VERSION "dbc-export 1 2026.26.6.5"

NS_ :

BS_:

BU_: APP BMS CC CMP CMPD CP DAS DI DIF DIR EPBL EPBR EVSE FC GTW HCML HCMR HVP ICR PCS PCS2 PM PMF PMR PTC SCCM SDCR TAS UMC V2G VC VCBATT VCBATT1 VCBATT2 VCFRONT VCFRONT1 VCLEFT VCRIGHT VCSEC

BO_ 537 VCSEC_TPMSData: 7 VCSEC
 SG_ VCSEC_TPMSDataIndex M : 0|3@1+ (1,0) [0|7] "" Vector__XXX
 SG_ VCSEC_TPMSCapabilityPressureInAd m0 : 3|1@1+ (1,0) [0|1] "" Vector__XXX
 SG_ VCSEC_TPMSCapabilityConfigurable m0 : 4|1@1+ (1,0) [0|1] "" Vector__XXX
 SG_ VCSEC_TPMSPressureRateOfChange0 m0 : 5|10@1- (0.02,0) [-10.24|10.22] "kPa/S" Vector__XXX
 SG_ VCSEC_TPMSPressure0 m0 : 15|9@1+ (0.025,0) [0|12.75] "bar" Vector__XXX
 SG_ VCSEC_TPMSTemperature0 m0 : 24|8@1+ (1,-40) [-40|214] "degC" Vector__XXX
 SG_ VCSEC_TPMSBatVoltage0 m0 : 32|8@1+ (0.01,1.5) [1.5|4.04] "V" Vector__XXX
 SG_ VCSEC_TPMSLocation0 m0 : 40|3@1+ (1,0) [0|7] "" Vector__XXX
 SG_ VCSEC_TPMSTemperatureCompensated m0 : 43|9@1+ (0.025,0) [0|12.75] "bar" Vector__XXX
 SG_ VCSEC_TPMSCapabilityPressur_0001 m1 : 3|1@1+ (1,0) [0|1] "" Vector__XXX
 SG_ VCSEC_TPMSCapabilityConfigu_0001 m1 : 4|1@1+ (1,0) [0|1] "" Vector__XXX
 SG_ VCSEC_TPMSPressureRateOfChange1 m1 : 5|10@1- (0.02,0) [-10.24|10.22] "kPa/S" Vector__XXX
 SG_ VCSEC_TPMSPressure1 m1 : 15|9@1+ (0.025,0) [0|12.75] "bar" Vector__XXX
 SG_ VCSEC_TPMSTemperature1 m1 : 24|8@1+ (1,-40) [-40|214] "degC" Vector__XXX
 SG_ VCSEC_TPMSBatVoltage1 m1 : 32|8@1+ (0.01,1.5) [1.5|4.04] "V" Vector__XXX
 SG_ VCSEC_TPMSLocation1 m1 : 40|3@1+ (1,0) [0|7] "" Vector__XXX
 SG_ VCSEC_TPMSTemperatureCompen_0001 m1 : 43|9@1+ (0.025,0) [0|12.75] "bar" Vector__XXX
 SG_ VCSEC_TPMSCapabilityPressur_0002 m2 : 3|1@1+ (1,0) [0|1] "" Vector__XXX
 SG_ VCSEC_TPMSCapabilityConfigu_0002 m2 : 4|1@1+ (1,0) [0|1] "" Vector__XXX
 SG_ VCSEC_TPMSPressureRateOfChange2 m2 : 5|10@1- (0.02,0) [-10.24|10.22] "kPa/S" Vector__XXX
 SG_ VCSEC_TPMSPressure2 m2 : 15|9@1+ (0.025,0) [0|12.75] "bar" Vector__XXX
 SG_ VCSEC_TPMSTemperature2 m2 : 24|8@1+ (1,-40) [-40|214] "degC" Vector__XXX
 SG_ VCSEC_TPMSBatVoltage2 m2 : 32|8@1+ (0.01,1.5) [1.5|4.04] "V" Vector__XXX
 SG_ VCSEC_TPMSLocation2 m2 : 40|3@1+ (1,0) [0|7] "" Vector__XXX
 SG_ VCSEC_TPMSTemperatureCompen_0002 m2 : 43|9@1+ (0.025,0) [0|12.75] "bar" Vector__XXX
 SG_ VCSEC_TPMSCapabilityPressur_0003 m3 : 3|1@1+ (1,0) [0|1] "" Vector__XXX
 SG_ VCSEC_TPMSCapabilityConfigu_0003 m3 : 4|1@1+ (1,0) [0|1] "" Vector__XXX
 SG_ VCSEC_TPMSPressureRateOfChange3 m3 : 5|10@1- (0.02,0) [-10.24|10.22] "kPa/S" Vector__XXX
 SG_ VCSEC_TPMSPressure3 m3 : 15|9@1+ (0.025,0) [0|12.75] "bar" Vector__XXX
 SG_ VCSEC_TPMSTemperature3 m3 : 24|8@1+ (1,-40) [-40|214] "degC" Vector__XXX
 SG_ VCSEC_TPMSBatVoltage3 m3 : 32|8@1+ (0.01,1.5) [1.5|4.04] "V" Vector__XXX
 SG_ VCSEC_TPMSLocation3 m3 : 40|3@1+ (1,0) [0|7] "" Vector__XXX
 SG_ VCSEC_TPMSTemperatureCompen_0003 m3 : 43|9@1+ (0.025,0) [0|12.75] "bar" Vector__XXX
 SG_ VCSEC_TPMSRecommendedColdPressur m4 : 8|8@1+ (0.025,0) [0|6.35] "bar" Vector__XXX
 SG_ VCSEC_TPMSRecommendedColdPr_0001 m4 : 16|8@1+ (0.025,0) [0|6.35] "bar" Vector__XXX
 SG_ VCSEC_TPMSFeature0 m4 : 24|3@1+ (1,0) [0|7] "" Vector__XXX
 SG_ VCSEC_TPMSFeature1 m4 : 27|3@1+ (1,0) [0|7] "" Vector__XXX
 SG_ VCSEC_TPMSFeature0Count m4 : 32|4@1+ (1,0) [0|15] "" Vector__XXX
 SG_ VCSEC_TPMSFeature0TimeS m4 : 36|11@1+ (1,0) [0|2047] "" Vector__XXX
 SG_ VCSEC_TPMSAutonomyStatus m5 : 3|2@1+ (1,0) [0|3] "" Vector__XXX
 SG_ VCSEC_TPMSAutonomyStatusMIATimeS m5 : 5|9@1+ (1,0) [0|511] "" Vector__XXX
 SG_ VCSEC_TPMSLastKnownPressureFL m5 : 16|8@1+ (0.025,0) [0|6.35] "bar" Vector__XXX
 SG_ VCSEC_TPMSLastKnownPressureFR m5 : 24|8@1+ (0.025,0) [0|6.35] "bar" Vector__XXX
 SG_ VCSEC_TPMSLastKnownPressureRL m5 : 32|8@1+ (0.025,0) [0|6.35] "bar" Vector__XXX
 SG_ VCSEC_TPMSLastKnownPressureRR m5 : 40|8@1+ (0.025,0) [0|6.35] "bar" Vector__XXX

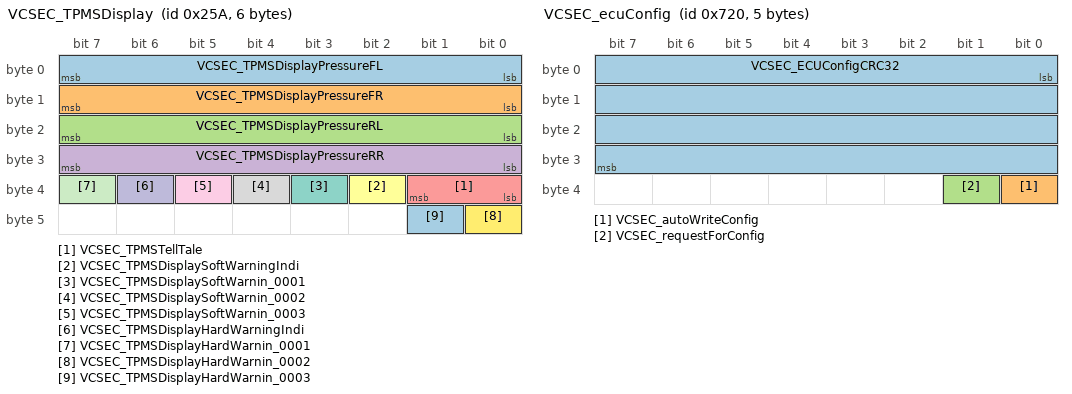
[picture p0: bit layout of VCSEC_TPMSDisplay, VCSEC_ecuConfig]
BO_ 602 VCSEC_TPMSDisplay: 6 VCSEC
 SG_ VCSEC_TPMSDisplayPressureFL : 0|8@1+ (0.025,0) [0|6.35] "bar" Vector__XXX
 SG_ VCSEC_TPMSDisplayPressureFR : 8|8@1+ (0.025,0) [0|6.35] "bar" Vector__XXX
 SG_ VCSEC_TPMSDisplayPressureRL : 16|8@1+ (0.025,0) [0|6.35] "bar" Vector__XXX
 SG_ VCSEC_TPMSDisplayPressureRR : 24|8@1+ (0.025,0) [0|6.35] "bar" Vector__XXX
 SG_ VCSEC_TPMSTellTale : 32|2@1+ (1,0) [0|3] "" Vector__XXX
 SG_ VCSEC_TPMSDisplaySoftWarningIndi : 34|1@1+ (1,0) [0|1] "" Vector__XXX
 SG_ VCSEC_TPMSDisplaySoftWarnin_0001 : 35|1@1+ (1,0) [0|1] "" Vector__XXX
 SG_ VCSEC_TPMSDisplaySoftWarnin_0002 : 36|1@1+ (1,0) [0|1] "" Vector__XXX
 SG_ VCSEC_TPMSDisplaySoftWarnin_0003 : 37|1@1+ (1,0) [0|1] "" Vector__XXX
 SG_ VCSEC_TPMSDisplayHardWarningIndi : 38|1@1+ (1,0) [0|1] "" Vector__XXX
 SG_ VCSEC_TPMSDisplayHardWarnin_0001 : 39|1@1+ (1,0) [0|1] "" Vector__XXX
 SG_ VCSEC_TPMSDisplayHardWarnin_0002 : 40|1@1+ (1,0) [0|1] "" Vector__XXX
 SG_ VCSEC_TPMSDisplayHardWarnin_0003 : 41|1@1+ (1,0) [0|1] "" Vector__XXX

BO_ 570 VCSEC_TPMSStatus: 8 VCSEC
 SG_ VCSEC_TPMSStatusIndex M : 0|6@1+ (1,0) [0|63] "" Vector__XXX
 SG_ VCSEC_TPMSSystemState : 6|1@1+ (1,0) [0|1] "" Vector__XXX
 SG_ VCSEC_TPMSSensorMACAddress0 m0 : 8|48@1+ (1,0) [0|281474976710655] "" Vector__XXX
 SG_ VCSEC_TPMSSensorMACAddress1 m1 : 8|48@1+ (1,0) [0|281474976710655] "" Vector__XXX
 SG_ VCSEC_TPMSSensorMACAddress2 m2 : 8|48@1+ (1,0) [0|281474976710655] "" Vector__XXX
 SG_ VCSEC_TPMSSensorMACAddress3 m3 : 8|48@1+ (1,0) [0|281474976710655] "" Vector__XXX
 SG_ VCSEC_BLEUnsuccessfulConnEventRa m5 : 8|10@1+ (0.08,0) [0|81.76] "%" Vector__XXX
 SG_ VCSEC_BLEUnsuccessfulConnEv_0001 m7 : 8|10@1+ (0.08,0) [0|81.76] "%" Vector__XXX
 SG_ VCSEC_BLEUnsuccessfulConnEv_0002 m9 : 8|10@1+ (0.08,0) [0|81.76] "%" Vector__XXX
 SG_ VCSEC_BLEUnsuccessfulConnEv_0003 m11 : 8|10@1+ (0.08,0) [0|81.76] "%" Vector__XXX
 SG_ VCSEC_TPMSSensorTIAppCRC0 m12 : 8|32@1+ (1,0) [1|4294967295] "" Vector__XXX
 SG_ VCSEC_TPMSSensorMLXAppCRC0 m12 : 40|24@1+ (1,0) [1|16777215] "" Vector__XXX
 SG_ VCSEC_TPMSSensorTIAppCRC1 m13 : 8|32@1+ (1,0) [1|4294967295] "" Vector__XXX
 SG_ VCSEC_TPMSSensorMLXAppCRC1 m13 : 40|24@1+ (1,0) [1|16777215] "" Vector__XXX
 SG_ VCSEC_TPMSSensorTIAppCRC2 m14 : 8|32@1+ (1,0) [1|4294967295] "" Vector__XXX
 SG_ VCSEC_TPMSSensorMLXAppCRC2 m14 : 40|24@1+ (1,0) [1|16777215] "" Vector__XXX
 SG_ VCSEC_TPMSSensorTIAppCRC3 m15 : 8|32@1+ (1,0) [1|4294967295] "" Vector__XXX
 SG_ VCSEC_TPMSSensorMLXAppCRC3 m15 : 40|24@1+ (1,0) [1|16777215] "" Vector__XXX
 SG_ VCSEC_TPMStotalAwakeTime0 m20 : 8|32@1+ (1,0) [0|4294967295] "" Vector__XXX
 SG_ VCSEC_TPMSTrimAdjusted0 m20 : 40|1@1+ (1,0) [0|1] "" Vector__XXX
 SG_ VCSEC_TPMSGenealogySensorState0 m20 : 41|3@1+ (1,0) [0|7] "" Vector__XXX
 SG_ VCSEC_TPMSSensorType0 m20 : 44|3@1+ (1,0) [0|7] "" Vector__XXX
 SG_ VCSEC_TPMStotalAwakeTime1 m21 : 8|32@1+ (1,0) [0|4294967295] "" Vector__XXX
 SG_ VCSEC_TPMSTrimAdjusted1 m21 : 40|1@1+ (1,0) [0|1] "" Vector__XXX
 SG_ VCSEC_TPMSGenealogySensorState1 m21 : 41|3@1+ (1,0) [0|7] "" Vector__XXX
 SG_ VCSEC_TPMSSensorType1 m21 : 44|3@1+ (1,0) [0|7] "" Vector__XXX
 SG_ VCSEC_TPMStotalAwakeTime2 m22 : 8|32@1+ (1,0) [0|4294967295] "" Vector__XXX
 SG_ VCSEC_TPMSTrimAdjusted2 m22 : 40|1@1+ (1,0) [0|1] "" Vector__XXX
 SG_ VCSEC_TPMSGenealogySensorState2 m22 : 41|3@1+ (1,0) [0|7] "" Vector__XXX
 SG_ VCSEC_TPMSSensorType2 m22 : 44|3@1+ (1,0) [0|7] "" Vector__XXX
 SG_ VCSEC_TPMStotalAwakeTime3 m23 : 8|32@1+ (1,0) [0|4294967295] "" Vector__XXX
 SG_ VCSEC_TPMSTrimAdjusted3 m23 : 40|1@1+ (1,0) [0|1] "" Vector__XXX
 SG_ VCSEC_TPMSGenealogySensorState3 m23 : 41|3@1+ (1,0) [0|7] "" Vector__XXX
 SG_ VCSEC_TPMSSensorType3 m23 : 44|3@1+ (1,0) [0|7] "" Vector__XXX
 SG_ VCSEC_TPMSSensor0Hash m33 : 8|28@1+ (1,0) [0|268435455] "" Vector__XXX
 SG_ VCSEC_TPMSSensor1Hash m33 : 36|28@1+ (1,0) [0|268435455] "" Vector__XXX
 SG_ VCSEC_TPMSSensor2Hash m34 : 8|28@1+ (1,0) [0|268435455] "" Vector__XXX
 SG_ VCSEC_TPMSSensor3Hash m34 : 36|28@1+ (1,0) [0|268435455] "" Vector__XXX
 SG_ VCSEC_TPMSLastLocationSensor0 m35 : 8|3@1+ (1,0) [0|7] "" Vector__XXX
 SG_ VCSEC_TPMSLastLocationSensor1 m35 : 11|3@1+ (1,0) [0|7] "" Vector__XXX
 SG_ VCSEC_TPMSLastLocationSensor2 m35 : 16|3@1+ (1,0) [0|7] "" Vector__XXX
 SG_ VCSEC_TPMSLastLocationSensor3 m35 : 19|3@1+ (1,0) [0|7] "" Vector__XXX
 SG_ VCSEC_TPMSTemperatureCompensated m36 : 8|8@1+ (0.01,1.5) [1.5|4.04] "V" Vector__XXX
 SG_ VCSEC_TPMSTemperatureCompen_0001 m36 : 16|8@1+ (0.01,1.5) [1.5|4.04] "V" Vector__XXX
 SG_ VCSEC_TPMSTemperatureCompen_0002 m36 : 24|8@1+ (0.01,1.5) [1.5|4.04] "V" Vector__XXX
 SG_ VCSEC_TPMSTemperatureCompen_0003 m36 : 32|8@1+ (0.01,1.5) [1.5|4.04] "V" Vector__XXX
 SG_ VCSEC_TPMSFilteredBatVoltage0 m37 : 8|8@1+ (0.01,1.5) [1.5|4.04] "V" Vector__XXX
 SG_ VCSEC_TPMSFilteredBatVoltage2 m37 : 16|8@1+ (0.01,1.5) [1.5|4.04] "V" Vector__XXX
 SG_ VCSEC_TPMSFilteredBatVoltage1 m37 : 24|8@1+ (0.01,1.5) [1.5|4.04] "V" Vector__XXX
 SG_ VCSEC_TPMSFilteredBatVoltage3 m37 : 32|8@1+ (0.01,1.5) [1.5|4.04] "V" Vector__XXX

BO_ 1067 VCSEC_UWBData: 8 VCSEC
 SG_ VCSEC_UWBEndpointIndex M : 0|3@1+ (1,0) [0|7] "" Vector__XXX
 SG_ VCSEC_UWBExpectedEndpointsActive m0 : 3|4@1+ (1,0) [0|15] "" Vector__XXX
 SG_ VCSEC_UWBExpectedEndpointsA_0001 m0 : 8|4@1+ (1,0) [0|15] "" Vector__XXX
 SG_ VCSEC_UWBExpectedEndpointsA_0002 m0 : 12|4@1+ (1,0) [0|15] "" Vector__XXX
 SG_ VCSEC_UWBExpectedEndpointsA_0003 m0 : 16|4@1+ (1,0) [0|15] "" Vector__XXX
 SG_ VCSEC_UWBRearRightDistance0 m0 : 20|12@1+ (1,0) [0|4094] "cm" Vector__XXX
 SG_ VCSEC_UWBRearRightDistance1 m0 : 32|12@1+ (1,0) [0|4094] "cm" Vector__XXX
 SG_ VCSEC_UWBRearRightDistance2 m0 : 44|12@1+ (1,0) [0|4094] "cm" Vector__XXX
 SG_ VCSEC_UWBLeftDistance3 m1 : 3|12@1+ (1,0) [0|4094] "cm" Vector__XXX
 SG_ VCSEC_UWBRightDistance3 m1 : 16|12@1+ (1,0) [0|4094] "cm" Vector__XXX
 SG_ VCSEC_UWBRearRightDistance3 m1 : 28|12@1+ (1,0) [0|4094] "cm" Vector__XXX
 SG_ VCSEC_UWBRearLeftDistance3 m1 : 40|12@1+ (1,0) [0|4094] "cm" Vector__XXX
 SG_ VCSEC_UWBCenterDistance3 m1 : 52|12@1+ (1,0) [0|4094] "cm" Vector__XXX
 SG_ VCSEC_UWBLeftDistance2 m2 : 3|12@1+ (1,0) [0|4094] "cm" Vector__XXX
 SG_ VCSEC_UWBRightDistance2 m2 : 16|12@1+ (1,0) [0|4094] "cm" Vector__XXX
 SG_ VCSEC_UWBRearDistance2 m2 : 28|12@1+ (1,0) [0|4094] "cm" Vector__XXX
 SG_ VCSEC_UWBRearLeftDistance2 m2 : 40|12@1+ (1,0) [0|4094] "cm" Vector__XXX
 SG_ VCSEC_UWBCenterDistance2 m2 : 52|12@1+ (1,0) [0|4094] "cm" Vector__XXX
 SG_ VCSEC_UWBLeftDistance1 m3 : 3|12@1+ (1,0) [0|4094] "cm" Vector__XXX
 SG_ VCSEC_UWBRightDistance1 m3 : 16|12@1+ (1,0) [0|4094] "cm" Vector__XXX
 SG_ VCSEC_UWBRearDistance1 m3 : 28|12@1+ (1,0) [0|4094] "cm" Vector__XXX
 SG_ VCSEC_UWBRearLeftDistance1 m3 : 40|12@1+ (1,0) [0|4094] "cm" Vector__XXX
 SG_ VCSEC_UWBCenterDistance1 m3 : 52|12@1+ (1,0) [0|4094] "cm" Vector__XXX
 SG_ VCSEC_UWBLeftDistance0 m4 : 3|12@1+ (1,0) [0|4094] "cm" Vector__XXX
 SG_ VCSEC_UWBRightDistance0 m4 : 16|12@1+ (1,0) [0|4094] "cm" Vector__XXX
 SG_ VCSEC_UWBRearDistance0 m4 : 28|12@1+ (1,0) [0|4094] "cm" Vector__XXX
 SG_ VCSEC_UWBRearLeftDistance0 m4 : 40|12@1+ (1,0) [0|4094] "cm" Vector__XXX
 SG_ VCSEC_UWBCenterDistance0 m4 : 52|12@1+ (1,0) [0|4094] "cm" Vector__XXX

BO_ 761 VCSEC_additionalAuthInfo: 8 VCSEC
 SG_ VCSEC_activeKeyDebug : 2|5@1+ (1,0) [0|31] "" Vector__XXX
 SG_ VCSEC_bleChannelDisconnected : 7|4@1+ (1,0) [0|15] "" Vector__XXX
 SG_ VCSEC_bleDisconnectionReason : 11|8@1+ (1,0) [0|255] "" Vector__XXX
 SG_ VCSEC_bleConnetionAttemptWLEntry : 19|5@1+ (1,0) [0|31] "" Vector__XXX
 SG_ VCSEC_AdditionalAuthInfoIndex M : 27|3@1+ (1,0) [0|7] "" Vector__XXX
 SG_ VCSEC_activeKeyReason m0 : 24|3@1+ (1,0) [0|7] "" Vector__XXX
 SG_ VCSEC_activeKeySHA1 m0 : 32|32@1+ (1,0) [0|4294967295] "" Vector__XXX
 SG_ VCSEC_algoUsedForSummonRange0 m1 : 0|1@1+ (1,0) [0|1] "" Vector__XXX
 SG_ VCSEC_keyWithinSummonRange0 m1 : 32|32@1+ (1,0) [0|4294967295] "" Vector__XXX
 SG_ VCSEC_algoUsedForSummonRange1 m2 : 0|1@1+ (1,0) [0|1] "" Vector__XXX
 SG_ VCSEC_keyWithinSummonRange1 m2 : 32|32@1+ (1,0) [0|4294967295] "" Vector__XXX
 SG_ VCSEC_algoUsedForSummonRange2 m3 : 0|1@1+ (1,0) [0|1] "" Vector__XXX
 SG_ VCSEC_keyWithinSummonRange2 m3 : 32|32@1+ (1,0) [0|4294967295] "" Vector__XXX
 SG_ VCSEC_BLEDeviceWithinSummonRange m4 : 32|32@1+ (1,0) [0|4294967295] "" Vector__XXX
 SG_ VCSEC_algoUWBInteriorPresence m5 : 0|1@1+ (1,0) [0|1] "" Vector__XXX
 SG_ VCSEC_frunkOpenSuggestionRespons m5 : 24|3@1+ (1,0) [0|7] "" Vector__XXX
 SG_ VCSEC_NFCAuthFromBPillarFormFact m5 : 32|3@1+ (1,0) [0|7] "" Vector__XXX
 SG_ VCSEC_NFCAuthFromCenterConsoleFo m5 : 35|3@1+ (1,0) [0|7] "" Vector__XXX
 SG_ VCSEC_trunkOpenSuggestionRespons m5 : 40|3@1+ (1,0) [0|7] "" Vector__XXX
 SG_ VCSEC_algoTrunkSuggestionRaw m5 : 43|1@1+ (1,0) [0|1] "" Vector__XXX
 SG_ VCSEC_algoTrunkSuggestionProc m5 : 44|1@1+ (1,0) [0|1] "" Vector__XXX
 SG_ VCSEC_algoTrunkSuggestionRearmAl m5 : 45|1@1+ (1,0) [0|1] "" Vector__XXX
 SG_ VCSEC_algoFrunkSuggestionRaw m5 : 46|1@1+ (1,0) [0|1] "" Vector__XXX
 SG_ VCSEC_algoFrunkSuggestionProc m5 : 47|1@1+ (1,0) [0|1] "" Vector__XXX
 SG_ VCSEC_algoFrunkSuggestionRearmAl m5 : 48|1@1+ (1,0) [0|1] "" Vector__XXX

BO_ 825 VCSEC_authentication: 8 VCSEC
 SG_ VCSEC_BLEConnectionCounter : 0|4@1+ (1,0) [0|15] "" Vector__XXX
 SG_ VCSEC_authRejectionReason : 4|3@1+ (1,0) [0|7] "" Vector__XXX
 SG_ VCSEC_IDRequested : 7|1@1+ (1,0) [0|1] "" Vector__XXX
 SG_ VCSEC_operationMode : 8|2@1+ (1,0) [0|3] "" Vector__XXX
 SG_ VCSEC_vehicleLockStatus : 12|4@1+ (1,0) [1|15] "" Vector__XXX
 SG_ VCSEC_authenticationStatus : 16|2@1+ (1,0) [0|3] "" Vector__XXX
 SG_ VCSEC_chargePortLockStatus : 18|1@1+ (1,0) [0|1] "" Vector__XXX
 SG_ VCSEC_leftFrontLockStatus : 19|1@1+ (1,0) [0|1] "" Vector__XXX
 SG_ VCSEC_leftRearLockStatus : 20|1@1+ (1,0) [0|1] "" Vector__XXX
 SG_ VCSEC_rightFrontLockStatus : 21|1@1+ (1,0) [0|1] "" Vector__XXX
 SG_ VCSEC_rightRearLockStatus : 22|1@1+ (1,0) [0|1] "" Vector__XXX
 SG_ VCSEC_trunkLockStatus : 23|1@1+ (1,0) [0|1] "" Vector__XXX
 SG_ VCSEC_lockRequestType : 24|5@1+ (1,0) [0|31] "" Vector__XXX
 SG_ VCSEC_summonRequest : 29|3@1+ (1,0) [0|7] "" Vector__XXX
 SG_ VCSEC_3rdPartyPLGRequest : 32|2@1+ (1,0) [0|2] "" Vector__XXX
 SG_ VCSEC_3rdPartyFrunkPLGRequest : 34|2@1+ (1,0) [0|2] "" Vector__XXX
 SG_ VCSEC_MCUCommandType : 36|3@1+ (1,0) [0|7] "" Vector__XXX
 SG_ VCSEC_frunkLockStatus : 39|1@1+ (1,0) [0|1] "" Vector__XXX
 SG_ VCSEC_usingModifiedMACAddress : 40|1@1+ (1,0) [0|1] "" Vector__XXX
 SG_ VCSEC_isKeyWithinSummonRange : 41|1@1+ (1,0) [0|1] "" Vector__XXX
 SG_ VCSEC_isBLEDeviceWithinSummonRan : 42|1@1+ (1,0) [0|1] "" Vector__XXX
 SG_ VCSEC_alarmStatus : 43|4@1+ (1,0) [0|14] "" Vector__XXX
 SG_ VCSEC_serviceDiagnosticRequest : 47|1@1+ (1,0) [0|1] "" Vector__XXX
 SG_ VCSEC_immobilizerState : 48|3@1+ (1,0) [0|7] "" Vector__XXX
 SG_ VCSEC_lockIndicationRequest : 51|3@1+ (1,0) [1|7] "" Vector__XXX
 SG_ VCSEC_simpleLockStatus : 54|2@1+ (1,0) [1|3] "" Vector__XXX
 SG_ VCSEC_keyChannelIndexed : 56|4@1+ (1,0) [0|14] "" Vector__XXX
 SG_ VCSEC_authRequested : 60|1@1+ (1,0) [0|1] "" Vector__XXX
 SG_ VCSEC_remoteStartActive : 61|2@1+ (1,0) [0|3] "" Vector__XXX
 SG_ VCSEC_keyPairDesired : 63|1@1+ (1,0) [0|1] "" Vector__XXX

BO_ 1817 VCSEC_debug100ms: 8 VCSEC
 SG_ VCSEC_debug100msIndex M : 0|5@1+ (1,0) [0|31] "" Vector__XXX
 SG_ VCSEC_walkAwayLockKeyState m0 : 5|2@1+ (1,0) [0|3] "" Vector__XXX
 SG_ VCSEC_thresholdOffsetVersion m0 : 8|3@1+ (1,0) [0|7] "" Vector__XXX
 SG_ VCSEC_walkAwayLockState m0 : 11|3@1+ (1,0) [0|7] "" Vector__XXX
 SG_ VCSEC_rssi0WLEntry m0 : 16|5@1+ (1,0) [0|31] "" Vector__XXX
 SG_ VCSEC_endpointLayout m0 : 21|2@1+ (1,0) [0|3] "" Vector__XXX
 SG_ VCSEC_rssi1WLEntry m0 : 24|5@1+ (1,0) [0|31] "" Vector__XXX
 SG_ VCSEC_rssi2WLEntry m0 : 32|5@1+ (1,0) [0|31] "" Vector__XXX
 SG_ VCSEC_walkUpUnlockState m0 : 37|3@1+ (1,0) [0|7] "" Vector__XXX
 SG_ VCSEC_algoHighThreshLeft m0 : 40|1@1+ (1,0) [0|1] "" Vector__XXX
 SG_ VCSEC_algoHighThreshRight m0 : 41|1@1+ (1,0) [0|1] "" Vector__XXX
 SG_ VCSEC_algoHighThreshCenter m0 : 42|1@1+ (1,0) [0|1] "" Vector__XXX
 SG_ VCSEC_pollingReason m0 : 43|4@1+ (1,0) [0|15] "" Vector__XXX
 SG_ VCSEC_numberOfPubKeysOnWhitelist m0 : 48|5@1+ (1,0) [0|31] "" Vector__XXX
 SG_ VCSEC_thermalDetectState m0 : 53|2@1+ (1,0) [0|3] "" Vector__XXX
 SG_ VCSEC_chargeHandleMitigationActi m0 : 55|1@1+ (1,0) [0|1] "" Vector__XXX
 SG_ VCSEC_smartTrunkMitigatedKeyCoun m5 : 8|5@1+ (1,0) [0|31] "" Vector__XXX
 SG_ VCSEC_UWB3WLEntry m5 : 21|5@1+ (1,0) [0|31] "" Vector__XXX
 SG_ VCSEC_device0Offset m5 : 26|6@1- (0.5,0) [-16|15.5] "dBm" Vector__XXX
 SG_ VCSEC_device1Offset m5 : 32|6@1- (0.5,0) [-16|15.5] "dBm" Vector__XXX
 SG_ VCSEC_device2Offset m5 : 40|6@1- (0.5,0) [-16|15.5] "dBm" Vector__XXX
 SG_ VCSEC_connection0BondingState m7 : 8|4@1+ (1,0) [0|15] "" Vector__XXX
 SG_ VCSEC_connection1BondingState m7 : 12|4@1+ (1,0) [0|15] "" Vector__XXX
 SG_ VCSEC_connection2BondingState m7 : 16|4@1+ (1,0) [0|15] "" Vector__XXX
 SG_ VCSEC_connection0UWBAvailability m7 : 24|5@1+ (1,0) [0|31] "" Vector__XXX
 SG_ VCSEC_connection1UWBAvailability m7 : 32|5@1+ (1,0) [0|31] "" Vector__XXX
 SG_ VCSEC_connection2UWBAvailability m7 : 40|5@1+ (1,0) [0|31] "" Vector__XXX
 SG_ VCSEC_NISessionStateCenter0 m8 : 8|5@1+ (1,0) [0|31] "" Vector__XXX
 SG_ VCSEC_NISessionStateLeft0 m8 : 16|5@1+ (1,0) [0|31] "" Vector__XXX
 SG_ VCSEC_NISessionStateRight0 m8 : 24|5@1+ (1,0) [0|31] "" Vector__XXX
 SG_ VCSEC_NISessionStateRearLeft0 m8 : 29|5@1+ (1,0) [0|31] "" Vector__XXX
 SG_ VCSEC_NISessionStateRearRight0 m8 : 34|5@1+ (1,0) [0|31] "" Vector__XXX
 SG_ VCSEC_NISessionStateRear0 m8 : 39|5@1+ (1,0) [0|31] "" Vector__XXX
 SG_ VCSEC_NISessionStateCenter1 m8 : 44|5@1+ (1,0) [0|31] "" Vector__XXX
 SG_ VCSEC_NISessionStateLeft1 m8 : 49|5@1+ (1,0) [0|31] "" Vector__XXX
 SG_ VCSEC_NISessionStateRight1 m8 : 54|5@1+ (1,0) [0|31] "" Vector__XXX
 SG_ VCSEC_NISessionStateRearLeft1 m8 : 59|5@1+ (1,0) [0|31] "" Vector__XXX
 SG_ VCSEC_NISessionStateRearRight1 m9 : 8|5@1+ (1,0) [0|31] "" Vector__XXX
 SG_ VCSEC_NISessionStateRear1 m9 : 16|5@1+ (1,0) [0|31] "" Vector__XXX
 SG_ VCSEC_NISessionStateCenter2 m9 : 24|5@1+ (1,0) [0|31] "" Vector__XXX
 SG_ VCSEC_NISessionStateLeft2 m9 : 32|5@1+ (1,0) [0|31] "" Vector__XXX
 SG_ VCSEC_NISessionStateRight2 m9 : 40|5@1+ (1,0) [0|31] "" Vector__XXX
 SG_ VCSEC_NISessionStateRearLeft2 m9 : 48|5@1+ (1,0) [0|31] "" Vector__XXX
 SG_ VCSEC_NISessionStateRearRight2 m9 : 53|5@1+ (1,0) [0|31] "" Vector__XXX
 SG_ VCSEC_NISessionStateRear2 m9 : 58|5@1+ (1,0) [0|31] "" Vector__XXX
 SG_ VCSEC_NISessionStateLeft3 m10 : 8|5@1+ (1,0) [0|31] "" Vector__XXX
 SG_ VCSEC_NISessionStateRight3 m10 : 16|5@1+ (1,0) [0|31] "" Vector__XXX
 SG_ VCSEC_NISessionStateRearRight3 m10 : 24|5@1+ (1,0) [0|31] "" Vector__XXX
 SG_ VCSEC_NISessionStateRearLeft3 m10 : 32|5@1+ (1,0) [0|31] "" Vector__XXX
 SG_ VCSEC_NISessionStateCenter3 m10 : 40|5@1+ (1,0) [0|31] "" Vector__XXX

BO_ 1824 VCSEC_ecuConfig: 5 VCSEC
 SG_ VCSEC_ECUConfigCRC32 : 0|32@1+ (1,0) [0|4294967295] "" Vector__XXX
 SG_ VCSEC_autoWriteConfig : 32|1@1+ (1,0) [0|1] "" Vector__XXX
 SG_ VCSEC_requestForConfig : 33|1@1+ (1,0) [0|1] "" Vector__XXX

BO_ 793 VCSEC_info: 8 VCSEC
 SG_ VCSEC_infoIndex M : 0|8@1+ (1,0) [0|255] "" Vector__XXX
 SG_ VCSEC_infoBuildType m10 : 8|3@1+ (1,0) [0|7] "" Vector__XXX
 SG_ VCSEC_infoBuildConfigId m10 : 16|16@1+ (1,0) [0|65535] "" Vector__XXX
 SG_ VCSEC_infoHardwareId m10 : 32|16@1+ (1,0) [0|65535] "" Vector__XXX
 SG_ VCSEC_infoComponentId m10 : 48|16@1+ (1,0) [0|65535] "" Vector__XXX
 SG_ VCSEC_infoPcbaId m11 : 8|8@1+ (1,0) [0|255] "" Vector__XXX
 SG_ VCSEC_infoAssemblyId m11 : 16|8@1+ (1,0) [0|254] "" Vector__XXX
 SG_ VCSEC_infoUsageId m11 : 32|16@1+ (1,0) [0|65535] "" Vector__XXX
 SG_ VCSEC_infoSubUsageId m11 : 48|16@1+ (1,0) [0|65535] "" Vector__XXX
 SG_ VCSEC_infoAppCrc m13 : 32|32@1+ (1,0) [0|4294967295] "" Vector__XXX
 SG_ VCSEC_infoSubcomponent1 m16 : 32|32@1+ (1,0) [0|4294967295] "" Vector__XXX
 SG_ VCSEC_infoAppGitHash m17 : 8|56@1+ (1,0) [0|7.20575940379e+16] "" Vector__XXX
 SG_ VCSEC_infoBootGitHash m18 : 8|56@1+ (1,0) [0|7.20575940379e+16] "" Vector__XXX
 SG_ VCSEC_infoPlatformType m19 : 8|8@1+ (1,0) [0|255] "" Vector__XXX
 SG_ VCSEC_infoBootUdsProtoVersion m20 : 8|16@1+ (1,0) [0|65535] "" Vector__XXX
 SG_ VCSEC_infoBootCrc m20 : 24|32@1+ (1,0) [0|4294967295] "" Vector__XXX
 SG_ VCSEC_infoSubcomponent2 m23 : 32|32@1+ (1,0) [0|4294967295] "" Vector__XXX
 SG_ VCSEC_infoSubcomponent3 m24 : 32|32@1+ (1,0) [0|4294967295] "" Vector__XXX
 SG_ VCSEC_infoSubcomponent4 m31 : 32|32@1+ (1,0) [0|4294967295] "" Vector__XXX

BO_ 505 VCSEC_requests: 8 VCSEC
 SG_ VCSEC_chargePortRequest : 0|2@1+ (1,0) [0|2] "" Vector__XXX
 SG_ VCSEC_presentHandles : 4|1@1+ (1,0) [0|1] "" Vector__XXX
 SG_ VCSEC_frontLeftClosureRequest : 5|3@1+ (1,0) [0|7] "" Vector__XXX
 SG_ VCSEC_frontRightClosureRequest : 8|3@1+ (1,0) [0|7] "" Vector__XXX
 SG_ VCSEC_rearLeftClosureRequest : 11|3@1+ (1,0) [0|7] "" Vector__XXX
 SG_ VCSEC_rearRightClosureRequest : 14|3@1+ (1,0) [0|7] "" Vector__XXX
 SG_ VCSEC_rearTrunkClosureRequest : 17|3@1+ (1,0) [0|7] "" Vector__XXX
 SG_ VCSEC_frontLeftRequestReason : 20|3@1+ (1,0) [0|7] "" Vector__XXX
 SG_ VCSEC_frontRightRequestReason : 23|3@1+ (1,0) [0|7] "" Vector__XXX
 SG_ VCSEC_rearLeftRequestReason : 26|3@1+ (1,0) [0|7] "" Vector__XXX
 SG_ VCSEC_rearRightRequestReason : 29|3@1+ (1,0) [0|7] "" Vector__XXX
 SG_ VCSEC_rearTrunkRequestReason : 32|3@1+ (1,0) [0|7] "" Vector__XXX
 SG_ VCSEC_rdMapDumpRequested : 35|1@1+ (1,0) [0|1] "" Vector__XXX
 SG_ VCSEC_driveAttemptedWithoutAuth : 36|4@1+ (1,0) [0|15] "" Vector__XXX
 SG_ VCSEC_closeAllStatus : 41|2@1+ (1,0) [0|3] "" Vector__XXX
 SG_ VCSEC_snapshotRequested : 43|4@1+ (1,0) [0|15] "" Vector__XXX
 SG_ VCSEC_chargeportRequestReason : 47|3@1+ (1,0) [0|7] "" Vector__XXX
 SG_ VCSEC_frontTrunkClosureRequest : 51|3@1+ (1,0) [0|7] "" Vector__XXX
 SG_ VCSEC_frontTrunkRequestReason : 54|3@1+ (1,0) [0|7] "" Vector__XXX

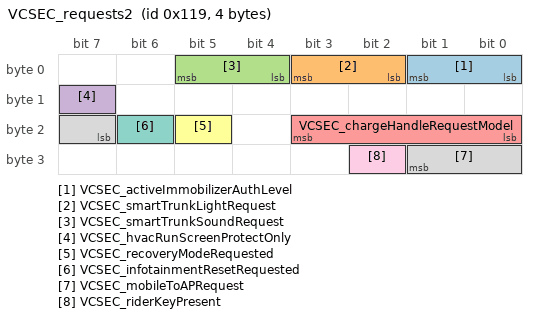
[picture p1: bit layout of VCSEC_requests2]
BO_ 281 VCSEC_requests2: 4 VCSEC
 SG_ VCSEC_activeImmobilizerAuthLevel : 0|2@1+ (1,0) [0|3] "" Vector__XXX
 SG_ VCSEC_smartTrunkLightRequest : 2|2@1+ (1,0) [0|3] "" Vector__XXX
 SG_ VCSEC_smartTrunkSoundRequest : 4|2@1+ (1,0) [0|3] "" Vector__XXX
 SG_ VCSEC_hvacRunScreenProtectOnly : 15|1@1+ (1,0) [0|1] "" Vector__XXX
 SG_ VCSEC_chargeHandleRequestModel : 16|4@1+ (1,0) [0|15] "" Vector__XXX
 SG_ VCSEC_recoveryModeRequested : 21|1@1+ (1,0) [0|1] "" Vector__XXX
 SG_ VCSEC_infotainmentResetRequested : 22|1@1+ (1,0) [0|1] "" Vector__XXX
 SG_ VCSEC_mobileToAPRequest : 23|3@1+ (1,0) [0|7] "" Vector__XXX
 SG_ VCSEC_riderKeyPresent : 26|1@1+ (1,0) [0|1] "" Vector__XXX

BO_ 1850 VC_LVBMS_brickMeasurements: 8 VC
 SG_ VC_LVBMS_brickMeasurementsMultip M : 0|6@1+ (1,0) [0|63] "" Vector__XXX
 SG_ VC_LVBMS_brickVoltage1 m0 : 8|13@1+ (0.001,0) [0|6.535] "V" Vector__XXX
 SG_ VC_LVBMS_brickVoltage2 m0 : 24|13@1+ (0.001,0) [0|6.535] "V" Vector__XXX
 SG_ VC_LVBMS_brickVoltage3 m0 : 37|13@1+ (0.001,0) [0|6.535] "V" Vector__XXX
 SG_ VC_LVBMS_brickVoltage4 m0 : 50|13@1+ (0.001,0) [0|6.535] "V" Vector__XXX
 SG_ VC_LVBMS_brickBalancingAh1 m1 : 8|24@1+ (0.001,0) [0|16777.214] "Ah" Vector__XXX
 SG_ VC_LVBMS_brickBalancingAh2 m1 : 32|24@1+ (0.001,0) [0|16777.214] "Ah" Vector__XXX
 SG_ VC_LVBMS_brickBalancingState1 m1 : 56|1@1+ (1,0) [0|1] "" Vector__XXX
 SG_ VC_LVBMS_brickBalancingState2 m1 : 57|1@1+ (1,0) [0|1] "" Vector__XXX
 SG_ VC_LVBMS_brickBalancingAh3 m2 : 8|24@1+ (0.001,0) [0|16777.214] "Ah" Vector__XXX
 SG_ VC_LVBMS_brickBalancingAh4 m2 : 32|24@1+ (0.001,0) [0|16777.214] "Ah" Vector__XXX
 SG_ VC_LVBMS_brickBalancingState3 m2 : 56|1@1+ (1,0) [0|1] "" Vector__XXX
 SG_ VC_LVBMS_brickBalancingState4 m2 : 57|1@1+ (1,0) [0|1] "" Vector__XXX

BO_ 1655 VC_LVBMS_statusHigh: 8 VC
 SG_ VC_lvbmsStatusHighIndex M : 0|3@1+ (1,0) [0|7] "" Vector__XXX
 SG_ VC_LVBMS_packCurrent m0 : 3|22@1+ (0.001,-2000) [-2000|2194.302] "A" Vector__XXX
 SG_ VC_LVBMS_packVoltage m0 : 25|16@1+ (0.001,0) [0|65.534] "V" Vector__XXX
 SG_ VC_LVBMS_packTemperature m0 : 41|9@1+ (0.5,-50) [-50|205] "degC" Vector__XXX
 SG_ VC_LVBMS_MOSTemperature m0 : 50|12@1+ (0.5,-50) [-50|1997] "degC" Vector__XXX
 SG_ VC_LVBMS_sumCellVoltage m1 : 8|16@1+ (0.001,0) [0|65.534] "V" Vector__XXX
 SG_ VC_LVBMS_maxBrickVoltage m1 : 24|13@1+ (0.001,0) [0|8.19] "V" Vector__XXX
 SG_ VC_LVBMS_maxBrickVoltageIndex m1 : 40|8@1+ (1,0) [0|254] "" Vector__XXX
 SG_ VC_totalLVLoadCurrent m2 : 8|14@1- (0.1,0) [-200|400] "A" Vector__XXX
 SG_ VC_LVPackChargeCurrentLimit m2 : 22|12@1+ (0.1,0) [0|400] "A" Vector__XXX
 SG_ VC_LVPackCurrent m2 : 34|14@1- (0.1,0) [-200|400] "A" Vector__XXX
 SG_ VC_LVBMS_estimatedPackOcv m2 : 48|16@1+ (0.001,0) [0|65.535] "V" Vector__XXX
 SG_ VC_LVBMS_voltageTarget m3 : 3|16@1+ (0.001,0) [0|65.534] "V" Vector__XXX
 SG_ VC_LVBMS_currentTarget m3 : 19|18@1+ (0.001,-122) [-120|120] "A" Vector__XXX
 SG_ VC_LVBMS_maxAllowedChargeCurrent m3 : 37|13@1+ (0.1,0) [0|819] "A" Vector__XXX
 SG_ VC_LVBMS_maxAllowedDischargeCurr m3 : 50|13@1+ (0.1,0) [0|819] "A" Vector__XXX
 SG_ VC_LVBMS_MOSCommand m4 : 3|1@1+ (1,0) [0|1] "" Vector__XXX
 SG_ VC_LVBMS_ClearErrorCntrCommand m4 : 4|1@1+ (1,0) [0|1] "" Vector__XXX
 SG_ VC_LVBMS_ClearHistoricFaultComma m4 : 5|1@1+ (1,0) [0|1] "" Vector__XXX
 SG_ VC_LVBMS_ResetLVBMSCommand m4 : 6|1@1+ (1,0) [0|1] "" Vector__XXX
 SG_ VC_LVBMS_EnterHibernationCommand m4 : 7|1@1+ (1,0) [0|1] "" Vector__XXX
 SG_ VC_LVBMS_ECPAState m4 : 8|2@1+ (1,0) [0|2] "" Vector__XXX
 SG_ VC_LVBMS_MOSState m4 : 10|2@1+ (1,0) [0|2] "" Vector__XXX
 SG_ VC_LVBMS_VehicleState m4 : 12|2@1+ (1,0) [0|3] "" Vector__XXX
 SG_ VC_LVBMS_LINWakeDisabled m4 : 14|1@1+ (1,0) [0|1] "" Vector__XXX
 SG_ VC_LVBMS_chargeType m4 : 16|3@1+ (1,0) [0|7] "" Vector__XXX
 SG_ VC_LVBMS_cellAndArcProtEnabled m4 : 19|1@1+ (1,0) [0|1] "" Vector__XXX
 SG_ VC_LVBMS_avgBrickVoltage m4 : 24|13@1+ (0.001,0) [0|8.19] "V" Vector__XXX
 SG_ VC_LVBMS_minBrickVoltage m4 : 40|13@1+ (0.001,0) [0|8.19] "V" Vector__XXX
 SG_ VC_LVBMS_minBrickVoltageIndex m4 : 56|8@1+ (1,0) [0|254] "" Vector__XXX

BO_ 1816 VC_LVBMS_statusLow: 8 VC
 SG_ VC_lvbmsStatusLowIndex M : 0|3@1+ (1,0) [0|7] "" Vector__XXX
 SG_ VC_LVBMS_SOC m0 : 3|10@1+ (0.1,0) [0|102.2] "%" Vector__XXX
 SG_ VC_LVBMS_SOE m0 : 16|7@1+ (1,0) [0|126] "%" Vector__XXX
 SG_ VC_LVBMS_SOH m0 : 24|7@1+ (1,0) [0|126] "%" Vector__XXX
 SG_ VC_LVBMS_CellOVLevel1 m0 : 31|1@1+ (1,0) [0|1] "" Vector__XXX
 SG_ VC_LVBMS_CellOVLevel2 m0 : 32|1@1+ (1,0) [0|1] "" Vector__XXX
 SG_ VC_LVBMS_CellOVLevel3 m0 : 33|1@1+ (1,0) [0|1] "" Vector__XXX
 SG_ VC_LVBMS_CellUVLevel1 m0 : 34|1@1+ (1,0) [0|1] "" Vector__XXX
 SG_ VC_LVBMS_CellUVLevel2 m0 : 35|1@1+ (1,0) [0|1] "" Vector__XXX
 SG_ VC_LVBMS_ModuleOTLevel1 m0 : 36|1@1+ (1,0) [0|1] "" Vector__XXX
 SG_ VC_LVBMS_PackOVLevel1 m0 : 37|1@1+ (1,0) [0|1] "" Vector__XXX
 SG_ VC_LVBMS_PackOVLevel2 m0 : 38|1@1+ (1,0) [0|1] "" Vector__XXX
 SG_ VC_LVBMS_DischrgOCLevel1 m0 : 39|1@1+ (1,0) [0|1] "" Vector__XXX
 SG_ VC_LVBMS_DischrgOCLevel2 m0 : 40|1@1+ (1,0) [0|1] "" Vector__XXX
 SG_ VC_LVBMS_ChrgOCLevel1 m0 : 41|1@1+ (1,0) [0|1] "" Vector__XXX
 SG_ VC_LVBMS_ChrgOCLevel2 m0 : 42|1@1+ (1,0) [0|1] "" Vector__XXX
 SG_ VC_LVBMS_MOSFETOTLevel1 m0 : 43|1@1+ (1,0) [0|1] "" Vector__XXX
 SG_ VC_LVBMS_KBValueLostFault m0 : 44|1@1+ (1,0) [0|1] "" Vector__XXX
 SG_ VC_LVBMS_BalanceCircuitFault m0 : 45|1@1+ (1,0) [0|1] "" Vector__XXX
 SG_ VC_LVBMS_MOSStateFault m0 : 46|1@1+ (1,0) [0|1] "" Vector__XXX
 SG_ VC_LVBMS_NTCTempDiffWarnLevel1 m0 : 47|1@1+ (1,0) [0|1] "" Vector__XXX
 SG_ VC_LVBMS_DeepDischargeFlag m0 : 48|1@1+ (1,0) [0|1] "" Vector__XXX
 SG_ VC_LVBMS_SamplingError m0 : 49|1@1+ (1,0) [0|1] "" Vector__XXX
 SG_ VC_LVBMS_MosfetStuckCloseError m0 : 50|1@1+ (1,0) [0|1] "" Vector__XXX
 SG_ VC_LVBMS_MosfetStuckOpenError m0 : 51|1@1+ (1,0) [0|1] "" Vector__XXX
 SG_ VC_LVBMS_AvgSleepCurrent m1 : 8|16@1+ (0.01,-200) [-200|455.34] "A" Vector__XXX
 SG_ VC_LVBMS_TimeSlept m1 : 24|24@1+ (1,0) [0|16777214] "min" Vector__XXX
 SG_ VC_LVBMS_SOP m1 : 48|8@1+ (20,0) [0|5080] "W" Vector__XXX
 SG_ VC_LVBMS_AhCharged m2 : 8|32@1+ (0.001,0) [0|4294967.294] "Ah" Vector__XXX
 SG_ VC_LVBMS_MinSleepCurrent m2 : 40|16@1+ (0.01,-200) [-200|455.34] "A" Vector__XXX
 SG_ VC_LVBMS_AhDischarged m3 : 8|32@1+ (0.001,0) [0|4294967.294] "Ah" Vector__XXX
 SG_ VC_LVBMS_MaxSleepCurrent m3 : 40|16@1+ (0.01,-200) [-200|455.34] "A" Vector__XXX
 SG_ VC_LVBMS_sumCellVoltageFiltered m4 : 8|16@1+ (0.001,0) [0|65.534] "V" Vector__XXX
 SG_ VC_LVBMS_maxCellSOC m4 : 24|10@1+ (0.1,0) [0|102.2] "%" Vector__XXX
 SG_ VC_LVBMS_minCellSOC m4 : 34|10@1+ (0.1,0) [0|102.2] "%" Vector__XXX
 SG_ VC_LVBMS_staticSOCCorrection m4 : 44|1@1+ (1,0) [0|1] "" Vector__XXX
 SG_ VC_LVBMS_dynamicSOCCorrection m4 : 45|1@1+ (1,0) [0|1] "" Vector__XXX
 SG_ VC_LVBMS_usableEnergyAvailable m4 : 48|12@1+ (1,0) [0|4000] "Wh" Vector__XXX
 SG_ VC_LVBMS_brakeTelltale m4 : 60|2@1+ (1,0) [0|3] "" Vector__XXX

BO_ 1089 VC_pcsInterface: 8 VC
 SG_ VC_pcsInterfaceMuxIndex M : 48|1@1+ (1,0) [0|1] "" Vector__XXX
 SG_ VC_pcsInterfaceCounter : 50|4@1+ (1,0) [0|15] "" Vector__XXX
 SG_ VC_pcsInterfaceChecksum : 56|8@1+ (1,0) [0|255] "" Vector__XXX
 SG_ VC_pcsLVVoltageTarget m0 : 0|13@1+ (0.01,0) [0|65.535] "V" Vector__XXX
 SG_ VC_pcsLVMinVoltageLimit m0 : 13|13@1+ (0.01,0) [0|65.535] "V" Vector__XXX
 SG_ VC_pcsLVMaxVoltageLimit m0 : 27|13@1+ (0.01,0) [0|65.535] "V" Vector__XXX
 SG_ VC_goodForPCSPowerCycle m0 : 46|1@1+ (1,0) [0|1] "" Vector__XXX
 SG_ VC_LVBatteryCannotSupportVehicle m0 : 47|1@1+ (1,0) [0|1] "" Vector__XXX
 SG_ VC_pcsResistanceFiltered m1 : 0|16@1+ (0.01,0) [0|655.34] "mOhm" Vector__XXX
 SG_ VC_pcsLVMaxDchrgCurrentLimit m1 : 16|12@1+ (0.1,0) [0|400] "A" Vector__XXX
 SG_ VC_defaultPcsLVVoltageTarget m1 : 28|13@1+ (0.01,0) [0|65.535] "V" Vector__XXX
 SG_ VC_lvHwProtSelfTestActive m1 : 41|1@1+ (1,0) [0|1] "" Vector__XXX
 SG_ VC_lvBatteryDischargeRequest m1 : 42|1@1+ (1,0) [0|1] "" Vector__XXX

BO_ 1091 VC_pcsManagement: 6 VC
 SG_ VC_pcsManagementChecksum : 0|8@1+ (1,0) [0|255] "" Vector__XXX
 SG_ VC_pcsManagementCounter : 8|4@1+ (1,0) [0|15] "" Vector__XXX
 SG_ VC_pcsManagementMuxIndex M : 12|1@1+ (1,0) [0|1] "" Vector__XXX
 SG_ VC_dcdcLVVoltageTargetMax m0 : 16|10@1+ (0.1,0) [0|102.3] "V" Vector__XXX
 SG_ VC_dcdcLVVoltageTargetMin m0 : 26|10@1+ (0.1,0) [0|102.3] "V" Vector__XXX
 SG_ VC_dcdcLVInputPowerLimit m0 : 36|8@1+ (50,0) [0|12750] "W" Vector__XXX

BO_TX_BU_ 537 : VCSEC;
BO_TX_BU_ 602 : VCSEC;
BO_TX_BU_ 570 : VCSEC;
BO_TX_BU_ 1067 : VCSEC;
BO_TX_BU_ 761 : VCSEC;
BO_TX_BU_ 825 : VCSEC;
BO_TX_BU_ 1817 : VCSEC;
BO_TX_BU_ 1824 : VCSEC;
BO_TX_BU_ 793 : VCSEC;
BO_TX_BU_ 505 : VCSEC;
BO_TX_BU_ 281 : VCSEC;
BO_TX_BU_ 1850 : VC;
BO_TX_BU_ 1655 : VC;
BO_TX_BU_ 1816 : VC;
BO_TX_BU_ 1089 : VC;
BO_TX_BU_ 1091 : VC;
CM_ BO_ 537 "Vehicle security controller message: TPMS data";
CM_ SG_ 537 VCSEC_TPMSDataIndex "Vehicle security controller: TPMS data index";
CM_ SG_ 537 VCSEC_TPMSCapabilityPressureInAd "Vehicle security controller: TPMS capability pressure in adv0";
CM_ SG_ 537 VCSEC_TPMSCapabilityConfigurable "Vehicle security controller: TPMS capability configurable pressure0";
CM_ SG_ 537 VCSEC_TPMSPressureRateOfChange0 "Reports the raw pressure value of TPMS sensor 0.";
CM_ SG_ 537 VCSEC_TPMSPressure0 "Indicates Absolute pressure measured by wheel unit.; raw 511 = signal not available (SNA)";
CM_ SG_ 537 VCSEC_TPMSTemperature0 "Indicates temperature in tire.; raw 255 = signal not available (SNA)";
CM_ SG_ 537 VCSEC_TPMSBatVoltage0 "Sensor battery voltage.; raw 255 = signal not available (SNA)";
CM_ SG_ 537 VCSEC_TPMSLocation0 "Indicates the localization result";
CM_ SG_ 537 VCSEC_TPMSTemperatureCompensated "Indicates Absolute pressure measured by wheel unit.; raw 511 = signal not available (SNA)";
CM_ SG_ 537 VCSEC_TPMSCapabilityPressur_0001 "Vehicle security controller: TPMS capability pressure in adv1";
CM_ SG_ 537 VCSEC_TPMSCapabilityConfigu_0001 "Vehicle security controller: TPMS capability configurable pressure1";
CM_ SG_ 537 VCSEC_TPMSPressureRateOfChange1 "Reports the raw pressure value of TPMS sensor 1.";
CM_ SG_ 537 VCSEC_TPMSPressure1 "Indicates Absolute pressure measured by wheel unit.; raw 511 = signal not available (SNA)";
CM_ SG_ 537 VCSEC_TPMSTemperature1 "Indicates temperature in tire.; raw 255 = signal not available (SNA)";
CM_ SG_ 537 VCSEC_TPMSBatVoltage1 "Sensor battery voltage.; raw 255 = signal not available (SNA)";
CM_ SG_ 537 VCSEC_TPMSLocation1 "Indicates the localization result";
CM_ SG_ 537 VCSEC_TPMSTemperatureCompen_0001 "Indicates Absolute pressure measured by wheel unit.; raw 511 = signal not available (SNA)";
CM_ SG_ 537 VCSEC_TPMSCapabilityPressur_0002 "Vehicle security controller: TPMS capability pressure in adv2";
CM_ SG_ 537 VCSEC_TPMSCapabilityConfigu_0002 "Vehicle security controller: TPMS capability configurable pressure2";
CM_ SG_ 537 VCSEC_TPMSPressureRateOfChange2 "Reports the raw pressure value of TPMS sensor 2.";
CM_ SG_ 537 VCSEC_TPMSPressure2 "Indicates Absolute pressure measured by wheel unit.; raw 511 = signal not available (SNA)";
CM_ SG_ 537 VCSEC_TPMSTemperature2 "Indicates temperature in tire.; raw 255 = signal not available (SNA)";
CM_ SG_ 537 VCSEC_TPMSBatVoltage2 "Sensor battery voltage.; raw 255 = signal not available (SNA)";
CM_ SG_ 537 VCSEC_TPMSLocation2 "Indicates the localization result";
CM_ SG_ 537 VCSEC_TPMSTemperatureCompen_0002 "Indicates Absolute pressure measured by wheel unit.; raw 511 = signal not available (SNA)";
CM_ SG_ 537 VCSEC_TPMSCapabilityPressur_0003 "Vehicle security controller: TPMS capability pressure in adv3";
CM_ SG_ 537 VCSEC_TPMSCapabilityConfigu_0003 "Vehicle security controller: TPMS capability configurable pressure3";
CM_ SG_ 537 VCSEC_TPMSPressureRateOfChange3 "Reports the raw pressure value of TPMS sensor 3.";
CM_ SG_ 537 VCSEC_TPMSPressure3 "Indicates Absolute pressure measured by wheel unit.; raw 511 = signal not available (SNA)";
CM_ SG_ 537 VCSEC_TPMSTemperature3 "Indicates temperature in tire.; raw 255 = signal not available (SNA)";
CM_ SG_ 537 VCSEC_TPMSBatVoltage3 "Sensor battery voltage.; raw 255 = signal not available (SNA)";
CM_ SG_ 537 VCSEC_TPMSLocation3 "Indicates the localization result";
CM_ SG_ 537 VCSEC_TPMSTemperatureCompen_0003 "Indicates Absolute pressure measured by wheel unit.; raw 511 = signal not available (SNA)";
CM_ SG_ 537 VCSEC_TPMSRecommendedColdPressur "Indicates Absolute pressure measured by wheel unit.; raw 255 = signal not available (SNA)";
CM_ SG_ 537 VCSEC_TPMSRecommendedColdPr_0001 "Indicates Absolute pressure measured by wheel unit.; raw 255 = signal not available (SNA)";
CM_ SG_ 537 VCSEC_TPMSFeature0 "Vehicle security controller: TPMS feature0";
CM_ SG_ 537 VCSEC_TPMSFeature1 "Vehicle security controller: TPMS feature1";
CM_ SG_ 537 VCSEC_TPMSFeature0Count "Vehicle security controller: TPMS feature0 count";
CM_ SG_ 537 VCSEC_TPMSFeature0TimeS "Vehicle security controller: TPMS feature0 time s";
CM_ SG_ 537 VCSEC_TPMSAutonomyStatus "Vehicle security controller: TPMS autonomy status";
CM_ SG_ 537 VCSEC_TPMSAutonomyStatusMIATimeS "Vehicle security controller: TPMS autonomy status MIA time s";
CM_ SG_ 537 VCSEC_TPMSLastKnownPressureFL "Vehicle security controller: TPMS last known pressure FL; raw 255 = signal not available (SNA)";
CM_ SG_ 537 VCSEC_TPMSLastKnownPressureFR "Vehicle security controller: TPMS last known pressure FR; raw 255 = signal not available (SNA)";
CM_ SG_ 537 VCSEC_TPMSLastKnownPressureRL "Vehicle security controller: TPMS last known pressure RL; raw 255 = signal not available (SNA)";
CM_ SG_ 537 VCSEC_TPMSLastKnownPressureRR "Vehicle security controller: TPMS last known pressure RR; raw 255 = signal not available (SNA)";
CM_ BO_ 602 "Vehicle security controller message: TPMS display";
CM_ SG_ 602 VCSEC_TPMSDisplayPressureFL "Indicates Absolute pressure measured by wheel unit.; raw 255 = signal not available (SNA)";
CM_ SG_ 602 VCSEC_TPMSDisplayPressureFR "Indicates Absolute pressure measured by wheel unit.; raw 255 = signal not available (SNA)";
CM_ SG_ 602 VCSEC_TPMSDisplayPressureRL "Indicates Absolute pressure measured by wheel unit.; raw 255 = signal not available (SNA)";
CM_ SG_ 602 VCSEC_TPMSDisplayPressureRR "Indicates Absolute pressure measured by wheel unit.; raw 255 = signal not available (SNA)";
CM_ SG_ 602 VCSEC_TPMSTellTale "TPMS UI telltale status to indicate";
CM_ SG_ 602 VCSEC_TPMSDisplaySoftWarningIndi "UI should indicate soft warning";
CM_ SG_ 602 VCSEC_TPMSDisplaySoftWarnin_0001 "UI should indicate soft warning";
CM_ SG_ 602 VCSEC_TPMSDisplaySoftWarnin_0002 "UI should indicate soft warning";
CM_ SG_ 602 VCSEC_TPMSDisplaySoftWarnin_0003 "UI should indicate soft warning";
CM_ SG_ 602 VCSEC_TPMSDisplayHardWarningIndi "UI should indicate soft warning";
CM_ SG_ 602 VCSEC_TPMSDisplayHardWarnin_0001 "UI should indicate soft warning";
CM_ SG_ 602 VCSEC_TPMSDisplayHardWarnin_0002 "UI should indicate soft warning";
CM_ SG_ 602 VCSEC_TPMSDisplayHardWarnin_0003 "UI should indicate soft warning";
CM_ BO_ 570 "Vehicle security controller message: TPMS status";
CM_ SG_ 570 VCSEC_TPMSStatusIndex "Vehicle security controller: TPMS status index";
CM_ SG_ 570 VCSEC_TPMSSystemState "High level state the TPMS system is in currently";
CM_ SG_ 570 VCSEC_TPMSSensorMACAddress0 "Vehicle security controller: TPMS sensor MAC address0";
CM_ SG_ 570 VCSEC_TPMSSensorMACAddress1 "Vehicle security controller: TPMS sensor MAC address1";
CM_ SG_ 570 VCSEC_TPMSSensorMACAddress2 "Vehicle security controller: TPMS sensor MAC address2";
CM_ SG_ 570 VCSEC_TPMSSensorMACAddress3 "Vehicle security controller: TPMS sensor MAC address3";
CM_ SG_ 570 VCSEC_BLEUnsuccessfulConnEventRa "Vehicle security controller: BLE unsuccessful conn event rate0; raw 1023 = signal not available (SNA)";
CM_ SG_ 570 VCSEC_BLEUnsuccessfulConnEv_0001 "Vehicle security controller: BLE unsuccessful conn event rate1; raw 1023 = signal not available (SNA)";
CM_ SG_ 570 VCSEC_BLEUnsuccessfulConnEv_0002 "Vehicle security controller: BLE unsuccessful conn event rate2; raw 1023 = signal not available (SNA)";
CM_ SG_ 570 VCSEC_BLEUnsuccessfulConnEv_0003 "Vehicle security controller: BLE unsuccessful conn event rate3; raw 1023 = signal not available (SNA)";
CM_ SG_ 570 VCSEC_TPMSSensorTIAppCRC0 "Vehicle security controller: TPMS sensor TI app CRC0; raw 0 = signal not available (SNA)";
CM_ SG_ 570 VCSEC_TPMSSensorMLXAppCRC0 "Vehicle security controller: TPMS sensor MLX app CRC0; raw 0 = signal not available (SNA)";
CM_ SG_ 570 VCSEC_TPMSSensorTIAppCRC1 "Vehicle security controller: TPMS sensor TI app CRC1; raw 0 = signal not available (SNA)";
CM_ SG_ 570 VCSEC_TPMSSensorMLXAppCRC1 "Vehicle security controller: TPMS sensor MLX app CRC1; raw 0 = signal not available (SNA)";
CM_ SG_ 570 VCSEC_TPMSSensorTIAppCRC2 "Vehicle security controller: TPMS sensor TI app CRC2; raw 0 = signal not available (SNA)";
CM_ SG_ 570 VCSEC_TPMSSensorMLXAppCRC2 "Vehicle security controller: TPMS sensor MLX app CRC2; raw 0 = signal not available (SNA)";
CM_ SG_ 570 VCSEC_TPMSSensorTIAppCRC3 "Vehicle security controller: TPMS sensor TI app CRC3; raw 0 = signal not available (SNA)";
CM_ SG_ 570 VCSEC_TPMSSensorMLXAppCRC3 "Vehicle security controller: TPMS sensor MLX app CRC3; raw 0 = signal not available (SNA)";
CM_ SG_ 570 VCSEC_TPMStotalAwakeTime0 "Sleep and CPU time count";
CM_ SG_ 570 VCSEC_TPMSTrimAdjusted0 "Vehicle security controller: TPMS trim adjusted0";
CM_ SG_ 570 VCSEC_TPMSGenealogySensorState0 "TPMS genealogy state";
CM_ SG_ 570 VCSEC_TPMSSensorType0 "Tesla TPMS type";
CM_ SG_ 570 VCSEC_TPMStotalAwakeTime1 "Sleep and CPU time count";
CM_ SG_ 570 VCSEC_TPMSTrimAdjusted1 "Vehicle security controller: TPMS trim adjusted1";
CM_ SG_ 570 VCSEC_TPMSGenealogySensorState1 "TPMS genealogy state";
CM_ SG_ 570 VCSEC_TPMSSensorType1 "Tesla TPMS type";
CM_ SG_ 570 VCSEC_TPMStotalAwakeTime2 "Sleep and CPU time count";
CM_ SG_ 570 VCSEC_TPMSTrimAdjusted2 "Vehicle security controller: TPMS trim adjusted2";
CM_ SG_ 570 VCSEC_TPMSGenealogySensorState2 "TPMS genealogy state";
CM_ SG_ 570 VCSEC_TPMSSensorType2 "Tesla TPMS type";
CM_ SG_ 570 VCSEC_TPMStotalAwakeTime3 "Sleep and CPU time count";
CM_ SG_ 570 VCSEC_TPMSTrimAdjusted3 "Vehicle security controller: TPMS trim adjusted3";
CM_ SG_ 570 VCSEC_TPMSGenealogySensorState3 "TPMS genealogy state";
CM_ SG_ 570 VCSEC_TPMSSensorType3 "Tesla TPMS type";
CM_ SG_ 570 VCSEC_TPMSSensor0Hash "Vehicle security controller: TPMS sensor0 hash";
CM_ SG_ 570 VCSEC_TPMSSensor1Hash "Vehicle security controller: TPMS sensor1 hash";
CM_ SG_ 570 VCSEC_TPMSSensor2Hash "Vehicle security controller: TPMS sensor2 hash";
CM_ SG_ 570 VCSEC_TPMSSensor3Hash "Vehicle security controller: TPMS sensor3 hash";
CM_ SG_ 570 VCSEC_TPMSLastLocationSensor0 "Indicates the localization result";
CM_ SG_ 570 VCSEC_TPMSLastLocationSensor1 "Indicates the localization result";
CM_ SG_ 570 VCSEC_TPMSLastLocationSensor2 "Indicates the localization result";
CM_ SG_ 570 VCSEC_TPMSLastLocationSensor3 "Indicates the localization result";
CM_ SG_ 570 VCSEC_TPMSTemperatureCompensated "Sensor battery voltage.; raw 255 = signal not available (SNA)";
CM_ SG_ 570 VCSEC_TPMSTemperatureCompen_0001 "Sensor battery voltage.; raw 255 = signal not available (SNA)";
CM_ SG_ 570 VCSEC_TPMSTemperatureCompen_0002 "Sensor battery voltage.; raw 255 = signal not available (SNA)";
CM_ SG_ 570 VCSEC_TPMSTemperatureCompen_0003 "Sensor battery voltage.; raw 255 = signal not available (SNA)";
CM_ SG_ 570 VCSEC_TPMSFilteredBatVoltage0 "Sensor battery voltage.; raw 255 = signal not available (SNA)";
CM_ SG_ 570 VCSEC_TPMSFilteredBatVoltage2 "Sensor battery voltage.; raw 255 = signal not available (SNA)";
CM_ SG_ 570 VCSEC_TPMSFilteredBatVoltage1 "Sensor battery voltage.; raw 255 = signal not available (SNA)";
CM_ SG_ 570 VCSEC_TPMSFilteredBatVoltage3 "Sensor battery voltage.; raw 255 = signal not available (SNA)";
CM_ BO_ 1067 "Vehicle security controller message: UWB data";
CM_ SG_ 1067 VCSEC_UWBEndpointIndex "Vehicle security controller: UWB endpoint index";
CM_ SG_ 1067 VCSEC_UWBExpectedEndpointsActive "Expected number of UWB endpoints active for a connection channel.";
CM_ SG_ 1067 VCSEC_UWBExpectedEndpointsA_0001 "Expected number of UWB endpoints active for a connection channel.";
CM_ SG_ 1067 VCSEC_UWBExpectedEndpointsA_0002 "Expected number of UWB endpoints active for a connection channel.";
CM_ SG_ 1067 VCSEC_UWBExpectedEndpointsA_0003 "Expected number of UWB endpoints active for a connection channel.";
CM_ SG_ 1067 VCSEC_UWBRearRightDistance0 "Reports distance between the customer's phone and the endpoint.; raw 4095 = signal not available (SNA)";
CM_ SG_ 1067 VCSEC_UWBRearRightDistance1 "Reports distance between the customer's phone and the endpoint.; raw 4095 = signal not available (SNA)";
CM_ SG_ 1067 VCSEC_UWBRearRightDistance2 "Reports distance between the customer's phone and the endpoint.; raw 4095 = signal not available (SNA)";
CM_ SG_ 1067 VCSEC_UWBLeftDistance3 "Reports distance between the customer's phone and the endpoint.; raw 4095 = signal not available (SNA)";
CM_ SG_ 1067 VCSEC_UWBRightDistance3 "Reports distance between the customer's phone and the endpoint.; raw 4095 = signal not available (SNA)";
CM_ SG_ 1067 VCSEC_UWBRearRightDistance3 "Reports distance between the customer's phone and the endpoint.; raw 4095 = signal not available (SNA)";
CM_ SG_ 1067 VCSEC_UWBRearLeftDistance3 "Reports distance between the customer's phone and the endpoint.; raw 4095 = signal not available (SNA)";
CM_ SG_ 1067 VCSEC_UWBCenterDistance3 "Reports distance between the customer's phone and the endpoint.; raw 4095 = signal not available (SNA)";
CM_ SG_ 1067 VCSEC_UWBLeftDistance2 "Reports distance between the customer's phone and the endpoint.; raw 4095 = signal not available (SNA)";
CM_ SG_ 1067 VCSEC_UWBRightDistance2 "Reports distance between the customer's phone and the endpoint.; raw 4095 = signal not available (SNA)";
CM_ SG_ 1067 VCSEC_UWBRearDistance2 "Reports distance between the customer's phone and the endpoint.; raw 4095 = signal not available (SNA)";
CM_ SG_ 1067 VCSEC_UWBRearLeftDistance2 "Reports distance between the customer's phone and the endpoint.; raw 4095 = signal not available (SNA)";
CM_ SG_ 1067 VCSEC_UWBCenterDistance2 "Reports distance between the customer's phone and the endpoint.; raw 4095 = signal not available (SNA)";
CM_ SG_ 1067 VCSEC_UWBLeftDistance1 "Reports distance between the customer's phone and the endpoint.; raw 4095 = signal not available (SNA)";
CM_ SG_ 1067 VCSEC_UWBRightDistance1 "Reports distance between the customer's phone and the endpoint.; raw 4095 = signal not available (SNA)";
CM_ SG_ 1067 VCSEC_UWBRearDistance1 "Reports distance between the customer's phone and the endpoint.; raw 4095 = signal not available (SNA)";
CM_ SG_ 1067 VCSEC_UWBRearLeftDistance1 "Reports distance between the customer's phone and the endpoint.; raw 4095 = signal not available (SNA)";
CM_ SG_ 1067 VCSEC_UWBCenterDistance1 "Reports distance between the customer's phone and the endpoint.; raw 4095 = signal not available (SNA)";
CM_ SG_ 1067 VCSEC_UWBLeftDistance0 "Reports distance between the customer's phone and the endpoint.; raw 4095 = signal not available (SNA)";
CM_ SG_ 1067 VCSEC_UWBRightDistance0 "Reports distance between the customer's phone and the endpoint.; raw 4095 = signal not available (SNA)";
CM_ SG_ 1067 VCSEC_UWBRearDistance0 "Reports distance between the customer's phone and the endpoint.; raw 4095 = signal not available (SNA)";
CM_ SG_ 1067 VCSEC_UWBRearLeftDistance0 "Reports distance between the customer's phone and the endpoint.; raw 4095 = signal not available (SNA)";
CM_ SG_ 1067 VCSEC_UWBCenterDistance0 "Reports distance between the customer's phone and the endpoint.; raw 4095 = signal not available (SNA)";
CM_ BO_ 761 "Vehicle security controller message: additional auth info";
CM_ SG_ 761 VCSEC_activeKeyDebug "Vehicle security controller: active key debug";
CM_ SG_ 761 VCSEC_bleChannelDisconnected "Connection between vehicle and the BLE authentication device is interrupted.";
CM_ SG_ 761 VCSEC_bleDisconnectionReason "Reasons of the disconnection between vehicle and BLE authentication device.";
CM_ SG_ 761 VCSEC_bleConnetionAttemptWLEntry "Vehicle security controller: ble connetion attempt WL entry";
CM_ SG_ 761 VCSEC_AdditionalAuthInfoIndex "Vehicle security controller: additional auth info index";
CM_ SG_ 761 VCSEC_activeKeyReason "Reason for picking the currently active key";
CM_ SG_ 761 VCSEC_activeKeySHA1 "Vehicle security controller: active key SHA1";
CM_ SG_ 761 VCSEC_algoUsedForSummonRange0 "Vehicle security controller: algo used for summon range0";
CM_ SG_ 761 VCSEC_keyWithinSummonRange0 "Vehicle security controller: key within summon range0";
CM_ SG_ 761 VCSEC_algoUsedForSummonRange1 "Vehicle security controller: algo used for summon range1";
CM_ SG_ 761 VCSEC_keyWithinSummonRange1 "Vehicle security controller: key within summon range1";
CM_ SG_ 761 VCSEC_algoUsedForSummonRange2 "Vehicle security controller: algo used for summon range2";
CM_ SG_ 761 VCSEC_keyWithinSummonRange2 "Vehicle security controller: key within summon range2";
CM_ SG_ 761 VCSEC_BLEDeviceWithinSummonRange "Vehicle security controller: BLE device within summon range";
CM_ SG_ 761 VCSEC_algoUWBInteriorPresence "Vehicle security controller: algo UWB interior presence";
CM_ SG_ 761 VCSEC_frunkOpenSuggestionRespons "Vehicle security controller: frunk open suggestion response";
CM_ SG_ 761 VCSEC_NFCAuthFromBPillarFormFact "Reports the form factor authentication at B-pillar Near Field Communication (NFC) reader.";
CM_ SG_ 761 VCSEC_NFCAuthFromCenterConsoleFo "Reports the form factor authenticating at center console Near Field Communication (NFC) reader.";
CM_ SG_ 761 VCSEC_trunkOpenSuggestionRespons "Vehicle security controller: trunk open suggestion response";
CM_ SG_ 761 VCSEC_algoTrunkSuggestionRaw "Vehicle security controller: algo trunk suggestion raw";
CM_ SG_ 761 VCSEC_algoTrunkSuggestionProc "Vehicle security controller: algo trunk suggestion proc";
CM_ SG_ 761 VCSEC_algoTrunkSuggestionRearmAl "Vehicle security controller: algo trunk suggestion rearm allowed";
CM_ SG_ 761 VCSEC_algoFrunkSuggestionRaw "Vehicle security controller: algo frunk suggestion raw";
CM_ SG_ 761 VCSEC_algoFrunkSuggestionProc "Vehicle security controller: algo frunk suggestion proc";
CM_ SG_ 761 VCSEC_algoFrunkSuggestionRearmAl "Vehicle security controller: algo frunk suggestion rearm allowed";
CM_ BO_ 825 "Vehicle security controller message: authentication";
CM_ SG_ 825 VCSEC_BLEConnectionCounter "The number of devices connected to the host Bluetooth endpoint.";
CM_ SG_ 825 VCSEC_authRejectionReason "Reason it was rejected";
CM_ SG_ 825 VCSEC_IDRequested "Vehicle security controller: ID requested";
CM_ SG_ 825 VCSEC_operationMode "Reports the operation mode of the vehicle.";
CM_ SG_ 825 VCSEC_vehicleLockStatus "Lock status of the vehicle.; raw 0 = signal not available (SNA)";
CM_ SG_ 825 VCSEC_authenticationStatus "Reports the vehicle authentication status.";
CM_ SG_ 825 VCSEC_chargePortLockStatus "Lock status of the charge port.";
CM_ SG_ 825 VCSEC_leftFrontLockStatus "Lock status of the left front door.";
CM_ SG_ 825 VCSEC_leftRearLockStatus "Lock status of the left rear door.";
CM_ SG_ 825 VCSEC_rightFrontLockStatus "Lock status of the right front door.";
CM_ SG_ 825 VCSEC_rightRearLockStatus "Lock status of right rear door.";
CM_ SG_ 825 VCSEC_trunkLockStatus "Lock status of the trunk.";
CM_ SG_ 825 VCSEC_lockRequestType "Reports the type of lock and unlock request received.";
CM_ SG_ 825 VCSEC_summonRequest "Reports the Summon request state.; raw 5 = signal not available (SNA)";
CM_ SG_ 825 VCSEC_3rdPartyPLGRequest "Vehicle security controller: 3rd party PLG request; raw 3 = signal not available (SNA)";
CM_ SG_ 825 VCSEC_3rdPartyFrunkPLGRequest "Vehicle security controller: 3rd party frunk PLG request; raw 3 = signal not available (SNA)";
CM_ SG_ 825 VCSEC_MCUCommandType "Vehicle security controller: MCU command type";
CM_ SG_ 825 VCSEC_frunkLockStatus "Lock status of the frunk";
CM_ SG_ 825 VCSEC_usingModifiedMACAddress "Vehicle security controller: using modified MAC address";
CM_ SG_ 825 VCSEC_isKeyWithinSummonRange "Key is within the range of the car where summon can be enabled";
CM_ SG_ 825 VCSEC_isBLEDeviceWithinSummonRan "Indicates whether a Bluetooth Low Energy (BLE) device is within the range where Summon can be enabled.";
CM_ SG_ 825 VCSEC_alarmStatus "Reports the vehicle alarm status.; raw 15 = signal not available (SNA)";
CM_ SG_ 825 VCSEC_serviceDiagnosticRequest "Vehicle security controller: service diagnostic request";
CM_ SG_ 825 VCSEC_immobilizerState "State of the immobilizer.";
CM_ SG_ 825 VCSEC_lockIndicationRequest "Requests to turn on vehicle turn indicators based on lock and unlock states.; raw 0 = signal not available (SNA)";
CM_ SG_ 825 VCSEC_simpleLockStatus "Vehicle lock status with simplfied two states: lock and unlock.; raw 0 = signal not available (SNA)";
CM_ SG_ 825 VCSEC_keyChannelIndexed "Vehicle security controller: key channel indexed; raw 15 = signal not available (SNA)";
CM_ SG_ 825 VCSEC_authRequested "An authentication request was sent from the security controller to the authentication device.";
CM_ SG_ 825 VCSEC_remoteStartActive "Indicates when a remote start request terminated by the Vehicle Security Controller (VCSEC) is active.";
CM_ SG_ 825 VCSEC_keyPairDesired "Vehicle security controller: key pair desired";
CM_ BO_ 1817 "Vehicle security controller message: debug100ms";
CM_ SG_ 1817 VCSEC_debug100msIndex "Vehicle security controller: debug100ms index";
CM_ SG_ 1817 VCSEC_walkAwayLockKeyState "Walk away lock key state of the vehicle";
CM_ SG_ 1817 VCSEC_thresholdOffsetVersion "Vehicle security controller: threshold offset version";
CM_ SG_ 1817 VCSEC_walkAwayLockState "Walk away lock state of the vehicle";
CM_ SG_ 1817 VCSEC_rssi0WLEntry "Whitelist entry of the rssi0 device";
CM_ SG_ 1817 VCSEC_endpointLayout "Vehicle security controller: endpoint layout";
CM_ SG_ 1817 VCSEC_rssi1WLEntry "Whitelist entry of the rssi1 device";
CM_ SG_ 1817 VCSEC_rssi2WLEntry "Whitelist entry of the rssi2 device";
CM_ SG_ 1817 VCSEC_walkUpUnlockState "Status of walk up unlock state";
CM_ SG_ 1817 VCSEC_algoHighThreshLeft "Vehicle security controller: algo high thresh left";
CM_ SG_ 1817 VCSEC_algoHighThreshRight "Vehicle security controller: algo high thresh right";
CM_ SG_ 1817 VCSEC_algoHighThreshCenter "Vehicle security controller: algo high thresh center";
CM_ SG_ 1817 VCSEC_pollingReason "Reason that the vehicle is currently polling for location";
CM_ SG_ 1817 VCSEC_numberOfPubKeysOnWhitelist "Number of public keys on keys whitelist.";
CM_ SG_ 1817 VCSEC_thermalDetectState "Reports the current state of thermal detection.";
CM_ SG_ 1817 VCSEC_chargeHandleMitigationActi "Vehicle security controller: charge handle mitigation active";
CM_ SG_ 1817 VCSEC_smartTrunkMitigatedKeyCoun "Vehicle security controller: smart trunk mitigated key count";
CM_ SG_ 1817 VCSEC_UWB3WLEntry "Whitelist entry of UWB3 device, phone that requested robotaxi and is not connected over BLE";
CM_ SG_ 1817 VCSEC_device0Offset "Vehicle security controller: device0 offset";
CM_ SG_ 1817 VCSEC_device1Offset "Vehicle security controller: device1 offset";
CM_ SG_ 1817 VCSEC_device2Offset "Vehicle security controller: device2 offset";
CM_ SG_ 1817 VCSEC_connection0BondingState "state of the GAP bonding statemachine";
CM_ SG_ 1817 VCSEC_connection1BondingState "state of the GAP bonding statemachine";
CM_ SG_ 1817 VCSEC_connection2BondingState "state of the GAP bonding statemachine";
CM_ SG_ 1817 VCSEC_connection0UWBAvailability "state of the UWB availability on the BLE connection";
CM_ SG_ 1817 VCSEC_connection1UWBAvailability "state of the UWB availability on the BLE connection";
CM_ SG_ 1817 VCSEC_connection2UWBAvailability "state of the UWB availability on the BLE connection";
CM_ SG_ 1817 VCSEC_NISessionStateCenter0 "Vehicle security controller: NI session state center0";
CM_ SG_ 1817 VCSEC_NISessionStateLeft0 "Vehicle security controller: NI session state left0";
CM_ SG_ 1817 VCSEC_NISessionStateRight0 "Vehicle security controller: NI session state right0";
CM_ SG_ 1817 VCSEC_NISessionStateRearLeft0 "Vehicle security controller: NI session state rear left0";
CM_ SG_ 1817 VCSEC_NISessionStateRearRight0 "Vehicle security controller: NI session state rear right0";
CM_ SG_ 1817 VCSEC_NISessionStateRear0 "Vehicle security controller: NI session state rear0";
CM_ SG_ 1817 VCSEC_NISessionStateCenter1 "Vehicle security controller: NI session state center1";
CM_ SG_ 1817 VCSEC_NISessionStateLeft1 "Vehicle security controller: NI session state left1";
CM_ SG_ 1817 VCSEC_NISessionStateRight1 "Vehicle security controller: NI session state right1";
CM_ SG_ 1817 VCSEC_NISessionStateRearLeft1 "Vehicle security controller: NI session state rear left1";
CM_ SG_ 1817 VCSEC_NISessionStateRearRight1 "Vehicle security controller: NI session state rear right1";
CM_ SG_ 1817 VCSEC_NISessionStateRear1 "Vehicle security controller: NI session state rear1";
CM_ SG_ 1817 VCSEC_NISessionStateCenter2 "Vehicle security controller: NI session state center2";
CM_ SG_ 1817 VCSEC_NISessionStateLeft2 "Vehicle security controller: NI session state left2";
CM_ SG_ 1817 VCSEC_NISessionStateRight2 "Vehicle security controller: NI session state right2";
CM_ SG_ 1817 VCSEC_NISessionStateRearLeft2 "Vehicle security controller: NI session state rear left2";
CM_ SG_ 1817 VCSEC_NISessionStateRearRight2 "Vehicle security controller: NI session state rear right2";
CM_ SG_ 1817 VCSEC_NISessionStateRear2 "Vehicle security controller: NI session state rear2";
CM_ SG_ 1817 VCSEC_NISessionStateLeft3 "Vehicle security controller: NI session state left3";
CM_ SG_ 1817 VCSEC_NISessionStateRight3 "Vehicle security controller: NI session state right3";
CM_ SG_ 1817 VCSEC_NISessionStateRearRight3 "Vehicle security controller: NI session state rear right3";
CM_ SG_ 1817 VCSEC_NISessionStateRearLeft3 "Vehicle security controller: NI session state rear left3";
CM_ SG_ 1817 VCSEC_NISessionStateCenter3 "Vehicle security controller: NI session state center3";
CM_ BO_ 1824 "Vehicle security controller message: ecu config";
CM_ SG_ 1824 VCSEC_ECUConfigCRC32 "Vehicle security controller: ECU config CRC32";
CM_ SG_ 1824 VCSEC_autoWriteConfig "Vehicle security controller: auto write config";
CM_ SG_ 1824 VCSEC_requestForConfig "Vehicle security controller: request for config";
CM_ BO_ 793 "Vehicle security controller message: info";
CM_ SG_ 793 VCSEC_infoIndex "Vehicle security controller: info index";
CM_ SG_ 793 VCSEC_infoBuildType "Vehicle security controller: info build type";
CM_ SG_ 793 VCSEC_infoBuildConfigId "Vehicle security controller: info build config id";
CM_ SG_ 793 VCSEC_infoHardwareId "Vehicle security controller: info hardware id";
CM_ SG_ 793 VCSEC_infoComponentId "Vehicle security controller: info component id";
CM_ SG_ 793 VCSEC_infoPcbaId "Vehicle security controller: info pcba id";
CM_ SG_ 793 VCSEC_infoAssemblyId "Vehicle security controller: info assembly id; raw 255 = signal not available (SNA)";
CM_ SG_ 793 VCSEC_infoUsageId "Vehicle security controller: info usage id";
CM_ SG_ 793 VCSEC_infoSubUsageId "Vehicle security controller: info sub usage id";
CM_ SG_ 793 VCSEC_infoAppCrc "Vehicle security controller: info app crc";
CM_ SG_ 793 VCSEC_infoSubcomponent1 "Vehicle security controller: info subcomponent1";
CM_ SG_ 793 VCSEC_infoAppGitHash "Vehicle security controller: info app git hash";
CM_ SG_ 793 VCSEC_infoBootGitHash "Vehicle security controller: info boot git hash";
CM_ SG_ 793 VCSEC_infoPlatformType "Vehicle security controller: info platform type";
CM_ SG_ 793 VCSEC_infoBootUdsProtoVersion "Vehicle security controller: info boot uds proto version";
CM_ SG_ 793 VCSEC_infoBootCrc "Vehicle security controller: info boot crc";
CM_ SG_ 793 VCSEC_infoSubcomponent2 "Vehicle security controller: info subcomponent2";
CM_ SG_ 793 VCSEC_infoSubcomponent3 "Vehicle security controller: info subcomponent3";
CM_ SG_ 793 VCSEC_infoSubcomponent4 "Vehicle security controller: info subcomponent4";
CM_ BO_ 505 "Vehicle security controller message: requests";
CM_ SG_ 505 VCSEC_chargePortRequest "Open and close requests of the charge port door.; raw 3 = signal not available (SNA)";
CM_ SG_ 505 VCSEC_presentHandles "VCSEC command to present the handles. Applicable to Model S.";
CM_ SG_ 505 VCSEC_frontLeftClosureRequest "VCSEC command to present the front left door.";
CM_ SG_ 505 VCSEC_frontRightClosureRequest "VCSEC command to present the front right door.";
CM_ SG_ 505 VCSEC_rearLeftClosureRequest "open and close requests of the left rear door.";
CM_ SG_ 505 VCSEC_rearRightClosureRequest "open and close requests of the right rear door.";
CM_ SG_ 505 VCSEC_rearTrunkClosureRequest "VCSEC command to operate the rear trunk.";
CM_ SG_ 505 VCSEC_frontLeftRequestReason "VCSEC reason to present the front left door.";
CM_ SG_ 505 VCSEC_frontRightRequestReason "VCSEC reason to present the front right door.";
CM_ SG_ 505 VCSEC_rearLeftRequestReason "open and close request reason of the left rear door.";
CM_ SG_ 505 VCSEC_rearRightRequestReason "open and close request reason of the right rear door.";
CM_ SG_ 505 VCSEC_rearTrunkRequestReason "VCSEC reason for command to operate the rear trunk.";
CM_ SG_ 505 VCSEC_rdMapDumpRequested "Vehicle security controller: rd map dump requested";
CM_ SG_ 505 VCSEC_driveAttemptedWithoutAuth "Driver is attempting shift into drive wihout a key present";
CM_ SG_ 505 VCSEC_closeAllStatus "Vehicle security controller: close all status";
CM_ SG_ 505 VCSEC_snapshotRequested "Vehicle security controller: snapshot requested";
CM_ SG_ 505 VCSEC_chargeportRequestReason "VCSEC reason to open the chargeport door.";
CM_ SG_ 505 VCSEC_frontTrunkClosureRequest "VCSEC command to operate front trunk.";
CM_ SG_ 505 VCSEC_frontTrunkRequestReason "VCSEC reason to present the front left door.";
CM_ BO_ 281 "Vehicle security controller message: requests2";
CM_ SG_ 281 VCSEC_activeImmobilizerAuthLevel "The level of auth VCSEC will respond with when the Drive Inverter asks for auth";
CM_ SG_ 281 VCSEC_smartTrunkLightRequest "Request to signal indication lights for the smart trunk feature";
CM_ SG_ 281 VCSEC_smartTrunkSoundRequest "Vehicle security controller: smart trunk sound request";
CM_ SG_ 281 VCSEC_hvacRunScreenProtectOnly "Vehicle security controller: hvac run screen protect only";
CM_ SG_ 281 VCSEC_chargeHandleRequestModel "Vehicle security controller: charge handle request model";
CM_ SG_ 281 VCSEC_recoveryModeRequested "Vehicle security controller: recovery mode requested";
CM_ SG_ 281 VCSEC_infotainmentResetRequested "Vehicle security controller: infotainment reset requested";
CM_ SG_ 281 VCSEC_mobileToAPRequest "Vehicle security controller: mobile to AP request";
CM_ SG_ 281 VCSEC_riderKeyPresent "Vehicle security controller: rider key present";
CM_ BO_ 1850 "VC ECU message: LVBMS brick measurements";
CM_ SG_ 1850 VC_LVBMS_brickMeasurementsMultip "VC ECU: LVBMS brick measurements multiplexer";
CM_ SG_ 1850 VC_LVBMS_brickVoltage1 "Voltage of a low voltage battery brick; raw 8191 = signal not available (SNA)";
CM_ SG_ 1850 VC_LVBMS_brickVoltage2 "Voltage of a low voltage battery brick; raw 8191 = signal not available (SNA)";
CM_ SG_ 1850 VC_LVBMS_brickVoltage3 "Voltage of a low voltage battery brick; raw 8191 = signal not available (SNA)";
CM_ SG_ 1850 VC_LVBMS_brickVoltage4 "Voltage of a low voltage battery brick; raw 8191 = signal not available (SNA)";
CM_ SG_ 1850 VC_LVBMS_brickBalancingAh1 "Ah count of a low voltage battery brick; raw 16777215 = signal not available (SNA)";
CM_ SG_ 1850 VC_LVBMS_brickBalancingAh2 "Ah count of a low voltage battery brick; raw 16777215 = signal not available (SNA)";
CM_ SG_ 1850 VC_LVBMS_brickBalancingState1 "VC ECU: LVBMS brick balancing state1";
CM_ SG_ 1850 VC_LVBMS_brickBalancingState2 "VC ECU: LVBMS brick balancing state2";
CM_ SG_ 1850 VC_LVBMS_brickBalancingAh3 "Ah count of a low voltage battery brick; raw 16777215 = signal not available (SNA)";
CM_ SG_ 1850 VC_LVBMS_brickBalancingAh4 "Ah count of a low voltage battery brick; raw 16777215 = signal not available (SNA)";
CM_ SG_ 1850 VC_LVBMS_brickBalancingState3 "VC ECU: LVBMS brick balancing state3";
CM_ SG_ 1850 VC_LVBMS_brickBalancingState4 "VC ECU: LVBMS brick balancing state4";
CM_ BO_ 1655 "VC ECU message: LVBMS status high";
CM_ SG_ 1655 VC_lvbmsStatusHighIndex "VC ECU: lvbms status high index";
CM_ SG_ 1655 VC_LVBMS_packCurrent "Electrical current into the low voltage battery; raw 4194303 = signal not available (SNA)";
CM_ SG_ 1655 VC_LVBMS_packVoltage "Voltage of the low voltage battery; raw 65535 = signal not available (SNA)";
CM_ SG_ 1655 VC_LVBMS_packTemperature "Temperature of the low voltage battery; raw 511 = signal not available (SNA)";
CM_ SG_ 1655 VC_LVBMS_MOSTemperature "Temperature of the MOSFET on the low voltage battery; raw 4095 = signal not available (SNA)";
CM_ SG_ 1655 VC_LVBMS_sumCellVoltage "Sum of the cell voltage of the low voltage battery; raw 65535 = signal not available (SNA)";
CM_ SG_ 1655 VC_LVBMS_maxBrickVoltage "Maximum cell voltage in the low voltage battery; raw 8191 = signal not available (SNA)";
CM_ SG_ 1655 VC_LVBMS_maxBrickVoltageIndex "VC ECU: LVBMS max brick voltage index; raw 255 = signal not available (SNA)";
CM_ SG_ 1655 VC_totalLVLoadCurrent "Total LV load current of the vehicle.";
CM_ SG_ 1655 VC_LVPackChargeCurrentLimit "Charge current limit for the LV battery pack.";
CM_ SG_ 1655 VC_LVPackCurrent "Current of the LV battery pack.";
CM_ SG_ 1655 VC_LVBMS_estimatedPackOcv "VC ECU: LVBMS estimated pack ocv";
CM_ SG_ 1655 VC_LVBMS_voltageTarget "Voltage target of the LV battery; raw 65535 = signal not available (SNA)";
CM_ SG_ 1655 VC_LVBMS_currentTarget "Target current requested by the LV battery; raw 262143 = signal not available (SNA)";
CM_ SG_ 1655 VC_LVBMS_maxAllowedChargeCurrent "Maximum allowed charge current of the battery; raw 8191 = signal not available (SNA)";
CM_ SG_ 1655 VC_LVBMS_maxAllowedDischargeCurr "Maximum allowed discharge current of the battery; raw 8191 = signal not available (SNA)";
CM_ SG_ 1655 VC_LVBMS_MOSCommand "Current state of the MOS command to the LV battery";
CM_ SG_ 1655 VC_LVBMS_ClearErrorCntrCommand "VC ECU: LVBMS clear error cntr command";
CM_ SG_ 1655 VC_LVBMS_ClearHistoricFaultComma "VC ECU: LVBMS clear historic fault command";
CM_ SG_ 1655 VC_LVBMS_ResetLVBMSCommand "Reset command issued to LVBMS, commanded by VC";
CM_ SG_ 1655 VC_LVBMS_EnterHibernationCommand "VC ECU: LVBMS enter hibernation command";
CM_ SG_ 1655 VC_LVBMS_ECPAState "Current state of the E-CPA on the LV battery; raw 3 = signal not available (SNA)";
CM_ SG_ 1655 VC_LVBMS_MOSState "Current state of the MOS on the LV battery; raw 3 = signal not available (SNA)";
CM_ SG_ 1655 VC_LVBMS_VehicleState "VC ECU: LVBMS vehicle state";
CM_ SG_ 1655 VC_LVBMS_LINWakeDisabled "VC ECU: LVBMS LIN wake disabled";
CM_ SG_ 1655 VC_LVBMS_chargeType "VC ECU: LVBMS charge type; raw 4 = signal not available (SNA)";
CM_ SG_ 1655 VC_LVBMS_cellAndArcProtEnabled "Indicates whether the VC has commanded cell protections to be active";
CM_ SG_ 1655 VC_LVBMS_avgBrickVoltage "Average voltage of all cells in the low voltage battery; raw 8191 = signal not available (SNA)";
CM_ SG_ 1655 VC_LVBMS_minBrickVoltage "Minimum cell voltage in the low voltage battery; raw 8191 = signal not available (SNA)";
CM_ SG_ 1655 VC_LVBMS_minBrickVoltageIndex "VC ECU: LVBMS min brick voltage index; raw 255 = signal not available (SNA)";
CM_ BO_ 1816 "VC ECU message: LVBMS status low";
CM_ SG_ 1816 VC_lvbmsStatusLowIndex "VC ECU: lvbms status low index";
CM_ SG_ 1816 VC_LVBMS_SOC "State of charge reported by the low voltage battery sensor; raw 1023 = signal not available (SNA)";
CM_ SG_ 1816 VC_LVBMS_SOE "State of energy reported by the low voltage battery; raw 127 = signal not available (SNA)";
CM_ SG_ 1816 VC_LVBMS_SOH "State of health reported by the low voltage battery; raw 127 = signal not available (SNA)";
CM_ SG_ 1816 VC_LVBMS_CellOVLevel1 "VC ECU: LVBMS cell OV level1";
CM_ SG_ 1816 VC_LVBMS_CellOVLevel2 "VC ECU: LVBMS cell OV level2";
CM_ SG_ 1816 VC_LVBMS_CellOVLevel3 "VC ECU: LVBMS cell OV level3";
CM_ SG_ 1816 VC_LVBMS_CellUVLevel1 "VC ECU: LVBMS cell UV level1";
CM_ SG_ 1816 VC_LVBMS_CellUVLevel2 "VC ECU: LVBMS cell UV level2";
CM_ SG_ 1816 VC_LVBMS_ModuleOTLevel1 "VC ECU: LVBMS module OT level1";
CM_ SG_ 1816 VC_LVBMS_PackOVLevel1 "VC ECU: LVBMS pack OV level1";
CM_ SG_ 1816 VC_LVBMS_PackOVLevel2 "Pack Over Voltage Level 2 flag status";
CM_ SG_ 1816 VC_LVBMS_DischrgOCLevel1 "VC ECU: LVBMS dischrg OC level1";
CM_ SG_ 1816 VC_LVBMS_DischrgOCLevel2 "Discharge Over Current Level 2 flag status";
CM_ SG_ 1816 VC_LVBMS_ChrgOCLevel1 "VC ECU: LVBMS chrg OC level1";
CM_ SG_ 1816 VC_LVBMS_ChrgOCLevel2 "Charge Over Current Level 2 flag status";
CM_ SG_ 1816 VC_LVBMS_MOSFETOTLevel1 "VC ECU: LVBMS MOSFETOT level1";
CM_ SG_ 1816 VC_LVBMS_KBValueLostFault "Loss of CATL specific internal value flag status. Lost value causes offset in current sensor reading.";
CM_ SG_ 1816 VC_LVBMS_BalanceCircuitFault "Balance Circuit Fault flag status";
CM_ SG_ 1816 VC_LVBMS_MOSStateFault "Mosfet fault state flag status. Not to be confused with VC_LVBMS_MOSState.";
CM_ SG_ 1816 VC_LVBMS_NTCTempDiffWarnLevel1 "VC ECU: LVBMS NTC temp diff warn level1";
CM_ SG_ 1816 VC_LVBMS_DeepDischargeFlag "Deep Discharge flag status";
CM_ SG_ 1816 VC_LVBMS_SamplingError "Sampling Error flag status";
CM_ SG_ 1816 VC_LVBMS_MosfetStuckCloseError "Mosfet Stuck Close flag status";
CM_ SG_ 1816 VC_LVBMS_MosfetStuckOpenError "Mosfet Stuck Open flag status";
CM_ SG_ 1816 VC_LVBMS_AvgSleepCurrent "Low voltage battery average sleep current.; raw 65535 = signal not available (SNA)";
CM_ SG_ 1816 VC_LVBMS_TimeSlept "VC ECU: LVBMS time slept; raw 16777215 = signal not available (SNA)";
CM_ SG_ 1816 VC_LVBMS_SOP "VC ECU: LVBMS SOP; raw 255 = signal not available (SNA)";
CM_ SG_ 1816 VC_LVBMS_AhCharged "Low voltage battery charge state; raw 4294967295 = signal not available (SNA)";
CM_ SG_ 1816 VC_LVBMS_MinSleepCurrent "VC ECU: LVBMS min sleep current; raw 65535 = signal not available (SNA)";
CM_ SG_ 1816 VC_LVBMS_AhDischarged "Low voltage battery charge state; raw 4294967295 = signal not available (SNA)";
CM_ SG_ 1816 VC_LVBMS_MaxSleepCurrent "VC ECU: LVBMS max sleep current; raw 65535 = signal not available (SNA)";
CM_ SG_ 1816 VC_LVBMS_sumCellVoltageFiltered "VC ECU: LVBMS sum cell voltage filtered; raw 65535 = signal not available (SNA)";
CM_ SG_ 1816 VC_LVBMS_maxCellSOC "SOC estimate of the highest SOC cell.; raw 1023 = signal not available (SNA)";
CM_ SG_ 1816 VC_LVBMS_minCellSOC "SOC estimate of the lowest SOC cell.; raw 1023 = signal not available (SNA)";
CM_ SG_ 1816 VC_LVBMS_staticSOCCorrection "Flag indicating the LVBMS is performing static SOC correction.";
CM_ SG_ 1816 VC_LVBMS_dynamicSOCCorrection "Flag indicating the LVBMS is performing dynamic SOC correction.";
CM_ SG_ 1816 VC_LVBMS_usableEnergyAvailable "Available/remaining usable pack energy; raw 4095 = signal not available (SNA)";
CM_ SG_ 1816 VC_LVBMS_brakeTelltale "VC ECU: LVBMS brake telltale";
CM_ BO_ 1089 "VC ECU message: pcs interface";
CM_ SG_ 1089 VC_pcsInterfaceMuxIndex "VC ECU: pcs interface mux index";
CM_ SG_ 1089 VC_pcsInterfaceCounter "VC ECU: pcs interface counter";
CM_ SG_ 1089 VC_pcsInterfaceChecksum "VC ECU: pcs interface checksum";
CM_ SG_ 1089 VC_pcsLVVoltageTarget "VC ECU: pcs LV voltage target";
CM_ SG_ 1089 VC_pcsLVMinVoltageLimit "VC ECU: pcs LV min voltage limit";
CM_ SG_ 1089 VC_pcsLVMaxVoltageLimit "VC ECU: pcs LV max voltage limit";
CM_ SG_ 1089 VC_goodForPCSPowerCycle "VC ECU: good for PCS power cycle";
CM_ SG_ 1089 VC_LVBatteryCannotSupportVehicle "VC ECU: LV battery cannot support vehicle";
CM_ SG_ 1089 VC_pcsResistanceFiltered "VC ECU: pcs resistance filtered; raw 65535 = signal not available (SNA)";
CM_ SG_ 1089 VC_pcsLVMaxDchrgCurrentLimit "VC ECU: pcs LV max dchrg current limit";
CM_ SG_ 1089 VC_defaultPcsLVVoltageTarget "VC ECU: default pcs LV voltage target";
CM_ SG_ 1089 VC_lvHwProtSelfTestActive "Reports whether Low Voltage (LV) Hardware (HW) protection self-tests are running or about to run due to a retry.";
CM_ SG_ 1089 VC_lvBatteryDischargeRequest "VC ECU: lv battery discharge request";
CM_ BO_ 1091 "VC ECU message: pcs management";
CM_ SG_ 1091 VC_pcsManagementChecksum "VC ECU: pcs management checksum";
CM_ SG_ 1091 VC_pcsManagementCounter "VC ECU: pcs management counter";
CM_ SG_ 1091 VC_pcsManagementMuxIndex "VC ECU: pcs management mux index";
CM_ SG_ 1091 VC_dcdcLVVoltageTargetMax "VC ECU: dcdc LV voltage target max";
CM_ SG_ 1091 VC_dcdcLVVoltageTargetMin "VC ECU: dcdc LV voltage target min";
CM_ SG_ 1091 VC_dcdcLVInputPowerLimit "VC ECU: dcdc LV input power limit";
BA_DEF_ BO_ "GenMsgCycleTime" INT 0 3600000;
BA_DEF_ BO_ "GenMsgSendType" ENUM "Cyclic","NotUsed","NotUsed","NotUsed","NotUsed","NotUsed","NotUsed","IfActive","NoMsgSendType","NotUsed";
BA_DEF_ BO_ "VFrameFormat" ENUM "StandardCAN","ExtendedCAN","reserved","J1939PG","reserved","reserved","reserved","reserved","reserved","reserved","reserved","reserved","reserved","reserved","StandardCAN_FD","ExtendedCAN_FD";
BA_DEF_ BO_ "CANFD_BRS" ENUM "0","1";
BA_DEF_ SG_ "GenSigSNA" STRING;
BA_DEF_ SG_ "SystemSignalLongSymbol" STRING;
BA_DEF_ SG_ "Confidence" ENUM "validated","plausible","layout-only","contradicted";
BA_DEF_DEF_ "GenMsgCycleTime" 0;
BA_DEF_DEF_ "GenMsgSendType" "NoMsgSendType";
BA_DEF_DEF_ "VFrameFormat" "StandardCAN";
BA_DEF_DEF_ "CANFD_BRS" "1";
BA_DEF_DEF_ "GenSigSNA" "";
BA_DEF_DEF_ "SystemSignalLongSymbol" "";
BA_DEF_DEF_ "Confidence" "layout-only";
BA_ "GenMsgCycleTime" BO_ 537 100;
BA_ "GenMsgSendType" BO_ 537 0;
BA_ "GenMsgCycleTime" BO_ 602 1000;
BA_ "GenMsgSendType" BO_ 602 0;
BA_ "GenMsgCycleTime" BO_ 570 1000;
BA_ "GenMsgSendType" BO_ 570 0;
BA_ "GenMsgCycleTime" BO_ 1067 100;
BA_ "GenMsgSendType" BO_ 1067 0;
BA_ "GenMsgCycleTime" BO_ 761 100;
BA_ "GenMsgSendType" BO_ 761 0;
BA_ "GenMsgCycleTime" BO_ 825 100;
BA_ "GenMsgSendType" BO_ 825 0;
BA_ "GenMsgCycleTime" BO_ 1817 50;
BA_ "GenMsgSendType" BO_ 1817 0;
BA_ "GenMsgCycleTime" BO_ 1824 10000;
BA_ "GenMsgSendType" BO_ 1824 0;
BA_ "GenMsgCycleTime" BO_ 793 1000;
BA_ "GenMsgSendType" BO_ 793 0;
BA_ "GenMsgCycleTime" BO_ 505 100;
BA_ "GenMsgSendType" BO_ 505 0;
BA_ "GenMsgCycleTime" BO_ 281 100;
BA_ "GenMsgSendType" BO_ 281 0;
BA_ "GenMsgCycleTime" BO_ 1850 1000;
BA_ "GenMsgSendType" BO_ 1850 0;
BA_ "GenMsgCycleTime" BO_ 1655 40;
BA_ "GenMsgSendType" BO_ 1655 0;
BA_ "GenMsgCycleTime" BO_ 1816 200;
BA_ "GenMsgSendType" BO_ 1816 0;
BA_ "GenMsgCycleTime" BO_ 1089 50;
BA_ "GenMsgSendType" BO_ 1089 0;
BA_ "GenMsgCycleTime" BO_ 1091 500;
BA_ "GenMsgSendType" BO_ 1091 0;
BA_ "Confidence" SG_ 537 VCSEC_TPMSDataIndex 1;
BA_ "Confidence" SG_ 537 VCSEC_TPMSCapabilityPressureInAd 0;
BA_ "SystemSignalLongSymbol" SG_ 537 VCSEC_TPMSCapabilityPressureInAd "VCSEC_TPMSCapabilityPressureInAdv0";
BA_ "Confidence" SG_ 537 VCSEC_TPMSCapabilityConfigurable 0;
BA_ "SystemSignalLongSymbol" SG_ 537 VCSEC_TPMSCapabilityConfigurable "VCSEC_TPMSCapabilityConfigurablePressure0";
BA_ "Confidence" SG_ 537 VCSEC_TPMSPressureRateOfChange0 0;
BA_ "Confidence" SG_ 537 VCSEC_TPMSPressure0 0;
BA_ "GenSigSNA" SG_ 537 VCSEC_TPMSPressure0 "511";
BA_ "Confidence" SG_ 537 VCSEC_TPMSTemperature0 0;
BA_ "GenSigSNA" SG_ 537 VCSEC_TPMSTemperature0 "255";
BA_ "Confidence" SG_ 537 VCSEC_TPMSBatVoltage0 0;
BA_ "GenSigSNA" SG_ 537 VCSEC_TPMSBatVoltage0 "255";
BA_ "Confidence" SG_ 537 VCSEC_TPMSLocation0 0;
BA_ "Confidence" SG_ 537 VCSEC_TPMSTemperatureCompensated 0;
BA_ "GenSigSNA" SG_ 537 VCSEC_TPMSTemperatureCompensated "511";
BA_ "SystemSignalLongSymbol" SG_ 537 VCSEC_TPMSTemperatureCompensated "VCSEC_TPMSTemperatureCompensatedPressure0";
BA_ "Confidence" SG_ 537 VCSEC_TPMSCapabilityPressur_0001 0;
BA_ "SystemSignalLongSymbol" SG_ 537 VCSEC_TPMSCapabilityPressur_0001 "VCSEC_TPMSCapabilityPressureInAdv1";
BA_ "Confidence" SG_ 537 VCSEC_TPMSCapabilityConfigu_0001 0;
BA_ "SystemSignalLongSymbol" SG_ 537 VCSEC_TPMSCapabilityConfigu_0001 "VCSEC_TPMSCapabilityConfigurablePressure1";
BA_ "Confidence" SG_ 537 VCSEC_TPMSPressureRateOfChange1 0;
BA_ "Confidence" SG_ 537 VCSEC_TPMSPressure1 0;
BA_ "GenSigSNA" SG_ 537 VCSEC_TPMSPressure1 "511";
BA_ "Confidence" SG_ 537 VCSEC_TPMSTemperature1 0;
BA_ "GenSigSNA" SG_ 537 VCSEC_TPMSTemperature1 "255";
BA_ "Confidence" SG_ 537 VCSEC_TPMSBatVoltage1 0;
BA_ "GenSigSNA" SG_ 537 VCSEC_TPMSBatVoltage1 "255";
BA_ "Confidence" SG_ 537 VCSEC_TPMSLocation1 0;
BA_ "Confidence" SG_ 537 VCSEC_TPMSTemperatureCompen_0001 0;
BA_ "GenSigSNA" SG_ 537 VCSEC_TPMSTemperatureCompen_0001 "511";
BA_ "SystemSignalLongSymbol" SG_ 537 VCSEC_TPMSTemperatureCompen_0001 "VCSEC_TPMSTemperatureCompensatedPressure1";
BA_ "Confidence" SG_ 537 VCSEC_TPMSCapabilityPressur_0002 0;
BA_ "SystemSignalLongSymbol" SG_ 537 VCSEC_TPMSCapabilityPressur_0002 "VCSEC_TPMSCapabilityPressureInAdv2";
BA_ "Confidence" SG_ 537 VCSEC_TPMSCapabilityConfigu_0002 0;
BA_ "SystemSignalLongSymbol" SG_ 537 VCSEC_TPMSCapabilityConfigu_0002 "VCSEC_TPMSCapabilityConfigurablePressure2";
BA_ "Confidence" SG_ 537 VCSEC_TPMSPressureRateOfChange2 0;
BA_ "Confidence" SG_ 537 VCSEC_TPMSPressure2 0;
BA_ "GenSigSNA" SG_ 537 VCSEC_TPMSPressure2 "511";
BA_ "Confidence" SG_ 537 VCSEC_TPMSTemperature2 0;
BA_ "GenSigSNA" SG_ 537 VCSEC_TPMSTemperature2 "255";
BA_ "Confidence" SG_ 537 VCSEC_TPMSBatVoltage2 0;
BA_ "GenSigSNA" SG_ 537 VCSEC_TPMSBatVoltage2 "255";
BA_ "Confidence" SG_ 537 VCSEC_TPMSLocation2 0;
BA_ "Confidence" SG_ 537 VCSEC_TPMSTemperatureCompen_0002 0;
BA_ "GenSigSNA" SG_ 537 VCSEC_TPMSTemperatureCompen_0002 "511";
BA_ "SystemSignalLongSymbol" SG_ 537 VCSEC_TPMSTemperatureCompen_0002 "VCSEC_TPMSTemperatureCompensatedPressure2";
BA_ "Confidence" SG_ 537 VCSEC_TPMSCapabilityPressur_0003 0;
BA_ "SystemSignalLongSymbol" SG_ 537 VCSEC_TPMSCapabilityPressur_0003 "VCSEC_TPMSCapabilityPressureInAdv3";
BA_ "Confidence" SG_ 537 VCSEC_TPMSCapabilityConfigu_0003 0;
BA_ "SystemSignalLongSymbol" SG_ 537 VCSEC_TPMSCapabilityConfigu_0003 "VCSEC_TPMSCapabilityConfigurablePressure3";
BA_ "Confidence" SG_ 537 VCSEC_TPMSPressureRateOfChange3 0;
BA_ "Confidence" SG_ 537 VCSEC_TPMSPressure3 0;
BA_ "GenSigSNA" SG_ 537 VCSEC_TPMSPressure3 "511";
BA_ "Confidence" SG_ 537 VCSEC_TPMSTemperature3 0;
BA_ "GenSigSNA" SG_ 537 VCSEC_TPMSTemperature3 "255";
BA_ "Confidence" SG_ 537 VCSEC_TPMSBatVoltage3 0;
BA_ "GenSigSNA" SG_ 537 VCSEC_TPMSBatVoltage3 "255";
BA_ "Confidence" SG_ 537 VCSEC_TPMSLocation3 0;
BA_ "Confidence" SG_ 537 VCSEC_TPMSTemperatureCompen_0003 0;
BA_ "GenSigSNA" SG_ 537 VCSEC_TPMSTemperatureCompen_0003 "511";
BA_ "SystemSignalLongSymbol" SG_ 537 VCSEC_TPMSTemperatureCompen_0003 "VCSEC_TPMSTemperatureCompensatedPressure3";
BA_ "Confidence" SG_ 537 VCSEC_TPMSRecommendedColdPressur 0;
BA_ "GenSigSNA" SG_ 537 VCSEC_TPMSRecommendedColdPressur "255";
BA_ "SystemSignalLongSymbol" SG_ 537 VCSEC_TPMSRecommendedColdPressur "VCSEC_TPMSRecommendedColdPressureFront";
BA_ "Confidence" SG_ 537 VCSEC_TPMSRecommendedColdPr_0001 0;
BA_ "GenSigSNA" SG_ 537 VCSEC_TPMSRecommendedColdPr_0001 "255";
BA_ "SystemSignalLongSymbol" SG_ 537 VCSEC_TPMSRecommendedColdPr_0001 "VCSEC_TPMSRecommendedColdPressureRear";
BA_ "Confidence" SG_ 537 VCSEC_TPMSFeature0 0;
BA_ "Confidence" SG_ 537 VCSEC_TPMSFeature1 0;
BA_ "Confidence" SG_ 537 VCSEC_TPMSFeature0Count 0;
BA_ "Confidence" SG_ 537 VCSEC_TPMSFeature0TimeS 0;
BA_ "Confidence" SG_ 537 VCSEC_TPMSAutonomyStatus 0;
BA_ "Confidence" SG_ 537 VCSEC_TPMSAutonomyStatusMIATimeS 0;
BA_ "Confidence" SG_ 537 VCSEC_TPMSLastKnownPressureFL 0;
BA_ "GenSigSNA" SG_ 537 VCSEC_TPMSLastKnownPressureFL "255";
BA_ "Confidence" SG_ 537 VCSEC_TPMSLastKnownPressureFR 0;
BA_ "GenSigSNA" SG_ 537 VCSEC_TPMSLastKnownPressureFR "255";
BA_ "Confidence" SG_ 537 VCSEC_TPMSLastKnownPressureRL 0;
BA_ "GenSigSNA" SG_ 537 VCSEC_TPMSLastKnownPressureRL "255";
BA_ "Confidence" SG_ 537 VCSEC_TPMSLastKnownPressureRR 0;
BA_ "GenSigSNA" SG_ 537 VCSEC_TPMSLastKnownPressureRR "255";
BA_ "Confidence" SG_ 602 VCSEC_TPMSDisplayPressureFL 0;
BA_ "GenSigSNA" SG_ 602 VCSEC_TPMSDisplayPressureFL "255";
BA_ "Confidence" SG_ 602 VCSEC_TPMSDisplayPressureFR 0;
BA_ "GenSigSNA" SG_ 602 VCSEC_TPMSDisplayPressureFR "255";
BA_ "Confidence" SG_ 602 VCSEC_TPMSDisplayPressureRL 0;
BA_ "GenSigSNA" SG_ 602 VCSEC_TPMSDisplayPressureRL "255";
BA_ "Confidence" SG_ 602 VCSEC_TPMSDisplayPressureRR 0;
BA_ "GenSigSNA" SG_ 602 VCSEC_TPMSDisplayPressureRR "255";
BA_ "Confidence" SG_ 602 VCSEC_TPMSTellTale 0;
BA_ "Confidence" SG_ 602 VCSEC_TPMSDisplaySoftWarningIndi 0;
BA_ "SystemSignalLongSymbol" SG_ 602 VCSEC_TPMSDisplaySoftWarningIndi "VCSEC_TPMSDisplaySoftWarningIndicationFL";
BA_ "Confidence" SG_ 602 VCSEC_TPMSDisplaySoftWarnin_0001 0;
BA_ "SystemSignalLongSymbol" SG_ 602 VCSEC_TPMSDisplaySoftWarnin_0001 "VCSEC_TPMSDisplaySoftWarningIndicationFR";
BA_ "Confidence" SG_ 602 VCSEC_TPMSDisplaySoftWarnin_0002 0;
BA_ "SystemSignalLongSymbol" SG_ 602 VCSEC_TPMSDisplaySoftWarnin_0002 "VCSEC_TPMSDisplaySoftWarningIndicationRL";
BA_ "Confidence" SG_ 602 VCSEC_TPMSDisplaySoftWarnin_0003 0;
BA_ "SystemSignalLongSymbol" SG_ 602 VCSEC_TPMSDisplaySoftWarnin_0003 "VCSEC_TPMSDisplaySoftWarningIndicationRR";
BA_ "Confidence" SG_ 602 VCSEC_TPMSDisplayHardWarningIndi 0;
BA_ "SystemSignalLongSymbol" SG_ 602 VCSEC_TPMSDisplayHardWarningIndi "VCSEC_TPMSDisplayHardWarningIndicationFL";
BA_ "Confidence" SG_ 602 VCSEC_TPMSDisplayHardWarnin_0001 0;
BA_ "SystemSignalLongSymbol" SG_ 602 VCSEC_TPMSDisplayHardWarnin_0001 "VCSEC_TPMSDisplayHardWarningIndicationFR";
BA_ "Confidence" SG_ 602 VCSEC_TPMSDisplayHardWarnin_0002 0;
BA_ "SystemSignalLongSymbol" SG_ 602 VCSEC_TPMSDisplayHardWarnin_0002 "VCSEC_TPMSDisplayHardWarningIndicationRL";
BA_ "Confidence" SG_ 602 VCSEC_TPMSDisplayHardWarnin_0003 0;
BA_ "SystemSignalLongSymbol" SG_ 602 VCSEC_TPMSDisplayHardWarnin_0003 "VCSEC_TPMSDisplayHardWarningIndicationRR";
BA_ "Confidence" SG_ 570 VCSEC_TPMSStatusIndex 1;
BA_ "Confidence" SG_ 570 VCSEC_TPMSSystemState 0;
BA_ "Confidence" SG_ 570 VCSEC_TPMSSensorMACAddress0 0;
BA_ "Confidence" SG_ 570 VCSEC_TPMSSensorMACAddress1 0;
BA_ "Confidence" SG_ 570 VCSEC_TPMSSensorMACAddress2 0;
BA_ "Confidence" SG_ 570 VCSEC_TPMSSensorMACAddress3 0;
BA_ "Confidence" SG_ 570 VCSEC_BLEUnsuccessfulConnEventRa 0;
BA_ "GenSigSNA" SG_ 570 VCSEC_BLEUnsuccessfulConnEventRa "1023";
BA_ "SystemSignalLongSymbol" SG_ 570 VCSEC_BLEUnsuccessfulConnEventRa "VCSEC_BLEUnsuccessfulConnEventRate0";
BA_ "Confidence" SG_ 570 VCSEC_BLEUnsuccessfulConnEv_0001 0;
BA_ "GenSigSNA" SG_ 570 VCSEC_BLEUnsuccessfulConnEv_0001 "1023";
BA_ "SystemSignalLongSymbol" SG_ 570 VCSEC_BLEUnsuccessfulConnEv_0001 "VCSEC_BLEUnsuccessfulConnEventRate1";
BA_ "Confidence" SG_ 570 VCSEC_BLEUnsuccessfulConnEv_0002 0;
BA_ "GenSigSNA" SG_ 570 VCSEC_BLEUnsuccessfulConnEv_0002 "1023";
BA_ "SystemSignalLongSymbol" SG_ 570 VCSEC_BLEUnsuccessfulConnEv_0002 "VCSEC_BLEUnsuccessfulConnEventRate2";
BA_ "Confidence" SG_ 570 VCSEC_BLEUnsuccessfulConnEv_0003 0;
BA_ "GenSigSNA" SG_ 570 VCSEC_BLEUnsuccessfulConnEv_0003 "1023";
BA_ "SystemSignalLongSymbol" SG_ 570 VCSEC_BLEUnsuccessfulConnEv_0003 "VCSEC_BLEUnsuccessfulConnEventRate3";
BA_ "Confidence" SG_ 570 VCSEC_TPMSSensorTIAppCRC0 0;
BA_ "GenSigSNA" SG_ 570 VCSEC_TPMSSensorTIAppCRC0 "0";
BA_ "Confidence" SG_ 570 VCSEC_TPMSSensorMLXAppCRC0 0;
BA_ "GenSigSNA" SG_ 570 VCSEC_TPMSSensorMLXAppCRC0 "0";
BA_ "Confidence" SG_ 570 VCSEC_TPMSSensorTIAppCRC1 0;
BA_ "GenSigSNA" SG_ 570 VCSEC_TPMSSensorTIAppCRC1 "0";
BA_ "Confidence" SG_ 570 VCSEC_TPMSSensorMLXAppCRC1 0;
BA_ "GenSigSNA" SG_ 570 VCSEC_TPMSSensorMLXAppCRC1 "0";
BA_ "Confidence" SG_ 570 VCSEC_TPMSSensorTIAppCRC2 0;
BA_ "GenSigSNA" SG_ 570 VCSEC_TPMSSensorTIAppCRC2 "0";
BA_ "Confidence" SG_ 570 VCSEC_TPMSSensorMLXAppCRC2 0;
BA_ "GenSigSNA" SG_ 570 VCSEC_TPMSSensorMLXAppCRC2 "0";
BA_ "Confidence" SG_ 570 VCSEC_TPMSSensorTIAppCRC3 0;
BA_ "GenSigSNA" SG_ 570 VCSEC_TPMSSensorTIAppCRC3 "0";
BA_ "Confidence" SG_ 570 VCSEC_TPMSSensorMLXAppCRC3 0;
BA_ "GenSigSNA" SG_ 570 VCSEC_TPMSSensorMLXAppCRC3 "0";
BA_ "Confidence" SG_ 570 VCSEC_TPMStotalAwakeTime0 0;
BA_ "Confidence" SG_ 570 VCSEC_TPMSTrimAdjusted0 0;
BA_ "Confidence" SG_ 570 VCSEC_TPMSGenealogySensorState0 0;
BA_ "Confidence" SG_ 570 VCSEC_TPMSSensorType0 0;
BA_ "Confidence" SG_ 570 VCSEC_TPMStotalAwakeTime1 0;
BA_ "Confidence" SG_ 570 VCSEC_TPMSTrimAdjusted1 0;
BA_ "Confidence" SG_ 570 VCSEC_TPMSGenealogySensorState1 0;
BA_ "Confidence" SG_ 570 VCSEC_TPMSSensorType1 0;
BA_ "Confidence" SG_ 570 VCSEC_TPMStotalAwakeTime2 0;
BA_ "Confidence" SG_ 570 VCSEC_TPMSTrimAdjusted2 0;
BA_ "Confidence" SG_ 570 VCSEC_TPMSGenealogySensorState2 0;
BA_ "Confidence" SG_ 570 VCSEC_TPMSSensorType2 0;
BA_ "Confidence" SG_ 570 VCSEC_TPMStotalAwakeTime3 0;
BA_ "Confidence" SG_ 570 VCSEC_TPMSTrimAdjusted3 0;
BA_ "Confidence" SG_ 570 VCSEC_TPMSGenealogySensorState3 0;
BA_ "Confidence" SG_ 570 VCSEC_TPMSSensorType3 0;
BA_ "Confidence" SG_ 570 VCSEC_TPMSSensor0Hash 0;
BA_ "Confidence" SG_ 570 VCSEC_TPMSSensor1Hash 0;
BA_ "Confidence" SG_ 570 VCSEC_TPMSSensor2Hash 0;
BA_ "Confidence" SG_ 570 VCSEC_TPMSSensor3Hash 0;
BA_ "Confidence" SG_ 570 VCSEC_TPMSLastLocationSensor0 0;
BA_ "Confidence" SG_ 570 VCSEC_TPMSLastLocationSensor1 0;
BA_ "Confidence" SG_ 570 VCSEC_TPMSLastLocationSensor2 0;
BA_ "Confidence" SG_ 570 VCSEC_TPMSLastLocationSensor3 0;
BA_ "Confidence" SG_ 570 VCSEC_TPMSTemperatureCompensated 0;
BA_ "GenSigSNA" SG_ 570 VCSEC_TPMSTemperatureCompensated "255";
BA_ "SystemSignalLongSymbol" SG_ 570 VCSEC_TPMSTemperatureCompensated "VCSEC_TPMSTemperatureCompensatedBatVoltage0";
BA_ "Confidence" SG_ 570 VCSEC_TPMSTemperatureCompen_0001 0;
BA_ "GenSigSNA" SG_ 570 VCSEC_TPMSTemperatureCompen_0001 "255";
BA_ "SystemSignalLongSymbol" SG_ 570 VCSEC_TPMSTemperatureCompen_0001 "VCSEC_TPMSTemperatureCompensatedBatVoltage1";
BA_ "Confidence" SG_ 570 VCSEC_TPMSTemperatureCompen_0002 0;
BA_ "GenSigSNA" SG_ 570 VCSEC_TPMSTemperatureCompen_0002 "255";
BA_ "SystemSignalLongSymbol" SG_ 570 VCSEC_TPMSTemperatureCompen_0002 "VCSEC_TPMSTemperatureCompensatedBatVoltage2";
BA_ "Confidence" SG_ 570 VCSEC_TPMSTemperatureCompen_0003 0;
BA_ "GenSigSNA" SG_ 570 VCSEC_TPMSTemperatureCompen_0003 "255";
BA_ "SystemSignalLongSymbol" SG_ 570 VCSEC_TPMSTemperatureCompen_0003 "VCSEC_TPMSTemperatureCompensatedBatVoltage3";
BA_ "Confidence" SG_ 570 VCSEC_TPMSFilteredBatVoltage0 0;
BA_ "GenSigSNA" SG_ 570 VCSEC_TPMSFilteredBatVoltage0 "255";
BA_ "Confidence" SG_ 570 VCSEC_TPMSFilteredBatVoltage2 0;
BA_ "GenSigSNA" SG_ 570 VCSEC_TPMSFilteredBatVoltage2 "255";
BA_ "Confidence" SG_ 570 VCSEC_TPMSFilteredBatVoltage1 0;
BA_ "GenSigSNA" SG_ 570 VCSEC_TPMSFilteredBatVoltage1 "255";
BA_ "Confidence" SG_ 570 VCSEC_TPMSFilteredBatVoltage3 0;
BA_ "GenSigSNA" SG_ 570 VCSEC_TPMSFilteredBatVoltage3 "255";
BA_ "Confidence" SG_ 1067 VCSEC_UWBEndpointIndex 1;
BA_ "Confidence" SG_ 1067 VCSEC_UWBExpectedEndpointsActive 0;
BA_ "SystemSignalLongSymbol" SG_ 1067 VCSEC_UWBExpectedEndpointsActive "VCSEC_UWBExpectedEndpointsActive0";
BA_ "Confidence" SG_ 1067 VCSEC_UWBExpectedEndpointsA_0001 0;
BA_ "SystemSignalLongSymbol" SG_ 1067 VCSEC_UWBExpectedEndpointsA_0001 "VCSEC_UWBExpectedEndpointsActive1";
BA_ "Confidence" SG_ 1067 VCSEC_UWBExpectedEndpointsA_0002 0;
BA_ "SystemSignalLongSymbol" SG_ 1067 VCSEC_UWBExpectedEndpointsA_0002 "VCSEC_UWBExpectedEndpointsActive2";
BA_ "Confidence" SG_ 1067 VCSEC_UWBExpectedEndpointsA_0003 0;
BA_ "SystemSignalLongSymbol" SG_ 1067 VCSEC_UWBExpectedEndpointsA_0003 "VCSEC_UWBExpectedEndpointsActive3";
BA_ "Confidence" SG_ 1067 VCSEC_UWBRearRightDistance0 0;
BA_ "GenSigSNA" SG_ 1067 VCSEC_UWBRearRightDistance0 "4095";
BA_ "Confidence" SG_ 1067 VCSEC_UWBRearRightDistance1 0;
BA_ "GenSigSNA" SG_ 1067 VCSEC_UWBRearRightDistance1 "4095";
BA_ "Confidence" SG_ 1067 VCSEC_UWBRearRightDistance2 0;
BA_ "GenSigSNA" SG_ 1067 VCSEC_UWBRearRightDistance2 "4095";
BA_ "Confidence" SG_ 1067 VCSEC_UWBLeftDistance3 0;
BA_ "GenSigSNA" SG_ 1067 VCSEC_UWBLeftDistance3 "4095";
BA_ "Confidence" SG_ 1067 VCSEC_UWBRightDistance3 0;
BA_ "GenSigSNA" SG_ 1067 VCSEC_UWBRightDistance3 "4095";
BA_ "Confidence" SG_ 1067 VCSEC_UWBRearRightDistance3 0;
BA_ "GenSigSNA" SG_ 1067 VCSEC_UWBRearRightDistance3 "4095";
BA_ "Confidence" SG_ 1067 VCSEC_UWBRearLeftDistance3 0;
BA_ "GenSigSNA" SG_ 1067 VCSEC_UWBRearLeftDistance3 "4095";
BA_ "Confidence" SG_ 1067 VCSEC_UWBCenterDistance3 0;
BA_ "GenSigSNA" SG_ 1067 VCSEC_UWBCenterDistance3 "4095";
BA_ "Confidence" SG_ 1067 VCSEC_UWBLeftDistance2 0;
BA_ "GenSigSNA" SG_ 1067 VCSEC_UWBLeftDistance2 "4095";
BA_ "Confidence" SG_ 1067 VCSEC_UWBRightDistance2 0;
BA_ "GenSigSNA" SG_ 1067 VCSEC_UWBRightDistance2 "4095";
BA_ "Confidence" SG_ 1067 VCSEC_UWBRearDistance2 0;
BA_ "GenSigSNA" SG_ 1067 VCSEC_UWBRearDistance2 "4095";
BA_ "Confidence" SG_ 1067 VCSEC_UWBRearLeftDistance2 0;
BA_ "GenSigSNA" SG_ 1067 VCSEC_UWBRearLeftDistance2 "4095";
BA_ "Confidence" SG_ 1067 VCSEC_UWBCenterDistance2 0;
BA_ "GenSigSNA" SG_ 1067 VCSEC_UWBCenterDistance2 "4095";
BA_ "Confidence" SG_ 1067 VCSEC_UWBLeftDistance1 0;
BA_ "GenSigSNA" SG_ 1067 VCSEC_UWBLeftDistance1 "4095";
BA_ "Confidence" SG_ 1067 VCSEC_UWBRightDistance1 0;
BA_ "GenSigSNA" SG_ 1067 VCSEC_UWBRightDistance1 "4095";
BA_ "Confidence" SG_ 1067 VCSEC_UWBRearDistance1 0;
BA_ "GenSigSNA" SG_ 1067 VCSEC_UWBRearDistance1 "4095";
BA_ "Confidence" SG_ 1067 VCSEC_UWBRearLeftDistance1 0;
BA_ "GenSigSNA" SG_ 1067 VCSEC_UWBRearLeftDistance1 "4095";
BA_ "Confidence" SG_ 1067 VCSEC_UWBCenterDistance1 0;
BA_ "GenSigSNA" SG_ 1067 VCSEC_UWBCenterDistance1 "4095";
BA_ "Confidence" SG_ 1067 VCSEC_UWBLeftDistance0 0;
BA_ "GenSigSNA" SG_ 1067 VCSEC_UWBLeftDistance0 "4095";
BA_ "Confidence" SG_ 1067 VCSEC_UWBRightDistance0 0;
BA_ "GenSigSNA" SG_ 1067 VCSEC_UWBRightDistance0 "4095";
BA_ "Confidence" SG_ 1067 VCSEC_UWBRearDistance0 0;
BA_ "GenSigSNA" SG_ 1067 VCSEC_UWBRearDistance0 "4095";
BA_ "Confidence" SG_ 1067 VCSEC_UWBRearLeftDistance0 0;
BA_ "GenSigSNA" SG_ 1067 VCSEC_UWBRearLeftDistance0 "4095";
BA_ "Confidence" SG_ 1067 VCSEC_UWBCenterDistance0 0;
BA_ "GenSigSNA" SG_ 1067 VCSEC_UWBCenterDistance0 "4095";
BA_ "Confidence" SG_ 761 VCSEC_activeKeyDebug 0;
BA_ "Confidence" SG_ 761 VCSEC_bleChannelDisconnected 0;
BA_ "Confidence" SG_ 761 VCSEC_bleDisconnectionReason 0;
BA_ "Confidence" SG_ 761 VCSEC_bleConnetionAttemptWLEntry 0;
BA_ "Confidence" SG_ 761 VCSEC_AdditionalAuthInfoIndex 1;
BA_ "Confidence" SG_ 761 VCSEC_activeKeyReason 0;
BA_ "Confidence" SG_ 761 VCSEC_activeKeySHA1 0;
BA_ "Confidence" SG_ 761 VCSEC_algoUsedForSummonRange0 0;
BA_ "Confidence" SG_ 761 VCSEC_keyWithinSummonRange0 0;
BA_ "Confidence" SG_ 761 VCSEC_algoUsedForSummonRange1 0;
BA_ "Confidence" SG_ 761 VCSEC_keyWithinSummonRange1 0;
BA_ "Confidence" SG_ 761 VCSEC_algoUsedForSummonRange2 0;
BA_ "Confidence" SG_ 761 VCSEC_keyWithinSummonRange2 0;
BA_ "Confidence" SG_ 761 VCSEC_BLEDeviceWithinSummonRange 0;
BA_ "Confidence" SG_ 761 VCSEC_algoUWBInteriorPresence 0;
BA_ "Confidence" SG_ 761 VCSEC_frunkOpenSuggestionRespons 0;
BA_ "SystemSignalLongSymbol" SG_ 761 VCSEC_frunkOpenSuggestionRespons "VCSEC_frunkOpenSuggestionResponse";
BA_ "Confidence" SG_ 761 VCSEC_NFCAuthFromBPillarFormFact 0;
BA_ "SystemSignalLongSymbol" SG_ 761 VCSEC_NFCAuthFromBPillarFormFact "VCSEC_NFCAuthFromBPillarFormFactor";
BA_ "Confidence" SG_ 761 VCSEC_NFCAuthFromCenterConsoleFo 0;
BA_ "SystemSignalLongSymbol" SG_ 761 VCSEC_NFCAuthFromCenterConsoleFo "VCSEC_NFCAuthFromCenterConsoleFormFactor";
BA_ "Confidence" SG_ 761 VCSEC_trunkOpenSuggestionRespons 0;
BA_ "SystemSignalLongSymbol" SG_ 761 VCSEC_trunkOpenSuggestionRespons "VCSEC_trunkOpenSuggestionResponse";
BA_ "Confidence" SG_ 761 VCSEC_algoTrunkSuggestionRaw 0;
BA_ "Confidence" SG_ 761 VCSEC_algoTrunkSuggestionProc 0;
BA_ "Confidence" SG_ 761 VCSEC_algoTrunkSuggestionRearmAl 0;
BA_ "SystemSignalLongSymbol" SG_ 761 VCSEC_algoTrunkSuggestionRearmAl "VCSEC_algoTrunkSuggestionRearmAllowed";
BA_ "Confidence" SG_ 761 VCSEC_algoFrunkSuggestionRaw 0;
BA_ "Confidence" SG_ 761 VCSEC_algoFrunkSuggestionProc 0;
BA_ "Confidence" SG_ 761 VCSEC_algoFrunkSuggestionRearmAl 0;
BA_ "SystemSignalLongSymbol" SG_ 761 VCSEC_algoFrunkSuggestionRearmAl "VCSEC_algoFrunkSuggestionRearmAllowed";
BA_ "Confidence" SG_ 825 VCSEC_BLEConnectionCounter 0;
BA_ "Confidence" SG_ 825 VCSEC_authRejectionReason 0;
BA_ "Confidence" SG_ 825 VCSEC_IDRequested 0;
BA_ "Confidence" SG_ 825 VCSEC_operationMode 0;
BA_ "Confidence" SG_ 825 VCSEC_vehicleLockStatus 0;
BA_ "GenSigSNA" SG_ 825 VCSEC_vehicleLockStatus "0";
BA_ "Confidence" SG_ 825 VCSEC_authenticationStatus 0;
BA_ "Confidence" SG_ 825 VCSEC_chargePortLockStatus 0;
BA_ "Confidence" SG_ 825 VCSEC_leftFrontLockStatus 0;
BA_ "Confidence" SG_ 825 VCSEC_leftRearLockStatus 0;
BA_ "Confidence" SG_ 825 VCSEC_rightFrontLockStatus 0;
BA_ "Confidence" SG_ 825 VCSEC_rightRearLockStatus 0;
BA_ "Confidence" SG_ 825 VCSEC_trunkLockStatus 0;
BA_ "Confidence" SG_ 825 VCSEC_lockRequestType 0;
BA_ "Confidence" SG_ 825 VCSEC_summonRequest 0;
BA_ "GenSigSNA" SG_ 825 VCSEC_summonRequest "5";
BA_ "Confidence" SG_ 825 VCSEC_3rdPartyPLGRequest 0;
BA_ "GenSigSNA" SG_ 825 VCSEC_3rdPartyPLGRequest "3";
BA_ "Confidence" SG_ 825 VCSEC_3rdPartyFrunkPLGRequest 0;
BA_ "GenSigSNA" SG_ 825 VCSEC_3rdPartyFrunkPLGRequest "3";
BA_ "Confidence" SG_ 825 VCSEC_MCUCommandType 0;
BA_ "Confidence" SG_ 825 VCSEC_frunkLockStatus 0;
BA_ "Confidence" SG_ 825 VCSEC_usingModifiedMACAddress 0;
BA_ "Confidence" SG_ 825 VCSEC_isKeyWithinSummonRange 0;
BA_ "Confidence" SG_ 825 VCSEC_isBLEDeviceWithinSummonRan 0;
BA_ "SystemSignalLongSymbol" SG_ 825 VCSEC_isBLEDeviceWithinSummonRan "VCSEC_isBLEDeviceWithinSummonRange";
BA_ "Confidence" SG_ 825 VCSEC_alarmStatus 0;
BA_ "GenSigSNA" SG_ 825 VCSEC_alarmStatus "15";
BA_ "Confidence" SG_ 825 VCSEC_serviceDiagnosticRequest 0;
BA_ "Confidence" SG_ 825 VCSEC_immobilizerState 0;
BA_ "Confidence" SG_ 825 VCSEC_lockIndicationRequest 0;
BA_ "GenSigSNA" SG_ 825 VCSEC_lockIndicationRequest "0";
BA_ "Confidence" SG_ 825 VCSEC_simpleLockStatus 0;
BA_ "GenSigSNA" SG_ 825 VCSEC_simpleLockStatus "0";
BA_ "Confidence" SG_ 825 VCSEC_keyChannelIndexed 0;
BA_ "GenSigSNA" SG_ 825 VCSEC_keyChannelIndexed "15";
BA_ "Confidence" SG_ 825 VCSEC_authRequested 0;
BA_ "Confidence" SG_ 825 VCSEC_remoteStartActive 0;
BA_ "Confidence" SG_ 825 VCSEC_keyPairDesired 0;
BA_ "Confidence" SG_ 1817 VCSEC_debug100msIndex 1;
BA_ "Confidence" SG_ 1817 VCSEC_walkAwayLockKeyState 0;
BA_ "Confidence" SG_ 1817 VCSEC_thresholdOffsetVersion 0;
BA_ "Confidence" SG_ 1817 VCSEC_walkAwayLockState 0;
BA_ "Confidence" SG_ 1817 VCSEC_rssi0WLEntry 0;
BA_ "Confidence" SG_ 1817 VCSEC_endpointLayout 0;
BA_ "Confidence" SG_ 1817 VCSEC_rssi1WLEntry 0;
BA_ "Confidence" SG_ 1817 VCSEC_rssi2WLEntry 0;
BA_ "Confidence" SG_ 1817 VCSEC_walkUpUnlockState 0;
BA_ "Confidence" SG_ 1817 VCSEC_algoHighThreshLeft 0;
BA_ "Confidence" SG_ 1817 VCSEC_algoHighThreshRight 0;
BA_ "Confidence" SG_ 1817 VCSEC_algoHighThreshCenter 0;
BA_ "Confidence" SG_ 1817 VCSEC_pollingReason 0;
BA_ "Confidence" SG_ 1817 VCSEC_numberOfPubKeysOnWhitelist 0;
BA_ "Confidence" SG_ 1817 VCSEC_thermalDetectState 0;
BA_ "Confidence" SG_ 1817 VCSEC_chargeHandleMitigationActi 0;
BA_ "SystemSignalLongSymbol" SG_ 1817 VCSEC_chargeHandleMitigationActi "VCSEC_chargeHandleMitigationActive";
BA_ "Confidence" SG_ 1817 VCSEC_smartTrunkMitigatedKeyCoun 0;
BA_ "SystemSignalLongSymbol" SG_ 1817 VCSEC_smartTrunkMitigatedKeyCoun "VCSEC_smartTrunkMitigatedKeyCount";
BA_ "Confidence" SG_ 1817 VCSEC_UWB3WLEntry 0;
BA_ "Confidence" SG_ 1817 VCSEC_device0Offset 0;
BA_ "Confidence" SG_ 1817 VCSEC_device1Offset 0;
BA_ "Confidence" SG_ 1817 VCSEC_device2Offset 0;
BA_ "Confidence" SG_ 1817 VCSEC_connection0BondingState 0;
BA_ "Confidence" SG_ 1817 VCSEC_connection1BondingState 0;
BA_ "Confidence" SG_ 1817 VCSEC_connection2BondingState 0;
BA_ "Confidence" SG_ 1817 VCSEC_connection0UWBAvailability 0;
BA_ "Confidence" SG_ 1817 VCSEC_connection1UWBAvailability 0;
BA_ "Confidence" SG_ 1817 VCSEC_connection2UWBAvailability 0;
BA_ "Confidence" SG_ 1817 VCSEC_NISessionStateCenter0 0;
BA_ "Confidence" SG_ 1817 VCSEC_NISessionStateLeft0 0;
BA_ "Confidence" SG_ 1817 VCSEC_NISessionStateRight0 0;
BA_ "Confidence" SG_ 1817 VCSEC_NISessionStateRearLeft0 0;
BA_ "Confidence" SG_ 1817 VCSEC_NISessionStateRearRight0 0;
BA_ "Confidence" SG_ 1817 VCSEC_NISessionStateRear0 0;
BA_ "Confidence" SG_ 1817 VCSEC_NISessionStateCenter1 0;
BA_ "Confidence" SG_ 1817 VCSEC_NISessionStateLeft1 0;
BA_ "Confidence" SG_ 1817 VCSEC_NISessionStateRight1 0;
BA_ "Confidence" SG_ 1817 VCSEC_NISessionStateRearLeft1 0;
BA_ "Confidence" SG_ 1817 VCSEC_NISessionStateRearRight1 0;
BA_ "Confidence" SG_ 1817 VCSEC_NISessionStateRear1 0;
BA_ "Confidence" SG_ 1817 VCSEC_NISessionStateCenter2 0;
BA_ "Confidence" SG_ 1817 VCSEC_NISessionStateLeft2 0;
BA_ "Confidence" SG_ 1817 VCSEC_NISessionStateRight2 0;
BA_ "Confidence" SG_ 1817 VCSEC_NISessionStateRearLeft2 0;
BA_ "Confidence" SG_ 1817 VCSEC_NISessionStateRearRight2 0;
BA_ "Confidence" SG_ 1817 VCSEC_NISessionStateRear2 0;
BA_ "Confidence" SG_ 1817 VCSEC_NISessionStateLeft3 0;
BA_ "Confidence" SG_ 1817 VCSEC_NISessionStateRight3 0;
BA_ "Confidence" SG_ 1817 VCSEC_NISessionStateRearRight3 0;
BA_ "Confidence" SG_ 1817 VCSEC_NISessionStateRearLeft3 0;
BA_ "Confidence" SG_ 1817 VCSEC_NISessionStateCenter3 0;
BA_ "Confidence" SG_ 1824 VCSEC_ECUConfigCRC32 0;
BA_ "Confidence" SG_ 1824 VCSEC_autoWriteConfig 0;
BA_ "Confidence" SG_ 1824 VCSEC_requestForConfig 0;
BA_ "Confidence" SG_ 793 VCSEC_infoIndex 1;
BA_ "Confidence" SG_ 793 VCSEC_infoBuildType 0;
BA_ "Confidence" SG_ 793 VCSEC_infoBuildConfigId 0;
BA_ "Confidence" SG_ 793 VCSEC_infoHardwareId 0;
BA_ "Confidence" SG_ 793 VCSEC_infoComponentId 0;
BA_ "Confidence" SG_ 793 VCSEC_infoPcbaId 0;
BA_ "Confidence" SG_ 793 VCSEC_infoAssemblyId 0;
BA_ "GenSigSNA" SG_ 793 VCSEC_infoAssemblyId "255";
BA_ "Confidence" SG_ 793 VCSEC_infoUsageId 0;
BA_ "Confidence" SG_ 793 VCSEC_infoSubUsageId 0;
BA_ "Confidence" SG_ 793 VCSEC_infoAppCrc 0;
BA_ "Confidence" SG_ 793 VCSEC_infoSubcomponent1 0;
BA_ "Confidence" SG_ 793 VCSEC_infoAppGitHash 0;
BA_ "Confidence" SG_ 793 VCSEC_infoBootGitHash 0;
BA_ "Confidence" SG_ 793 VCSEC_infoPlatformType 0;
BA_ "Confidence" SG_ 793 VCSEC_infoBootUdsProtoVersion 0;
BA_ "Confidence" SG_ 793 VCSEC_infoBootCrc 0;
BA_ "Confidence" SG_ 793 VCSEC_infoSubcomponent2 0;
BA_ "Confidence" SG_ 793 VCSEC_infoSubcomponent3 0;
BA_ "Confidence" SG_ 793 VCSEC_infoSubcomponent4 0;
BA_ "Confidence" SG_ 505 VCSEC_chargePortRequest 0;
BA_ "GenSigSNA" SG_ 505 VCSEC_chargePortRequest "3";
BA_ "Confidence" SG_ 505 VCSEC_presentHandles 0;
BA_ "Confidence" SG_ 505 VCSEC_frontLeftClosureRequest 0;
BA_ "Confidence" SG_ 505 VCSEC_frontRightClosureRequest 0;
BA_ "Confidence" SG_ 505 VCSEC_rearLeftClosureRequest 0;
BA_ "Confidence" SG_ 505 VCSEC_rearRightClosureRequest 0;
BA_ "Confidence" SG_ 505 VCSEC_rearTrunkClosureRequest 0;
BA_ "Confidence" SG_ 505 VCSEC_frontLeftRequestReason 0;
BA_ "Confidence" SG_ 505 VCSEC_frontRightRequestReason 0;
BA_ "Confidence" SG_ 505 VCSEC_rearLeftRequestReason 0;
BA_ "Confidence" SG_ 505 VCSEC_rearRightRequestReason 0;
BA_ "Confidence" SG_ 505 VCSEC_rearTrunkRequestReason 0;
BA_ "Confidence" SG_ 505 VCSEC_rdMapDumpRequested 0;
BA_ "Confidence" SG_ 505 VCSEC_driveAttemptedWithoutAuth 0;
BA_ "Confidence" SG_ 505 VCSEC_closeAllStatus 0;
BA_ "Confidence" SG_ 505 VCSEC_snapshotRequested 0;
BA_ "Confidence" SG_ 505 VCSEC_chargeportRequestReason 0;
BA_ "Confidence" SG_ 505 VCSEC_frontTrunkClosureRequest 0;
BA_ "Confidence" SG_ 505 VCSEC_frontTrunkRequestReason 0;
BA_ "Confidence" SG_ 281 VCSEC_activeImmobilizerAuthLevel 0;
BA_ "Confidence" SG_ 281 VCSEC_smartTrunkLightRequest 0;
BA_ "Confidence" SG_ 281 VCSEC_smartTrunkSoundRequest 0;
BA_ "Confidence" SG_ 281 VCSEC_hvacRunScreenProtectOnly 0;
BA_ "Confidence" SG_ 281 VCSEC_chargeHandleRequestModel 0;
BA_ "Confidence" SG_ 281 VCSEC_recoveryModeRequested 0;
BA_ "Confidence" SG_ 281 VCSEC_infotainmentResetRequested 0;
BA_ "Confidence" SG_ 281 VCSEC_mobileToAPRequest 0;
BA_ "Confidence" SG_ 281 VCSEC_riderKeyPresent 0;
BA_ "Confidence" SG_ 1850 VC_LVBMS_brickMeasurementsMultip 1;
BA_ "SystemSignalLongSymbol" SG_ 1850 VC_LVBMS_brickMeasurementsMultip "VC_LVBMS_brickMeasurementsMultiplexer";
BA_ "Confidence" SG_ 1850 VC_LVBMS_brickVoltage1 0;
BA_ "GenSigSNA" SG_ 1850 VC_LVBMS_brickVoltage1 "8191";
BA_ "Confidence" SG_ 1850 VC_LVBMS_brickVoltage2 0;
BA_ "GenSigSNA" SG_ 1850 VC_LVBMS_brickVoltage2 "8191";
BA_ "Confidence" SG_ 1850 VC_LVBMS_brickVoltage3 0;
BA_ "GenSigSNA" SG_ 1850 VC_LVBMS_brickVoltage3 "8191";
BA_ "Confidence" SG_ 1850 VC_LVBMS_brickVoltage4 0;
BA_ "GenSigSNA" SG_ 1850 VC_LVBMS_brickVoltage4 "8191";
BA_ "Confidence" SG_ 1850 VC_LVBMS_brickBalancingAh1 0;
BA_ "GenSigSNA" SG_ 1850 VC_LVBMS_brickBalancingAh1 "16777215";
BA_ "Confidence" SG_ 1850 VC_LVBMS_brickBalancingAh2 0;
BA_ "GenSigSNA" SG_ 1850 VC_LVBMS_brickBalancingAh2 "16777215";
BA_ "Confidence" SG_ 1850 VC_LVBMS_brickBalancingState1 0;
BA_ "Confidence" SG_ 1850 VC_LVBMS_brickBalancingState2 0;
BA_ "Confidence" SG_ 1850 VC_LVBMS_brickBalancingAh3 0;
BA_ "GenSigSNA" SG_ 1850 VC_LVBMS_brickBalancingAh3 "16777215";
BA_ "Confidence" SG_ 1850 VC_LVBMS_brickBalancingAh4 0;
BA_ "GenSigSNA" SG_ 1850 VC_LVBMS_brickBalancingAh4 "16777215";
BA_ "Confidence" SG_ 1850 VC_LVBMS_brickBalancingState3 0;
BA_ "Confidence" SG_ 1850 VC_LVBMS_brickBalancingState4 0;
BA_ "Confidence" SG_ 1655 VC_lvbmsStatusHighIndex 1;
BA_ "Confidence" SG_ 1655 VC_LVBMS_packCurrent 0;
BA_ "GenSigSNA" SG_ 1655 VC_LVBMS_packCurrent "4194303";
BA_ "Confidence" SG_ 1655 VC_LVBMS_packVoltage 0;
BA_ "GenSigSNA" SG_ 1655 VC_LVBMS_packVoltage "65535";
BA_ "Confidence" SG_ 1655 VC_LVBMS_packTemperature 0;
BA_ "GenSigSNA" SG_ 1655 VC_LVBMS_packTemperature "511";
BA_ "Confidence" SG_ 1655 VC_LVBMS_MOSTemperature 0;
BA_ "GenSigSNA" SG_ 1655 VC_LVBMS_MOSTemperature "4095";
BA_ "Confidence" SG_ 1655 VC_LVBMS_sumCellVoltage 0;
BA_ "GenSigSNA" SG_ 1655 VC_LVBMS_sumCellVoltage "65535";
BA_ "Confidence" SG_ 1655 VC_LVBMS_maxBrickVoltage 0;
BA_ "GenSigSNA" SG_ 1655 VC_LVBMS_maxBrickVoltage "8191";
BA_ "Confidence" SG_ 1655 VC_LVBMS_maxBrickVoltageIndex 0;
BA_ "GenSigSNA" SG_ 1655 VC_LVBMS_maxBrickVoltageIndex "255";
BA_ "Confidence" SG_ 1655 VC_totalLVLoadCurrent 0;
BA_ "Confidence" SG_ 1655 VC_LVPackChargeCurrentLimit 0;
BA_ "Confidence" SG_ 1655 VC_LVPackCurrent 0;
BA_ "Confidence" SG_ 1655 VC_LVBMS_estimatedPackOcv 0;
BA_ "Confidence" SG_ 1655 VC_LVBMS_voltageTarget 0;
BA_ "GenSigSNA" SG_ 1655 VC_LVBMS_voltageTarget "65535";
BA_ "Confidence" SG_ 1655 VC_LVBMS_currentTarget 0;
BA_ "GenSigSNA" SG_ 1655 VC_LVBMS_currentTarget "262143";
BA_ "Confidence" SG_ 1655 VC_LVBMS_maxAllowedChargeCurrent 0;
BA_ "GenSigSNA" SG_ 1655 VC_LVBMS_maxAllowedChargeCurrent "8191";
BA_ "Confidence" SG_ 1655 VC_LVBMS_maxAllowedDischargeCurr 0;
BA_ "GenSigSNA" SG_ 1655 VC_LVBMS_maxAllowedDischargeCurr "8191";
BA_ "SystemSignalLongSymbol" SG_ 1655 VC_LVBMS_maxAllowedDischargeCurr "VC_LVBMS_maxAllowedDischargeCurrent";
BA_ "Confidence" SG_ 1655 VC_LVBMS_MOSCommand 0;
BA_ "Confidence" SG_ 1655 VC_LVBMS_ClearErrorCntrCommand 0;
BA_ "Confidence" SG_ 1655 VC_LVBMS_ClearHistoricFaultComma 0;
BA_ "SystemSignalLongSymbol" SG_ 1655 VC_LVBMS_ClearHistoricFaultComma "VC_LVBMS_ClearHistoricFaultCommand";
BA_ "Confidence" SG_ 1655 VC_LVBMS_ResetLVBMSCommand 0;
BA_ "Confidence" SG_ 1655 VC_LVBMS_EnterHibernationCommand 0;
BA_ "Confidence" SG_ 1655 VC_LVBMS_ECPAState 0;
BA_ "GenSigSNA" SG_ 1655 VC_LVBMS_ECPAState "3";
BA_ "Confidence" SG_ 1655 VC_LVBMS_MOSState 0;
BA_ "GenSigSNA" SG_ 1655 VC_LVBMS_MOSState "3";
BA_ "Confidence" SG_ 1655 VC_LVBMS_VehicleState 0;
BA_ "Confidence" SG_ 1655 VC_LVBMS_LINWakeDisabled 0;
BA_ "Confidence" SG_ 1655 VC_LVBMS_chargeType 0;
BA_ "GenSigSNA" SG_ 1655 VC_LVBMS_chargeType "4";
BA_ "Confidence" SG_ 1655 VC_LVBMS_cellAndArcProtEnabled 0;
BA_ "Confidence" SG_ 1655 VC_LVBMS_avgBrickVoltage 0;
BA_ "GenSigSNA" SG_ 1655 VC_LVBMS_avgBrickVoltage "8191";
BA_ "Confidence" SG_ 1655 VC_LVBMS_minBrickVoltage 0;
BA_ "GenSigSNA" SG_ 1655 VC_LVBMS_minBrickVoltage "8191";
BA_ "Confidence" SG_ 1655 VC_LVBMS_minBrickVoltageIndex 0;
BA_ "GenSigSNA" SG_ 1655 VC_LVBMS_minBrickVoltageIndex "255";
BA_ "Confidence" SG_ 1816 VC_lvbmsStatusLowIndex 1;
BA_ "Confidence" SG_ 1816 VC_LVBMS_SOC 0;
BA_ "GenSigSNA" SG_ 1816 VC_LVBMS_SOC "1023";
BA_ "Confidence" SG_ 1816 VC_LVBMS_SOE 0;
BA_ "GenSigSNA" SG_ 1816 VC_LVBMS_SOE "127";
BA_ "Confidence" SG_ 1816 VC_LVBMS_SOH 0;
BA_ "GenSigSNA" SG_ 1816 VC_LVBMS_SOH "127";
BA_ "Confidence" SG_ 1816 VC_LVBMS_CellOVLevel1 0;
BA_ "Confidence" SG_ 1816 VC_LVBMS_CellOVLevel2 0;
BA_ "Confidence" SG_ 1816 VC_LVBMS_CellOVLevel3 0;
BA_ "Confidence" SG_ 1816 VC_LVBMS_CellUVLevel1 0;
BA_ "Confidence" SG_ 1816 VC_LVBMS_CellUVLevel2 0;
BA_ "Confidence" SG_ 1816 VC_LVBMS_ModuleOTLevel1 0;
BA_ "Confidence" SG_ 1816 VC_LVBMS_PackOVLevel1 0;
BA_ "Confidence" SG_ 1816 VC_LVBMS_PackOVLevel2 0;
BA_ "Confidence" SG_ 1816 VC_LVBMS_DischrgOCLevel1 0;
BA_ "Confidence" SG_ 1816 VC_LVBMS_DischrgOCLevel2 0;
BA_ "Confidence" SG_ 1816 VC_LVBMS_ChrgOCLevel1 0;
BA_ "Confidence" SG_ 1816 VC_LVBMS_ChrgOCLevel2 0;
BA_ "Confidence" SG_ 1816 VC_LVBMS_MOSFETOTLevel1 0;
BA_ "Confidence" SG_ 1816 VC_LVBMS_KBValueLostFault 0;
BA_ "Confidence" SG_ 1816 VC_LVBMS_BalanceCircuitFault 0;
BA_ "Confidence" SG_ 1816 VC_LVBMS_MOSStateFault 0;
BA_ "Confidence" SG_ 1816 VC_LVBMS_NTCTempDiffWarnLevel1 0;
BA_ "Confidence" SG_ 1816 VC_LVBMS_DeepDischargeFlag 0;
BA_ "Confidence" SG_ 1816 VC_LVBMS_SamplingError 0;
BA_ "Confidence" SG_ 1816 VC_LVBMS_MosfetStuckCloseError 0;
BA_ "Confidence" SG_ 1816 VC_LVBMS_MosfetStuckOpenError 0;
BA_ "Confidence" SG_ 1816 VC_LVBMS_AvgSleepCurrent 0;
BA_ "GenSigSNA" SG_ 1816 VC_LVBMS_AvgSleepCurrent "65535";
BA_ "Confidence" SG_ 1816 VC_LVBMS_TimeSlept 0;
BA_ "GenSigSNA" SG_ 1816 VC_LVBMS_TimeSlept "16777215";
BA_ "Confidence" SG_ 1816 VC_LVBMS_SOP 0;
BA_ "GenSigSNA" SG_ 1816 VC_LVBMS_SOP "255";
BA_ "Confidence" SG_ 1816 VC_LVBMS_AhCharged 0;
BA_ "GenSigSNA" SG_ 1816 VC_LVBMS_AhCharged "4294967295";
BA_ "Confidence" SG_ 1816 VC_LVBMS_MinSleepCurrent 0;
BA_ "GenSigSNA" SG_ 1816 VC_LVBMS_MinSleepCurrent "65535";
BA_ "Confidence" SG_ 1816 VC_LVBMS_AhDischarged 0;
BA_ "GenSigSNA" SG_ 1816 VC_LVBMS_AhDischarged "4294967295";
BA_ "Confidence" SG_ 1816 VC_LVBMS_MaxSleepCurrent 0;
BA_ "GenSigSNA" SG_ 1816 VC_LVBMS_MaxSleepCurrent "65535";
BA_ "Confidence" SG_ 1816 VC_LVBMS_sumCellVoltageFiltered 0;
BA_ "GenSigSNA" SG_ 1816 VC_LVBMS_sumCellVoltageFiltered "65535";
BA_ "Confidence" SG_ 1816 VC_LVBMS_maxCellSOC 0;
BA_ "GenSigSNA" SG_ 1816 VC_LVBMS_maxCellSOC "1023";
BA_ "Confidence" SG_ 1816 VC_LVBMS_minCellSOC 0;
BA_ "GenSigSNA" SG_ 1816 VC_LVBMS_minCellSOC "1023";
BA_ "Confidence" SG_ 1816 VC_LVBMS_staticSOCCorrection 0;
BA_ "Confidence" SG_ 1816 VC_LVBMS_dynamicSOCCorrection 0;
BA_ "Confidence" SG_ 1816 VC_LVBMS_usableEnergyAvailable 0;
BA_ "GenSigSNA" SG_ 1816 VC_LVBMS_usableEnergyAvailable "4095";
BA_ "Confidence" SG_ 1816 VC_LVBMS_brakeTelltale 0;
BA_ "Confidence" SG_ 1089 VC_pcsInterfaceMuxIndex 1;
BA_ "Confidence" SG_ 1089 VC_pcsInterfaceCounter 0;
BA_ "Confidence" SG_ 1089 VC_pcsInterfaceChecksum 0;
BA_ "Confidence" SG_ 1089 VC_pcsLVVoltageTarget 0;
BA_ "Confidence" SG_ 1089 VC_pcsLVMinVoltageLimit 0;
BA_ "Confidence" SG_ 1089 VC_pcsLVMaxVoltageLimit 0;
BA_ "Confidence" SG_ 1089 VC_goodForPCSPowerCycle 0;
BA_ "Confidence" SG_ 1089 VC_LVBatteryCannotSupportVehicle 0;
BA_ "Confidence" SG_ 1089 VC_pcsResistanceFiltered 0;
BA_ "GenSigSNA" SG_ 1089 VC_pcsResistanceFiltered "65535";
BA_ "Confidence" SG_ 1089 VC_pcsLVMaxDchrgCurrentLimit 0;
BA_ "Confidence" SG_ 1089 VC_defaultPcsLVVoltageTarget 0;
BA_ "Confidence" SG_ 1089 VC_lvHwProtSelfTestActive 0;
BA_ "Confidence" SG_ 1089 VC_lvBatteryDischargeRequest 0;
BA_ "Confidence" SG_ 1091 VC_pcsManagementChecksum 0;
BA_ "Confidence" SG_ 1091 VC_pcsManagementCounter 0;
BA_ "Confidence" SG_ 1091 VC_pcsManagementMuxIndex 1;
BA_ "Confidence" SG_ 1091 VC_dcdcLVVoltageTargetMax 0;
BA_ "Confidence" SG_ 1091 VC_dcdcLVVoltageTargetMin 0;
BA_ "Confidence" SG_ 1091 VC_dcdcLVInputPowerLimit 0;
VAL_ 537 VCSEC_TPMSDataIndex 5 "AutonomyHealth" 4 "RCP" 3 "Sensor3" 2 "Sensor2" 1 "Sensor1" 0 "Sensor0" ;
VAL_ 537 VCSEC_TPMSPressure0 511 "SNA" 510 "OVER_RANGE" ;
VAL_ 537 VCSEC_TPMSTemperature0 255 "SNA" ;
VAL_ 537 VCSEC_TPMSBatVoltage0 255 "SNA" ;
VAL_ 537 VCSEC_TPMSLocation0 4 "LOCATION_UNKNOWN" 3 "LOCATION_RR" 2 "LOCATION_RL" 1 "LOCATION_FR" 0 "LOCATION_FL" ;
VAL_ 537 VCSEC_TPMSTemperatureCompensated 511 "SNA" 510 "OVER_RANGE" ;
VAL_ 537 VCSEC_TPMSPressure1 511 "SNA" 510 "OVER_RANGE" ;
VAL_ 537 VCSEC_TPMSTemperature1 255 "SNA" ;
VAL_ 537 VCSEC_TPMSBatVoltage1 255 "SNA" ;
VAL_ 537 VCSEC_TPMSLocation1 4 "LOCATION_UNKNOWN" 3 "LOCATION_RR" 2 "LOCATION_RL" 1 "LOCATION_FR" 0 "LOCATION_FL" ;
VAL_ 537 VCSEC_TPMSTemperatureCompen_0001 511 "SNA" 510 "OVER_RANGE" ;
VAL_ 537 VCSEC_TPMSPressure2 511 "SNA" 510 "OVER_RANGE" ;
VAL_ 537 VCSEC_TPMSTemperature2 255 "SNA" ;
VAL_ 537 VCSEC_TPMSBatVoltage2 255 "SNA" ;
VAL_ 537 VCSEC_TPMSLocation2 4 "LOCATION_UNKNOWN" 3 "LOCATION_RR" 2 "LOCATION_RL" 1 "LOCATION_FR" 0 "LOCATION_FL" ;
VAL_ 537 VCSEC_TPMSTemperatureCompen_0002 511 "SNA" 510 "OVER_RANGE" ;
VAL_ 537 VCSEC_TPMSPressure3 511 "SNA" 510 "OVER_RANGE" ;
VAL_ 537 VCSEC_TPMSTemperature3 255 "SNA" ;
VAL_ 537 VCSEC_TPMSBatVoltage3 255 "SNA" ;
VAL_ 537 VCSEC_TPMSLocation3 4 "LOCATION_UNKNOWN" 3 "LOCATION_RR" 2 "LOCATION_RL" 1 "LOCATION_FR" 0 "LOCATION_FL" ;
VAL_ 537 VCSEC_TPMSTemperatureCompen_0003 511 "SNA" 510 "OVER_RANGE" ;
VAL_ 537 VCSEC_TPMSRecommendedColdPressur 255 "SNA" 254 "OVER_RANGE" ;
VAL_ 537 VCSEC_TPMSRecommendedColdPr_0001 255 "SNA" 254 "OVER_RANGE" ;
VAL_ 537 VCSEC_TPMSFeature0 6 "FEATURE_0_BLOCKED" 5 "FEATURE_0_ACTIVE" 4 "FEATURE_0_READY" 3 "FEATURE_0_WAIT_FOR_STATIONARY" 2 "FEATURE_0_UNAVAILABLE_2" 1 "FEATURE_0_UNAVAILABLE_1" 0 "FEATURE_0_NOT_SUPPORTED" ;
VAL_ 537 VCSEC_TPMSFeature1 5 "FEATURE_1_CLOSE" 4 "FEATURE_1_MEDIUM" 3 "FEATURE_1_FAR_AWAY" 2 "FEATURE_1_INCORRECT" 1 "FEATURE_1_REACHED" 0 "FEATURE_1_NONE" ;
VAL_ 537 VCSEC_TPMSAutonomyStatus 2 "TPMS_AUTONOMY_STATUS_RESET" 1 "TPMS_AUTONOMY_STATUS_MIA" 0 "TPMS_AUTONOMY_STATUS_NORMAL" ;
VAL_ 537 VCSEC_TPMSLastKnownPressureFL 255 "SNA" 254 "OVER_RANGE" ;
VAL_ 537 VCSEC_TPMSLastKnownPressureFR 255 "SNA" 254 "OVER_RANGE" ;
VAL_ 537 VCSEC_TPMSLastKnownPressureRL 255 "SNA" 254 "OVER_RANGE" ;
VAL_ 537 VCSEC_TPMSLastKnownPressureRR 255 "SNA" 254 "OVER_RANGE" ;
VAL_ 602 VCSEC_TPMSDisplayPressureFL 255 "SNA" 254 "OVER_RANGE" ;
VAL_ 602 VCSEC_TPMSDisplayPressureFR 255 "SNA" 254 "OVER_RANGE" ;
VAL_ 602 VCSEC_TPMSDisplayPressureRL 255 "SNA" 254 "OVER_RANGE" ;
VAL_ 602 VCSEC_TPMSDisplayPressureRR 255 "SNA" 254 "OVER_RANGE" ;
VAL_ 602 VCSEC_TPMSTellTale 2 "TPMS_TELLTALE_FLASHING" 1 "TPMS_TELLTALE_SOLID" 0 "TPMS_TELLTALE_OFF" ;
VAL_ 602 VCSEC_TPMSDisplaySoftWarningIndi 1 "TPMS_PRESSUREWARNING_INDICATED" 0 "TPMS_PRESSUREWARNING_NOT_INDICATED" ;
VAL_ 602 VCSEC_TPMSDisplaySoftWarnin_0001 1 "TPMS_PRESSUREWARNING_INDICATED" 0 "TPMS_PRESSUREWARNING_NOT_INDICATED" ;
VAL_ 602 VCSEC_TPMSDisplaySoftWarnin_0002 1 "TPMS_PRESSUREWARNING_INDICATED" 0 "TPMS_PRESSUREWARNING_NOT_INDICATED" ;
VAL_ 602 VCSEC_TPMSDisplaySoftWarnin_0003 1 "TPMS_PRESSUREWARNING_INDICATED" 0 "TPMS_PRESSUREWARNING_NOT_INDICATED" ;
VAL_ 602 VCSEC_TPMSDisplayHardWarningIndi 1 "TPMS_PRESSUREWARNING_INDICATED" 0 "TPMS_PRESSUREWARNING_NOT_INDICATED" ;
VAL_ 602 VCSEC_TPMSDisplayHardWarnin_0001 1 "TPMS_PRESSUREWARNING_INDICATED" 0 "TPMS_PRESSUREWARNING_NOT_INDICATED" ;
VAL_ 602 VCSEC_TPMSDisplayHardWarnin_0002 1 "TPMS_PRESSUREWARNING_INDICATED" 0 "TPMS_PRESSUREWARNING_NOT_INDICATED" ;
VAL_ 602 VCSEC_TPMSDisplayHardWarnin_0003 1 "TPMS_PRESSUREWARNING_INDICATED" 0 "TPMS_PRESSUREWARNING_NOT_INDICATED" ;
VAL_ 570 VCSEC_TPMSStatusIndex 39 "TireMileageContinued" 38 "TireMileage" 37 "SensorFilteredVoltageInfo" 36 "SensorTemperatureCompensatedVoltageInfo" 35 "LastLocationInfo" 34 "SensorHashInfo2" 33 "SensorHashInfo1" 32 "SensorConfiguration" 31 "ResetCountsContinuedSensor3" 30 "ResetCountsSensor3" 29 "ResetCountsContinuedSensor2" 28 "ResetCountsSensor2" 27 "ResetCountsContinuedSensor1" 26 "ResetCountsSensor1" 25 "ResetCountsContinuedSensor0" 24 "ResetCountsSensor0" 23 "SleepStatsSensor3" 22 "SleepStatsSensor2" 21 "SleepStatsSensor1" 20 "SleepStatsSensor0" 19 "CPUTimeSensor3" 18 "CPUTimeSensor2" 17 "CPUTimeSensor1" 16 "CPUTimeSensor0" 15 "CRCSensor3" 14 "CRCSensor2" 13 "CRCSensor1" 12 "CRCSensor0" 11 "ConnMetricsContinuedSensor3" 10 "ConnMetricsSensor3" 9 "ConnMetricsContinuedSensor2" 8 "ConnMetricsSensor2" 7 "ConnMetricsContinuedSensor1" 6 "ConnMetricsSensor1" 5 "ConnMetricsContinuedSensor0" 4 "ConnMetricsSensor0" 3 "MACAddressSensor3" 2 "MACAddressSensor2" 1 "MACAddressSensor1" 0 "MACAddressSensor0" ;
VAL_ 570 VCSEC_TPMSSystemState 1 "TPMS_SYSTEM_STATE_ACTIVE" 0 "TPMS_SYSTEM_STATE_IDLE" ;
VAL_ 570 VCSEC_BLEUnsuccessfulConnEventRa 1023 "SNA" ;
VAL_ 570 VCSEC_BLEUnsuccessfulConnEv_0001 1023 "SNA" ;
VAL_ 570 VCSEC_BLEUnsuccessfulConnEv_0002 1023 "SNA" ;
VAL_ 570 VCSEC_BLEUnsuccessfulConnEv_0003 1023 "SNA" ;
VAL_ 570 VCSEC_TPMSSensorTIAppCRC0 0 "TPMS_CRC_SNA" ;
VAL_ 570 VCSEC_TPMSSensorMLXAppCRC0 0 "TPMS_CRC_SNA" ;
VAL_ 570 VCSEC_TPMSSensorTIAppCRC1 0 "TPMS_CRC_SNA" ;
VAL_ 570 VCSEC_TPMSSensorMLXAppCRC1 0 "TPMS_CRC_SNA" ;
VAL_ 570 VCSEC_TPMSSensorTIAppCRC2 0 "TPMS_CRC_SNA" ;
VAL_ 570 VCSEC_TPMSSensorMLXAppCRC2 0 "TPMS_CRC_SNA" ;
VAL_ 570 VCSEC_TPMSSensorTIAppCRC3 0 "TPMS_CRC_SNA" ;
VAL_ 570 VCSEC_TPMSSensorMLXAppCRC3 0 "TPMS_CRC_SNA" ;
VAL_ 570 VCSEC_TPMSGenealogySensorState0 7 "SENSOR_STATE_DONE" 6 "SENSOR_STATE_WAIT_FOR_CAPABILITIES_RESPONSE" 5 "SENSOR_STATE_SEND_CAPABILITIES_REQUEST" 4 "SENSOR_STATE_WAIT_FOR_GENEALOGY_RESPONSE" 3 "SENSOR_STATE_SEND_GENEALOGY_REQUEST" 2 "SENSOR_STATE_WAIT_FOR_CODE_DESCRIPTOR_RESPONSE" 1 "SENSOR_STATE_SEND_CODE_DESCRIPTOR_REQUEST" 0 "SENSOR_STATE_WAIT_FOR_CONNECTION" ;
VAL_ 570 VCSEC_TPMSSensorType0 6 "SENSOR_TYPE_V5" 5 "SENSOR_TYPE_V4" 4 "SENSOR_TYPE_V3" 3 "SENSOR_TYPE_V2" 2 "SENSOR_TYPE_V1" 1 "SENSOR_TYPE_UNKNOWN" 0 "SENSOR_TYPE_NOT_IDENTIFIED" ;
VAL_ 570 VCSEC_TPMSGenealogySensorState1 7 "SENSOR_STATE_DONE" 6 "SENSOR_STATE_WAIT_FOR_CAPABILITIES_RESPONSE" 5 "SENSOR_STATE_SEND_CAPABILITIES_REQUEST" 4 "SENSOR_STATE_WAIT_FOR_GENEALOGY_RESPONSE" 3 "SENSOR_STATE_SEND_GENEALOGY_REQUEST" 2 "SENSOR_STATE_WAIT_FOR_CODE_DESCRIPTOR_RESPONSE" 1 "SENSOR_STATE_SEND_CODE_DESCRIPTOR_REQUEST" 0 "SENSOR_STATE_WAIT_FOR_CONNECTION" ;
VAL_ 570 VCSEC_TPMSSensorType1 6 "SENSOR_TYPE_V5" 5 "SENSOR_TYPE_V4" 4 "SENSOR_TYPE_V3" 3 "SENSOR_TYPE_V2" 2 "SENSOR_TYPE_V1" 1 "SENSOR_TYPE_UNKNOWN" 0 "SENSOR_TYPE_NOT_IDENTIFIED" ;
VAL_ 570 VCSEC_TPMSGenealogySensorState2 7 "SENSOR_STATE_DONE" 6 "SENSOR_STATE_WAIT_FOR_CAPABILITIES_RESPONSE" 5 "SENSOR_STATE_SEND_CAPABILITIES_REQUEST" 4 "SENSOR_STATE_WAIT_FOR_GENEALOGY_RESPONSE" 3 "SENSOR_STATE_SEND_GENEALOGY_REQUEST" 2 "SENSOR_STATE_WAIT_FOR_CODE_DESCRIPTOR_RESPONSE" 1 "SENSOR_STATE_SEND_CODE_DESCRIPTOR_REQUEST" 0 "SENSOR_STATE_WAIT_FOR_CONNECTION" ;
VAL_ 570 VCSEC_TPMSSensorType2 6 "SENSOR_TYPE_V5" 5 "SENSOR_TYPE_V4" 4 "SENSOR_TYPE_V3" 3 "SENSOR_TYPE_V2" 2 "SENSOR_TYPE_V1" 1 "SENSOR_TYPE_UNKNOWN" 0 "SENSOR_TYPE_NOT_IDENTIFIED" ;
VAL_ 570 VCSEC_TPMSGenealogySensorState3 7 "SENSOR_STATE_DONE" 6 "SENSOR_STATE_WAIT_FOR_CAPABILITIES_RESPONSE" 5 "SENSOR_STATE_SEND_CAPABILITIES_REQUEST" 4 "SENSOR_STATE_WAIT_FOR_GENEALOGY_RESPONSE" 3 "SENSOR_STATE_SEND_GENEALOGY_REQUEST" 2 "SENSOR_STATE_WAIT_FOR_CODE_DESCRIPTOR_RESPONSE" 1 "SENSOR_STATE_SEND_CODE_DESCRIPTOR_REQUEST" 0 "SENSOR_STATE_WAIT_FOR_CONNECTION" ;
VAL_ 570 VCSEC_TPMSSensorType3 6 "SENSOR_TYPE_V5" 5 "SENSOR_TYPE_V4" 4 "SENSOR_TYPE_V3" 3 "SENSOR_TYPE_V2" 2 "SENSOR_TYPE_V1" 1 "SENSOR_TYPE_UNKNOWN" 0 "SENSOR_TYPE_NOT_IDENTIFIED" ;
VAL_ 570 VCSEC_TPMSLastLocationSensor0 4 "LOCATION_UNKNOWN" 3 "LOCATION_RR" 2 "LOCATION_RL" 1 "LOCATION_FR" 0 "LOCATION_FL" ;
VAL_ 570 VCSEC_TPMSLastLocationSensor1 4 "LOCATION_UNKNOWN" 3 "LOCATION_RR" 2 "LOCATION_RL" 1 "LOCATION_FR" 0 "LOCATION_FL" ;
VAL_ 570 VCSEC_TPMSLastLocationSensor2 4 "LOCATION_UNKNOWN" 3 "LOCATION_RR" 2 "LOCATION_RL" 1 "LOCATION_FR" 0 "LOCATION_FL" ;
VAL_ 570 VCSEC_TPMSLastLocationSensor3 4 "LOCATION_UNKNOWN" 3 "LOCATION_RR" 2 "LOCATION_RL" 1 "LOCATION_FR" 0 "LOCATION_FL" ;
VAL_ 570 VCSEC_TPMSTemperatureCompensated 255 "SNA" ;
VAL_ 570 VCSEC_TPMSTemperatureCompen_0001 255 "SNA" ;
VAL_ 570 VCSEC_TPMSTemperatureCompen_0002 255 "SNA" ;
VAL_ 570 VCSEC_TPMSTemperatureCompen_0003 255 "SNA" ;
VAL_ 570 VCSEC_TPMSFilteredBatVoltage0 255 "SNA" ;
VAL_ 570 VCSEC_TPMSFilteredBatVoltage2 255 "SNA" ;
VAL_ 570 VCSEC_TPMSFilteredBatVoltage1 255 "SNA" ;
VAL_ 570 VCSEC_TPMSFilteredBatVoltage3 255 "SNA" ;
VAL_ 1067 VCSEC_UWBEndpointIndex 4 "UWBDistance0" 3 "UWBDistance1" 2 "UWBDistance2" 1 "UWBDistanceRemote" 0 "UWBRearRightDistance" ;
VAL_ 1067 VCSEC_UWBRearRightDistance0 4095 "SNA" 4094 "NOT_ENABLED" 4093 "INITIATOR_TIMEOUT" 4092 "RESPONDER_TIMEOUT" 4091 "INVALID_DISTANCE" 4090 "HCI_TIMEOUT" 4089 "RESPONDER_ERROR" 4088 "KEYFOB_DIDNT_RESPOND" 4087 "TX_FAILED" 4086 "RX_TIMEOUT" 4085 "PHY_DEC_FAILED" 4084 "TOA_FAILED" 4083 "STS_FAILED" 4082 "MAC_DEC_FAILED" 4081 "IE_DEC_FAILED" 4080 "IE_MISSING" ;
VAL_ 1067 VCSEC_UWBRearRightDistance1 4095 "SNA" 4094 "NOT_ENABLED" 4093 "INITIATOR_TIMEOUT" 4092 "RESPONDER_TIMEOUT" 4091 "INVALID_DISTANCE" 4090 "HCI_TIMEOUT" 4089 "RESPONDER_ERROR" 4088 "KEYFOB_DIDNT_RESPOND" 4087 "TX_FAILED" 4086 "RX_TIMEOUT" 4085 "PHY_DEC_FAILED" 4084 "TOA_FAILED" 4083 "STS_FAILED" 4082 "MAC_DEC_FAILED" 4081 "IE_DEC_FAILED" 4080 "IE_MISSING" ;
VAL_ 1067 VCSEC_UWBRearRightDistance2 4095 "SNA" 4094 "NOT_ENABLED" 4093 "INITIATOR_TIMEOUT" 4092 "RESPONDER_TIMEOUT" 4091 "INVALID_DISTANCE" 4090 "HCI_TIMEOUT" 4089 "RESPONDER_ERROR" 4088 "KEYFOB_DIDNT_RESPOND" 4087 "TX_FAILED" 4086 "RX_TIMEOUT" 4085 "PHY_DEC_FAILED" 4084 "TOA_FAILED" 4083 "STS_FAILED" 4082 "MAC_DEC_FAILED" 4081 "IE_DEC_FAILED" 4080 "IE_MISSING" ;
VAL_ 1067 VCSEC_UWBLeftDistance3 4095 "SNA" 4094 "NOT_ENABLED" 4093 "INITIATOR_TIMEOUT" 4092 "RESPONDER_TIMEOUT" 4091 "INVALID_DISTANCE" 4090 "HCI_TIMEOUT" 4089 "RESPONDER_ERROR" 4088 "KEYFOB_DIDNT_RESPOND" 4087 "TX_FAILED" 4086 "RX_TIMEOUT" 4085 "PHY_DEC_FAILED" 4084 "TOA_FAILED" 4083 "STS_FAILED" 4082 "MAC_DEC_FAILED" 4081 "IE_DEC_FAILED" 4080 "IE_MISSING" ;
VAL_ 1067 VCSEC_UWBRightDistance3 4095 "SNA" 4094 "NOT_ENABLED" 4093 "INITIATOR_TIMEOUT" 4092 "RESPONDER_TIMEOUT" 4091 "INVALID_DISTANCE" 4090 "HCI_TIMEOUT" 4089 "RESPONDER_ERROR" 4088 "KEYFOB_DIDNT_RESPOND" 4087 "TX_FAILED" 4086 "RX_TIMEOUT" 4085 "PHY_DEC_FAILED" 4084 "TOA_FAILED" 4083 "STS_FAILED" 4082 "MAC_DEC_FAILED" 4081 "IE_DEC_FAILED" 4080 "IE_MISSING" ;
VAL_ 1067 VCSEC_UWBRearRightDistance3 4095 "SNA" 4094 "NOT_ENABLED" 4093 "INITIATOR_TIMEOUT" 4092 "RESPONDER_TIMEOUT" 4091 "INVALID_DISTANCE" 4090 "HCI_TIMEOUT" 4089 "RESPONDER_ERROR" 4088 "KEYFOB_DIDNT_RESPOND" 4087 "TX_FAILED" 4086 "RX_TIMEOUT" 4085 "PHY_DEC_FAILED" 4084 "TOA_FAILED" 4083 "STS_FAILED" 4082 "MAC_DEC_FAILED" 4081 "IE_DEC_FAILED" 4080 "IE_MISSING" ;
VAL_ 1067 VCSEC_UWBRearLeftDistance3 4095 "SNA" 4094 "NOT_ENABLED" 4093 "INITIATOR_TIMEOUT" 4092 "RESPONDER_TIMEOUT" 4091 "INVALID_DISTANCE" 4090 "HCI_TIMEOUT" 4089 "RESPONDER_ERROR" 4088 "KEYFOB_DIDNT_RESPOND" 4087 "TX_FAILED" 4086 "RX_TIMEOUT" 4085 "PHY_DEC_FAILED" 4084 "TOA_FAILED" 4083 "STS_FAILED" 4082 "MAC_DEC_FAILED" 4081 "IE_DEC_FAILED" 4080 "IE_MISSING" ;
VAL_ 1067 VCSEC_UWBCenterDistance3 4095 "SNA" 4094 "NOT_ENABLED" 4093 "INITIATOR_TIMEOUT" 4092 "RESPONDER_TIMEOUT" 4091 "INVALID_DISTANCE" 4090 "HCI_TIMEOUT" 4089 "RESPONDER_ERROR" 4088 "KEYFOB_DIDNT_RESPOND" 4087 "TX_FAILED" 4086 "RX_TIMEOUT" 4085 "PHY_DEC_FAILED" 4084 "TOA_FAILED" 4083 "STS_FAILED" 4082 "MAC_DEC_FAILED" 4081 "IE_DEC_FAILED" 4080 "IE_MISSING" ;
VAL_ 1067 VCSEC_UWBLeftDistance2 4095 "SNA" 4094 "NOT_ENABLED" 4093 "INITIATOR_TIMEOUT" 4092 "RESPONDER_TIMEOUT" 4091 "INVALID_DISTANCE" 4090 "HCI_TIMEOUT" 4089 "RESPONDER_ERROR" 4088 "KEYFOB_DIDNT_RESPOND" 4087 "TX_FAILED" 4086 "RX_TIMEOUT" 4085 "PHY_DEC_FAILED" 4084 "TOA_FAILED" 4083 "STS_FAILED" 4082 "MAC_DEC_FAILED" 4081 "IE_DEC_FAILED" 4080 "IE_MISSING" ;
VAL_ 1067 VCSEC_UWBRightDistance2 4095 "SNA" 4094 "NOT_ENABLED" 4093 "INITIATOR_TIMEOUT" 4092 "RESPONDER_TIMEOUT" 4091 "INVALID_DISTANCE" 4090 "HCI_TIMEOUT" 4089 "RESPONDER_ERROR" 4088 "KEYFOB_DIDNT_RESPOND" 4087 "TX_FAILED" 4086 "RX_TIMEOUT" 4085 "PHY_DEC_FAILED" 4084 "TOA_FAILED" 4083 "STS_FAILED" 4082 "MAC_DEC_FAILED" 4081 "IE_DEC_FAILED" 4080 "IE_MISSING" ;
VAL_ 1067 VCSEC_UWBRearDistance2 4095 "SNA" 4094 "NOT_ENABLED" 4093 "INITIATOR_TIMEOUT" 4092 "RESPONDER_TIMEOUT" 4091 "INVALID_DISTANCE" 4090 "HCI_TIMEOUT" 4089 "RESPONDER_ERROR" 4088 "KEYFOB_DIDNT_RESPOND" 4087 "TX_FAILED" 4086 "RX_TIMEOUT" 4085 "PHY_DEC_FAILED" 4084 "TOA_FAILED" 4083 "STS_FAILED" 4082 "MAC_DEC_FAILED" 4081 "IE_DEC_FAILED" 4080 "IE_MISSING" ;
VAL_ 1067 VCSEC_UWBRearLeftDistance2 4095 "SNA" 4094 "NOT_ENABLED" 4093 "INITIATOR_TIMEOUT" 4092 "RESPONDER_TIMEOUT" 4091 "INVALID_DISTANCE" 4090 "HCI_TIMEOUT" 4089 "RESPONDER_ERROR" 4088 "KEYFOB_DIDNT_RESPOND" 4087 "TX_FAILED" 4086 "RX_TIMEOUT" 4085 "PHY_DEC_FAILED" 4084 "TOA_FAILED" 4083 "STS_FAILED" 4082 "MAC_DEC_FAILED" 4081 "IE_DEC_FAILED" 4080 "IE_MISSING" ;
VAL_ 1067 VCSEC_UWBCenterDistance2 4095 "SNA" 4094 "NOT_ENABLED" 4093 "INITIATOR_TIMEOUT" 4092 "RESPONDER_TIMEOUT" 4091 "INVALID_DISTANCE" 4090 "HCI_TIMEOUT" 4089 "RESPONDER_ERROR" 4088 "KEYFOB_DIDNT_RESPOND" 4087 "TX_FAILED" 4086 "RX_TIMEOUT" 4085 "PHY_DEC_FAILED" 4084 "TOA_FAILED" 4083 "STS_FAILED" 4082 "MAC_DEC_FAILED" 4081 "IE_DEC_FAILED" 4080 "IE_MISSING" ;
VAL_ 1067 VCSEC_UWBLeftDistance1 4095 "SNA" 4094 "NOT_ENABLED" 4093 "INITIATOR_TIMEOUT" 4092 "RESPONDER_TIMEOUT" 4091 "INVALID_DISTANCE" 4090 "HCI_TIMEOUT" 4089 "RESPONDER_ERROR" 4088 "KEYFOB_DIDNT_RESPOND" 4087 "TX_FAILED" 4086 "RX_TIMEOUT" 4085 "PHY_DEC_FAILED" 4084 "TOA_FAILED" 4083 "STS_FAILED" 4082 "MAC_DEC_FAILED" 4081 "IE_DEC_FAILED" 4080 "IE_MISSING" ;
VAL_ 1067 VCSEC_UWBRightDistance1 4095 "SNA" 4094 "NOT_ENABLED" 4093 "INITIATOR_TIMEOUT" 4092 "RESPONDER_TIMEOUT" 4091 "INVALID_DISTANCE" 4090 "HCI_TIMEOUT" 4089 "RESPONDER_ERROR" 4088 "KEYFOB_DIDNT_RESPOND" 4087 "TX_FAILED" 4086 "RX_TIMEOUT" 4085 "PHY_DEC_FAILED" 4084 "TOA_FAILED" 4083 "STS_FAILED" 4082 "MAC_DEC_FAILED" 4081 "IE_DEC_FAILED" 4080 "IE_MISSING" ;
VAL_ 1067 VCSEC_UWBRearDistance1 4095 "SNA" 4094 "NOT_ENABLED" 4093 "INITIATOR_TIMEOUT" 4092 "RESPONDER_TIMEOUT" 4091 "INVALID_DISTANCE" 4090 "HCI_TIMEOUT" 4089 "RESPONDER_ERROR" 4088 "KEYFOB_DIDNT_RESPOND" 4087 "TX_FAILED" 4086 "RX_TIMEOUT" 4085 "PHY_DEC_FAILED" 4084 "TOA_FAILED" 4083 "STS_FAILED" 4082 "MAC_DEC_FAILED" 4081 "IE_DEC_FAILED" 4080 "IE_MISSING" ;
VAL_ 1067 VCSEC_UWBRearLeftDistance1 4095 "SNA" 4094 "NOT_ENABLED" 4093 "INITIATOR_TIMEOUT" 4092 "RESPONDER_TIMEOUT" 4091 "INVALID_DISTANCE" 4090 "HCI_TIMEOUT" 4089 "RESPONDER_ERROR" 4088 "KEYFOB_DIDNT_RESPOND" 4087 "TX_FAILED" 4086 "RX_TIMEOUT" 4085 "PHY_DEC_FAILED" 4084 "TOA_FAILED" 4083 "STS_FAILED" 4082 "MAC_DEC_FAILED" 4081 "IE_DEC_FAILED" 4080 "IE_MISSING" ;
VAL_ 1067 VCSEC_UWBCenterDistance1 4095 "SNA" 4094 "NOT_ENABLED" 4093 "INITIATOR_TIMEOUT" 4092 "RESPONDER_TIMEOUT" 4091 "INVALID_DISTANCE" 4090 "HCI_TIMEOUT" 4089 "RESPONDER_ERROR" 4088 "KEYFOB_DIDNT_RESPOND" 4087 "TX_FAILED" 4086 "RX_TIMEOUT" 4085 "PHY_DEC_FAILED" 4084 "TOA_FAILED" 4083 "STS_FAILED" 4082 "MAC_DEC_FAILED" 4081 "IE_DEC_FAILED" 4080 "IE_MISSING" ;
VAL_ 1067 VCSEC_UWBLeftDistance0 4095 "SNA" 4094 "NOT_ENABLED" 4093 "INITIATOR_TIMEOUT" 4092 "RESPONDER_TIMEOUT" 4091 "INVALID_DISTANCE" 4090 "HCI_TIMEOUT" 4089 "RESPONDER_ERROR" 4088 "KEYFOB_DIDNT_RESPOND" 4087 "TX_FAILED" 4086 "RX_TIMEOUT" 4085 "PHY_DEC_FAILED" 4084 "TOA_FAILED" 4083 "STS_FAILED" 4082 "MAC_DEC_FAILED" 4081 "IE_DEC_FAILED" 4080 "IE_MISSING" ;
VAL_ 1067 VCSEC_UWBRightDistance0 4095 "SNA" 4094 "NOT_ENABLED" 4093 "INITIATOR_TIMEOUT" 4092 "RESPONDER_TIMEOUT" 4091 "INVALID_DISTANCE" 4090 "HCI_TIMEOUT" 4089 "RESPONDER_ERROR" 4088 "KEYFOB_DIDNT_RESPOND" 4087 "TX_FAILED" 4086 "RX_TIMEOUT" 4085 "PHY_DEC_FAILED" 4084 "TOA_FAILED" 4083 "STS_FAILED" 4082 "MAC_DEC_FAILED" 4081 "IE_DEC_FAILED" 4080 "IE_MISSING" ;
VAL_ 1067 VCSEC_UWBRearDistance0 4095 "SNA" 4094 "NOT_ENABLED" 4093 "INITIATOR_TIMEOUT" 4092 "RESPONDER_TIMEOUT" 4091 "INVALID_DISTANCE" 4090 "HCI_TIMEOUT" 4089 "RESPONDER_ERROR" 4088 "KEYFOB_DIDNT_RESPOND" 4087 "TX_FAILED" 4086 "RX_TIMEOUT" 4085 "PHY_DEC_FAILED" 4084 "TOA_FAILED" 4083 "STS_FAILED" 4082 "MAC_DEC_FAILED" 4081 "IE_DEC_FAILED" 4080 "IE_MISSING" ;
VAL_ 1067 VCSEC_UWBRearLeftDistance0 4095 "SNA" 4094 "NOT_ENABLED" 4093 "INITIATOR_TIMEOUT" 4092 "RESPONDER_TIMEOUT" 4091 "INVALID_DISTANCE" 4090 "HCI_TIMEOUT" 4089 "RESPONDER_ERROR" 4088 "KEYFOB_DIDNT_RESPOND" 4087 "TX_FAILED" 4086 "RX_TIMEOUT" 4085 "PHY_DEC_FAILED" 4084 "TOA_FAILED" 4083 "STS_FAILED" 4082 "MAC_DEC_FAILED" 4081 "IE_DEC_FAILED" 4080 "IE_MISSING" ;
VAL_ 1067 VCSEC_UWBCenterDistance0 4095 "SNA" 4094 "NOT_ENABLED" 4093 "INITIATOR_TIMEOUT" 4092 "RESPONDER_TIMEOUT" 4091 "INVALID_DISTANCE" 4090 "HCI_TIMEOUT" 4089 "RESPONDER_ERROR" 4088 "KEYFOB_DIDNT_RESPOND" 4087 "TX_FAILED" 4086 "RX_TIMEOUT" 4085 "PHY_DEC_FAILED" 4084 "TOA_FAILED" 4083 "STS_FAILED" 4082 "MAC_DEC_FAILED" 4081 "IE_DEC_FAILED" 4080 "IE_MISSING" ;
VAL_ 761 VCSEC_bleDisconnectionReason 255 "UNKNOWN_REASON_FF" 62 "CONNECTION_FAILED_TO_ESTABLISH" 61 "MIC_FAILURE" 59 "UNACCEPTABLE_CONNECTION_INTERVAL" 41 "KEY_PAIRING_NOT_SUPPORTED" 40 "CONTROL_PACKET_INSTANT_PASSED" 34 "CONTROL_PACKET_TIMEOUT" 26 "UNSUPPORTED_REMOTE_FEATURE" 22 "HOST_REQUESTED_TERMINATION" 21 "REMOTE_DEVICE_POWER_OFF" 20 "REMOTE_DEVICE_LOW_RESOURCES" 19 "REMOTE_USER_TERMINATED" 8 "CONNECTION_SUPERVISION_TIMEOUT" 5 "AUTHENTICATION_FAILURE" 0 "UNKNOWN_REASON_0" ;
VAL_ 761 VCSEC_AdditionalAuthInfoIndex 5 "WALKUP_UNLOCK_BEHAVIOR" 4 "UNKNOWN_BLE_DEVICE_WITH_IN_SUMMON_RANGE" 3 "KEY_WITH_IN_SUMMON_RANGE_2" 2 "KEY_WITH_IN_SUMMON_RANGE_1" 1 "KEY_WITH_IN_SUMMON_RANGE_0" 0 "ACTIVE_KEY_SHA1" ;
VAL_ 761 VCSEC_activeKeyReason 7 "ACTIVE_KEY_SELECTION_REASON_UWB_DEVICE_CLOSEST_TO_DOOR" 6 "ACTIVE_KEY_SELECTION_REASON_AUTO_PRESENT_DOOR_COMMAND" 5 "ACTIVE_KEY_SELECTION_REASON_ONLY_AUTHED_DEVICE" 4 "ACTIVE_KEY_SELECTION_REASON_RKE_ACTION" 3 "ACTIVE_KEY_SELECTION_REASON_BLE_DEVICE_CLOSEST_TO_DOOR" 2 "ACTIVE_KEY_SELECTION_REASON_RKE_AUTH" 1 "ACTIVE_KEY_SELECTION_REASON_NFC_AUTH" 0 "ACTIVE_KEY_SELECTION_REASON_NONE" ;
VAL_ 761 VCSEC_algoUsedForSummonRange0 1 "SUMMON_RANGE_ALGO_USED_UWB" 0 "SUMMON_RANGE_ALGO_USED_BLE" ;
VAL_ 761 VCSEC_algoUsedForSummonRange1 1 "SUMMON_RANGE_ALGO_USED_UWB" 0 "SUMMON_RANGE_ALGO_USED_BLE" ;
VAL_ 761 VCSEC_algoUsedForSummonRange2 1 "SUMMON_RANGE_ALGO_USED_UWB" 0 "SUMMON_RANGE_ALGO_USED_BLE" ;
VAL_ 761 VCSEC_frunkOpenSuggestionRespons 6 "SUGGESTIONS_RESPONSE_CLOSURE_SUGGESTION_DISABLED" 5 "SUGGESTIONS_RESPONSE_FAIL_TO_SETUP" 4 "SUGGESTIONS_RESPONSE_TIMEOUT_CLEARED" 3 "SUGGESTIONS_RESPONSE_CLEARED_BY_USER" 2 "SUGGESTIONS_RESPONSE_REJECTED_BY_USER" 1 "SUGGESTIONS_RESPONSE_ACCEPTED_BY_USER" 0 "SUGGESTIONS_RESPONSE_UNKNOWN" ;
VAL_ 761 VCSEC_NFCAuthFromBPillarFormFact 4 "KEY_FORM_FACTOR_COARSE_UNKNOWN" 3 "KEY_FORM_FACTOR_COARSE_ANDROID" 2 "KEY_FORM_FACTOR_COARSE_KEYFOB" 1 "KEY_FORM_FACTOR_COARSE_NFC_CARD" 0 "KEY_FORM_FACTOR_COARSE_NONE" ;
VAL_ 761 VCSEC_NFCAuthFromCenterConsoleFo 4 "KEY_FORM_FACTOR_COARSE_UNKNOWN" 3 "KEY_FORM_FACTOR_COARSE_ANDROID" 2 "KEY_FORM_FACTOR_COARSE_KEYFOB" 1 "KEY_FORM_FACTOR_COARSE_NFC_CARD" 0 "KEY_FORM_FACTOR_COARSE_NONE" ;
VAL_ 761 VCSEC_trunkOpenSuggestionRespons 6 "SUGGESTIONS_RESPONSE_CLOSURE_SUGGESTION_DISABLED" 5 "SUGGESTIONS_RESPONSE_FAIL_TO_SETUP" 4 "SUGGESTIONS_RESPONSE_TIMEOUT_CLEARED" 3 "SUGGESTIONS_RESPONSE_CLEARED_BY_USER" 2 "SUGGESTIONS_RESPONSE_REJECTED_BY_USER" 1 "SUGGESTIONS_RESPONSE_ACCEPTED_BY_USER" 0 "SUGGESTIONS_RESPONSE_UNKNOWN" ;
VAL_ 825 VCSEC_authRejectionReason 5 "AUTHENTICATIONREJECTION_DEVICE_NOT_UNLOCKED_ON_WRIST" 4 "AUTHENTICATIONREJECTION_PASSIVE_DISABLED_AUTOMATION" 3 "AUTHENTICATIONREJECTION_NO_TOKEN" 2 "AUTHENTICATIONREJECTION_PASSIVE_DISABLED" 1 "AUTHENTICATIONREJECTION_DEVICE_STATIONARY" 0 "AUTHENTICATIONREJECTION_NONE" ;
VAL_ 825 VCSEC_operationMode 2 "OPERATION_MODE_FLEET" 1 "OPERATION_MODE_OWNER" 0 "OPERATION_MODE_UNKNOWN" ;
VAL_ 825 VCSEC_vehicleLockStatus 15 "LOCK_STATUS_PASSIVE_INTERNAL_LOCKED" 14 "LOCK_STATUS_PASSIVE_INTERNAL_UNLOCKED" 13 "LOCK_STATUS_CRASH_UNLOCKED" 12 "LOCK_STATUS_ACTIVE_REMOTE_LOCKED" 11 "LOCK_STATUS_ACTIVE_REMOTE_UNLOCKED" 10 "LOCK_STATUS_ACTIVE_UI_LOCKED" 9 "LOCK_STATUS_ACTIVE_UI_UNLOCKED" 8 "LOCK_STATUS_ACTIVE_BLE_LOCKED" 7 "LOCK_STATUS_ACTIVE_BLE_UNLOCKED" 6 "LOCK_STATUS_ACTIVE_SELECTIVE_UNLOCKED" 5 "LOCK_STATUS_PASSIVE_BLE_LOCKED" 4 "LOCK_STATUS_PASSIVE_BLE_UNLOCKED" 3 "LOCK_STATUS_PASSIVE_SELECTIVE_UNLOCKED" 2 "LOCK_STATUS_ACTIVE_NFC_LOCKED" 1 "LOCK_STATUS_ACTIVE_NFC_UNLOCKED" 0 "LOCK_STATUS_SNA" ;
VAL_ 825 VCSEC_authenticationStatus 2 "AUTHENTICATION_AUTHENTICATED_FOR_DRIVE" 1 "AUTHENTICATION_AUTHENTICATED_FOR_UNLOCK" 0 "AUTHENTICATION_NONE" ;
VAL_ 825 VCSEC_chargePortLockStatus 1 "CLOSURE_LOCKED" 0 "CLOSURE_UNLOCKED" ;
VAL_ 825 VCSEC_leftFrontLockStatus 1 "CLOSURE_LOCKED" 0 "CLOSURE_UNLOCKED" ;
VAL_ 825 VCSEC_leftRearLockStatus 1 "CLOSURE_LOCKED" 0 "CLOSURE_UNLOCKED" ;
VAL_ 825 VCSEC_rightFrontLockStatus 1 "CLOSURE_LOCKED" 0 "CLOSURE_UNLOCKED" ;
VAL_ 825 VCSEC_rightRearLockStatus 1 "CLOSURE_LOCKED" 0 "CLOSURE_UNLOCKED" ;
VAL_ 825 VCSEC_trunkLockStatus 1 "CLOSURE_LOCKED" 0 "CLOSURE_UNLOCKED" ;
VAL_ 825 VCSEC_lockRequestType 21 "LOCK_REQUEST_KEYFOB_OPEN_DOOR_REQUEST" 20 "LOCK_REQUEST_PASSIVE_AUTO_PRESENT_DOOR_REQUEST" 19 "LOCK_REQUEST_PASSIVE_INTERNAL_LOCK_PROMOTION" 18 "LOCK_REQUEST_ACTIVE_BLE_LOCK" 17 "LOCK_REQUEST_ACTIVE_BLE_UNLOCK" 16 "LOCK_REQUEST_ACTIVE_NFC_LOCK" 15 "LOCK_REQUEST_ACTIVE_NFC_UNLOCK" 14 "LOCK_REQUEST_ACTIVE_REMOTE_LOCK" 13 "LOCK_REQUEST_ACTIVE_REMOTE_UNLOCK" 12 "LOCK_REQUEST_ACTIVE_UI_BUTTON_LOCK" 11 "LOCK_REQUEST_ACTIVE_UI_BUTTON_UNLOCK" 10 "LOCK_REQUEST_CRASH_UNLOCK" 9 "LOCK_REQUEST_PASSIVE_BLE_LOCK" 8 "LOCK_REQUEST_PASSIVE_BLE_INTERIOR_HANDLE_UNLOCK" 7 "LOCK_REQUEST_PASSIVE_BLE_EXTERIOR_HANDLE_UNLOCK" 6 "LOCK_REQUEST_PASSIVE_BLE_EXTERIOR_CHARGEHANDLEBUTTON_UNLOCK" 5 "LOCK_REQUEST_PASSIVE_BLE_WALKUP_UNLOCK" 4 "LOCK_REQUEST_PASSIVE_DRIVE_AWAY_LOCK" 3 "LOCK_REQUEST_PASSIVE_INTERNAL_HANDLE_UNLOCK" 2 "LOCK_REQUEST_PASSIVE_PARKBUTTON_UNLOCK" 1 "LOCK_REQUEST_PASSIVE_SHIFT_TO_P_UNLOCK" 0 "LOCK_REQUEST_NONE" ;
VAL_ 825 VCSEC_summonRequest 5 "SUMMON_REQUEST_SNA" 4 "SUMMON_REQUEST_STOP" 3 "SUMMON_REQUEST_BACKWARD" 2 "SUMMON_REQUEST_FORWARD" 1 "SUMMON_REQUEST_PRIME" 0 "SUMMON_REQUEST_IDLE" ;
VAL_ 825 VCSEC_3rdPartyPLGRequest 3 "CLOSURE_REQUEST_SNA" 2 "CLOSURE_REQUEST_STOP" 1 "CLOSURE_REQUEST_MOVE" 0 "CLOSURE_REQUEST_NONE" ;
VAL_ 825 VCSEC_3rdPartyFrunkPLGRequest 3 "CLOSURE_REQUEST_SNA" 2 "CLOSURE_REQUEST_STOP" 1 "CLOSURE_REQUEST_MOVE" 0 "CLOSURE_REQUEST_NONE" ;
VAL_ 825 VCSEC_MCUCommandType 5 "MCU_COMMAND_COMMAND5" 4 "MCU_COMMAND_COMMAND4" 3 "MCU_COMMAND_COMMAND3" 2 "MCU_COMMAND_REMOTE_START" 1 "MCU_COMMAND_REMOTE_UNLOCK" 0 "MCU_COMMAND_NONE" ;
VAL_ 825 VCSEC_frunkLockStatus 1 "CLOSURE_LOCKED" 0 "CLOSURE_UNLOCKED" ;
VAL_ 825 VCSEC_alarmStatus 15 "ALARM_STATUS_SNA" 7 "ALARM_STATUS_DEFAULT" 6 "ALARM_STATUS_IMMINENT" 5 "ALARM_STATUS_TRIGGERED_FLASH_INACTIVE" 4 "ALARM_STATUS_ERROR" 3 "ALARM_STATUS_TRIGGERED_FLASH_ACTIVE" 2 "ALARM_STATUS_PARTIAL_ARMED" 1 "ALARM_STATUS_ARMED" 0 "ALARM_STATUS_DISARMED" ;
VAL_ 825 VCSEC_immobilizerState 6 "IMMOBILIZER_STATE_IMMOBILIZED" 5 "IMMOBILIZER_STATE_SEND_NO_GO_AUTH_RESPONSE" 4 "IMMOBILIZER_STATE_SEND_AUTH_RESPONSE" 3 "IMMOBILIZER_STATE_ENCRYPT" 2 "IMMOBILIZER_STATE_ENCRYPT_BEGIN" 1 "IMMOBILIZER_STATE_PREPARE" 0 "IMMOBILIZER_STATE_IDLE" ;
VAL_ 825 VCSEC_lockIndicationRequest 4 "INDICATION_HOLD" 3 "INDICATION_TRIPLE" 2 "INDICATION_DOUBLE" 1 "INDICATION_SINGLE" 0 "INDICATION_NONE_SNA" ;
VAL_ 825 VCSEC_simpleLockStatus 2 "SIMPLE_LOCK_STATUS_LOCKED" 1 "SIMPLE_LOCK_STATUS_UNLOCKED" 0 "SIMPLE_LOCK_STATUS_SNA" ;
VAL_ 825 VCSEC_keyChannelIndexed 15 "SNA" ;
VAL_ 825 VCSEC_remoteStartActive 3 "VCSEC_REMOTE_START_TYPE_SIGNED_COMMAND_PIN_REQUIRED" 2 "VCSEC_REMOTE_START_TYPE_SIGNED_COMMAND" 1 "VCSEC_REMOTE_START_TYPE_LEGACY" 0 "VCSEC_REMOTE_START_TYPE_NONE" ;
VAL_ 1817 VCSEC_debug100msIndex 23 "ConnectionBenchmark2" 22 "ConnectionBenchmark1" 21 "ConnectionBenchmark0" 20 "BLEDeviceDebug" 19 "SerialPortDebug" 14 "NNClassifierDebug" 13 "ProtobufDebug" 12 "RoutableDebug" 10 "NIStateRemote" 9 "NIState2" 8 "NIState0" 7 "BLEBondingState" 5 "Mux5" 3 "LastAdvertRSSI" 2 "UHFReceiver" 1 "Mux1" 0 "Mux0" ;
VAL_ 1817 VCSEC_walkAwayLockKeyState 3 "SECURITY_WALKAWAYLOCKING_NO_KEYS_PRESENT" 2 "SECURITY_WALKAWAYLOCKING_KEY_WAIT_FOR_NO_KEYS_PRESENT" 1 "SECURITY_WALKAWAYLOCKING_KEY_STATE_AWAITING_KEY_LEAVING" 0 "SECURITY_WALKAWAYLOCKING_KEY_STATE_IDLE" ;
VAL_ 1817 VCSEC_walkAwayLockState 5 "SECURITY_WALKAWAYLOCKING_STATE_INHIBITED" 4 "SECURITY_WALKAWAYLOCKING_STATE_DISABLED_DUE_TO_KEY_PRESENT" 3 "SECURITY_WALKAWAYLOCKING_STATE_LOCK_DESIRED" 2 "SECURITY_WALKAWAYLOCKING_STATE_WAITING_FOR_KEY_LEAVING" 1 "SECURITY_WALKAWAYLOCKING_STATE_WALK_AWAY_LOCK_ARMING" 0 "SECURITY_WALKAWAYLOCKING_STATE_IDLE" ;
VAL_ 1817 VCSEC_endpointLayout 2 "VCSEC_ENDPOINT_LAYOUT_3" 1 "VCSEC_ENDPOINT_LAYOUT_2" 0 "VCSEC_ENDPOINT_LAYOUT_1" ;
VAL_ 1817 VCSEC_walkUpUnlockState 4 "WALK_UP_UNLOCK_STATE_DISABLED" 3 "WALK_UP_UNLOCK_STATE_UNLOCK_DESIRED" 2 "WALK_UP_UNLOCK_STATE_AWAITING_KEY" 1 "WALK_UP_UNLOCK_STATE_ARMING" 0 "WALK_UP_UNLOCK_STATE_IDLE" ;
VAL_ 1817 VCSEC_pollingReason 13 "POLLINGREASON_MULTIPLE" 12 "POLLINGREASON_AUTOPILOT" 11 "POLLINGREASON_APPROACH_LIGHTING" 10 "POLLINGREASON_AUTO_PRESENT_HANDLES" 9 "POLLINGREASON_AUTORELOCK" 8 "POLLINGREASON_DRIVE_AWAY_CHECK_FOR_KEY" 7 "POLLINGREASON_AUTO_PRESENT_DOOR" 6 "POLLINGREASON_ACCESSORY_RAIL" 5 "POLLINGREASON_WALK_UP_UNLOCK" 4 "POLLINGREASON_WALK_AWAY_LOCK" 3 "POLLINGREASON_PASSIVE_UNLOCK" 2 "POLLINGREASON_PASSIVE_AUTHENTICATION" 1 "POLLINGREASON_IMMOBILIZER" 0 "POLLINGREASON_NONE" ;
VAL_ 1817 VCSEC_thermalDetectState 3 "VCSEC_THERMALDETECTIONSTATE_TRIPPED" 2 "VCSEC_THERMALDETECTIONSTATE_CONFIRMING_THRESHOLD" 1 "VCSEC_THERMALDETECTIONSTATE_MONITORING" 0 "VCSEC_THERMALDETECTIONSTATE_DISABLED" ;
VAL_ 1817 VCSEC_connection0BondingState 15 "WAIT_FOR_BOND_REJECTED" 14 "BOND" 13 "WAIT_FOR_BOND_REQUEST" 12 "BOND_FAILURE" 11 "PAIRING_REQUESTED" 10 "REJECT_BOND" 9 "WAIT_FOR_SIGNABLE" 8 "SEND_SIGNABLE" 7 "WAIT_FOR_BOND" 6 "WAIT_FOR_PAIRING" 5 "WAIT_FOR_AUTHENTICATE" 4 "SHOULD_BE_BONDED" 3 "BONDED" 2 "NOT_BONDED" 1 "CONNECTED" 0 "NOT_CONNECTED" ;
VAL_ 1817 VCSEC_connection1BondingState 15 "WAIT_FOR_BOND_REJECTED" 14 "BOND" 13 "WAIT_FOR_BOND_REQUEST" 12 "BOND_FAILURE" 11 "PAIRING_REQUESTED" 10 "REJECT_BOND" 9 "WAIT_FOR_SIGNABLE" 8 "SEND_SIGNABLE" 7 "WAIT_FOR_BOND" 6 "WAIT_FOR_PAIRING" 5 "WAIT_FOR_AUTHENTICATE" 4 "SHOULD_BE_BONDED" 3 "BONDED" 2 "NOT_BONDED" 1 "CONNECTED" 0 "NOT_CONNECTED" ;
VAL_ 1817 VCSEC_connection2BondingState 15 "WAIT_FOR_BOND_REJECTED" 14 "BOND" 13 "WAIT_FOR_BOND_REQUEST" 12 "BOND_FAILURE" 11 "PAIRING_REQUESTED" 10 "REJECT_BOND" 9 "WAIT_FOR_SIGNABLE" 8 "SEND_SIGNABLE" 7 "WAIT_FOR_BOND" 6 "WAIT_FOR_PAIRING" 5 "WAIT_FOR_AUTHENTICATE" 4 "SHOULD_BE_BONDED" 3 "BONDED" 2 "NOT_BONDED" 1 "CONNECTED" 0 "NOT_CONNECTED" ;
VAL_ 1817 VCSEC_connection0UWBAvailability 16 "UNAVAILABLE_UNKNOWN_REASON" 15 "UNAVAILABLE_UWB_DISABLED_BY_USER" 14 "PHONE_ERROR" 13 "RADIOCONFIG_NOT_READY" 12 "UPDATE_NOT_READY" 11 "GENEALOGY_NOT_READY" 10 "BLE_CHIP_NOT_READY" 9 "UWB_CHIP_NOT_READY" 8 "UNAVAILABLE_NOT_SELECTED" 7 "UWB_NOT_ENABLED_ON_THE_VEHICLE" 6 "AVAILBLE_BUT_NOT_GAP_BONDED" 5 "UNAVAILABLE_PERMISSION_DENIED" 4 "UNAVAILABLE_UNSUPPORTED_DEVICE" 3 "TEMPORARILY_UNAVAILABLE" 2 "AVAILABLE_BUT_NOT_RANGING_ON_DRIVER_ENDPOINT" 1 "AVAILABLE" 0 "NONE" ;
VAL_ 1817 VCSEC_connection1UWBAvailability 16 "UNAVAILABLE_UNKNOWN_REASON" 15 "UNAVAILABLE_UWB_DISABLED_BY_USER" 14 "PHONE_ERROR" 13 "RADIOCONFIG_NOT_READY" 12 "UPDATE_NOT_READY" 11 "GENEALOGY_NOT_READY" 10 "BLE_CHIP_NOT_READY" 9 "UWB_CHIP_NOT_READY" 8 "UNAVAILABLE_NOT_SELECTED" 7 "UWB_NOT_ENABLED_ON_THE_VEHICLE" 6 "AVAILBLE_BUT_NOT_GAP_BONDED" 5 "UNAVAILABLE_PERMISSION_DENIED" 4 "UNAVAILABLE_UNSUPPORTED_DEVICE" 3 "TEMPORARILY_UNAVAILABLE" 2 "AVAILABLE_BUT_NOT_RANGING_ON_DRIVER_ENDPOINT" 1 "AVAILABLE" 0 "NONE" ;
VAL_ 1817 VCSEC_connection2UWBAvailability 16 "UNAVAILABLE_UNKNOWN_REASON" 15 "UNAVAILABLE_UWB_DISABLED_BY_USER" 14 "PHONE_ERROR" 13 "RADIOCONFIG_NOT_READY" 12 "UPDATE_NOT_READY" 11 "GENEALOGY_NOT_READY" 10 "BLE_CHIP_NOT_READY" 9 "UWB_CHIP_NOT_READY" 8 "UNAVAILABLE_NOT_SELECTED" 7 "UWB_NOT_ENABLED_ON_THE_VEHICLE" 6 "AVAILBLE_BUT_NOT_GAP_BONDED" 5 "UNAVAILABLE_PERMISSION_DENIED" 4 "UNAVAILABLE_UNSUPPORTED_DEVICE" 3 "TEMPORARILY_UNAVAILABLE" 2 "AVAILABLE_BUT_NOT_RANGING_ON_DRIVER_ENDPOINT" 1 "AVAILABLE" 0 "NONE" ;
VAL_ 1817 VCSEC_NISessionStateCenter0 21 "COUNT" 20 "SESSION_INITIATE" 19 "WAIT_FOR_SESSION_INITIATE" 18 "WAIT_FOR_SESSION_STATE_ACTIVE" 17 "UNRECOVERABLE_DEVICE_ERROR" 16 "ERROR_WAIT_FOR_RESET" 15 "WAIT_FOR_RETRY_AFTER_ERROR" 14 "WAIT_FOR_SESSION_DEINIT" 13 "DEINIT_SESSION" 12 "WAIT_FOR_SESSION_STOP" 11 "STOP_SESSION" 10 "RANGING" 9 "WAIT_FOR_RANGING_STARTED_CONFIRMATION" 8 "WAIT_FOR_APPLE_SESSION_INITIATE" 7 "APPLE_SESSION_INITIATE" 6 "WAIT_FOR_APPLE_SHAREABLE_CONFIGURATION_DATA" 5 "SEND_CONFIGURATION_DATA_TO_PHONE" 4 "WAIT_FOR_CONFIGURATION_DATA" 3 "REQUEST_CONFIGURATION_DATA" 2 "WAIT_FOR_CORE_CONFIG_DATA" 1 "APPLY_CORE_CONFIG_DATA" 0 "IDLE" ;
VAL_ 1817 VCSEC_NISessionStateLeft0 21 "COUNT" 20 "SESSION_INITIATE" 19 "WAIT_FOR_SESSION_INITIATE" 18 "WAIT_FOR_SESSION_STATE_ACTIVE" 17 "UNRECOVERABLE_DEVICE_ERROR" 16 "ERROR_WAIT_FOR_RESET" 15 "WAIT_FOR_RETRY_AFTER_ERROR" 14 "WAIT_FOR_SESSION_DEINIT" 13 "DEINIT_SESSION" 12 "WAIT_FOR_SESSION_STOP" 11 "STOP_SESSION" 10 "RANGING" 9 "WAIT_FOR_RANGING_STARTED_CONFIRMATION" 8 "WAIT_FOR_APPLE_SESSION_INITIATE" 7 "APPLE_SESSION_INITIATE" 6 "WAIT_FOR_APPLE_SHAREABLE_CONFIGURATION_DATA" 5 "SEND_CONFIGURATION_DATA_TO_PHONE" 4 "WAIT_FOR_CONFIGURATION_DATA" 3 "REQUEST_CONFIGURATION_DATA" 2 "WAIT_FOR_CORE_CONFIG_DATA" 1 "APPLY_CORE_CONFIG_DATA" 0 "IDLE" ;
VAL_ 1817 VCSEC_NISessionStateRight0 21 "COUNT" 20 "SESSION_INITIATE" 19 "WAIT_FOR_SESSION_INITIATE" 18 "WAIT_FOR_SESSION_STATE_ACTIVE" 17 "UNRECOVERABLE_DEVICE_ERROR" 16 "ERROR_WAIT_FOR_RESET" 15 "WAIT_FOR_RETRY_AFTER_ERROR" 14 "WAIT_FOR_SESSION_DEINIT" 13 "DEINIT_SESSION" 12 "WAIT_FOR_SESSION_STOP" 11 "STOP_SESSION" 10 "RANGING" 9 "WAIT_FOR_RANGING_STARTED_CONFIRMATION" 8 "WAIT_FOR_APPLE_SESSION_INITIATE" 7 "APPLE_SESSION_INITIATE" 6 "WAIT_FOR_APPLE_SHAREABLE_CONFIGURATION_DATA" 5 "SEND_CONFIGURATION_DATA_TO_PHONE" 4 "WAIT_FOR_CONFIGURATION_DATA" 3 "REQUEST_CONFIGURATION_DATA" 2 "WAIT_FOR_CORE_CONFIG_DATA" 1 "APPLY_CORE_CONFIG_DATA" 0 "IDLE" ;
VAL_ 1817 VCSEC_NISessionStateRearLeft0 21 "COUNT" 20 "SESSION_INITIATE" 19 "WAIT_FOR_SESSION_INITIATE" 18 "WAIT_FOR_SESSION_STATE_ACTIVE" 17 "UNRECOVERABLE_DEVICE_ERROR" 16 "ERROR_WAIT_FOR_RESET" 15 "WAIT_FOR_RETRY_AFTER_ERROR" 14 "WAIT_FOR_SESSION_DEINIT" 13 "DEINIT_SESSION" 12 "WAIT_FOR_SESSION_STOP" 11 "STOP_SESSION" 10 "RANGING" 9 "WAIT_FOR_RANGING_STARTED_CONFIRMATION" 8 "WAIT_FOR_APPLE_SESSION_INITIATE" 7 "APPLE_SESSION_INITIATE" 6 "WAIT_FOR_APPLE_SHAREABLE_CONFIGURATION_DATA" 5 "SEND_CONFIGURATION_DATA_TO_PHONE" 4 "WAIT_FOR_CONFIGURATION_DATA" 3 "REQUEST_CONFIGURATION_DATA" 2 "WAIT_FOR_CORE_CONFIG_DATA" 1 "APPLY_CORE_CONFIG_DATA" 0 "IDLE" ;
VAL_ 1817 VCSEC_NISessionStateRearRight0 21 "COUNT" 20 "SESSION_INITIATE" 19 "WAIT_FOR_SESSION_INITIATE" 18 "WAIT_FOR_SESSION_STATE_ACTIVE" 17 "UNRECOVERABLE_DEVICE_ERROR" 16 "ERROR_WAIT_FOR_RESET" 15 "WAIT_FOR_RETRY_AFTER_ERROR" 14 "WAIT_FOR_SESSION_DEINIT" 13 "DEINIT_SESSION" 12 "WAIT_FOR_SESSION_STOP" 11 "STOP_SESSION" 10 "RANGING" 9 "WAIT_FOR_RANGING_STARTED_CONFIRMATION" 8 "WAIT_FOR_APPLE_SESSION_INITIATE" 7 "APPLE_SESSION_INITIATE" 6 "WAIT_FOR_APPLE_SHAREABLE_CONFIGURATION_DATA" 5 "SEND_CONFIGURATION_DATA_TO_PHONE" 4 "WAIT_FOR_CONFIGURATION_DATA" 3 "REQUEST_CONFIGURATION_DATA" 2 "WAIT_FOR_CORE_CONFIG_DATA" 1 "APPLY_CORE_CONFIG_DATA" 0 "IDLE" ;
VAL_ 1817 VCSEC_NISessionStateRear0 21 "COUNT" 20 "SESSION_INITIATE" 19 "WAIT_FOR_SESSION_INITIATE" 18 "WAIT_FOR_SESSION_STATE_ACTIVE" 17 "UNRECOVERABLE_DEVICE_ERROR" 16 "ERROR_WAIT_FOR_RESET" 15 "WAIT_FOR_RETRY_AFTER_ERROR" 14 "WAIT_FOR_SESSION_DEINIT" 13 "DEINIT_SESSION" 12 "WAIT_FOR_SESSION_STOP" 11 "STOP_SESSION" 10 "RANGING" 9 "WAIT_FOR_RANGING_STARTED_CONFIRMATION" 8 "WAIT_FOR_APPLE_SESSION_INITIATE" 7 "APPLE_SESSION_INITIATE" 6 "WAIT_FOR_APPLE_SHAREABLE_CONFIGURATION_DATA" 5 "SEND_CONFIGURATION_DATA_TO_PHONE" 4 "WAIT_FOR_CONFIGURATION_DATA" 3 "REQUEST_CONFIGURATION_DATA" 2 "WAIT_FOR_CORE_CONFIG_DATA" 1 "APPLY_CORE_CONFIG_DATA" 0 "IDLE" ;
VAL_ 1817 VCSEC_NISessionStateCenter1 21 "COUNT" 20 "SESSION_INITIATE" 19 "WAIT_FOR_SESSION_INITIATE" 18 "WAIT_FOR_SESSION_STATE_ACTIVE" 17 "UNRECOVERABLE_DEVICE_ERROR" 16 "ERROR_WAIT_FOR_RESET" 15 "WAIT_FOR_RETRY_AFTER_ERROR" 14 "WAIT_FOR_SESSION_DEINIT" 13 "DEINIT_SESSION" 12 "WAIT_FOR_SESSION_STOP" 11 "STOP_SESSION" 10 "RANGING" 9 "WAIT_FOR_RANGING_STARTED_CONFIRMATION" 8 "WAIT_FOR_APPLE_SESSION_INITIATE" 7 "APPLE_SESSION_INITIATE" 6 "WAIT_FOR_APPLE_SHAREABLE_CONFIGURATION_DATA" 5 "SEND_CONFIGURATION_DATA_TO_PHONE" 4 "WAIT_FOR_CONFIGURATION_DATA" 3 "REQUEST_CONFIGURATION_DATA" 2 "WAIT_FOR_CORE_CONFIG_DATA" 1 "APPLY_CORE_CONFIG_DATA" 0 "IDLE" ;
VAL_ 1817 VCSEC_NISessionStateLeft1 21 "COUNT" 20 "SESSION_INITIATE" 19 "WAIT_FOR_SESSION_INITIATE" 18 "WAIT_FOR_SESSION_STATE_ACTIVE" 17 "UNRECOVERABLE_DEVICE_ERROR" 16 "ERROR_WAIT_FOR_RESET" 15 "WAIT_FOR_RETRY_AFTER_ERROR" 14 "WAIT_FOR_SESSION_DEINIT" 13 "DEINIT_SESSION" 12 "WAIT_FOR_SESSION_STOP" 11 "STOP_SESSION" 10 "RANGING" 9 "WAIT_FOR_RANGING_STARTED_CONFIRMATION" 8 "WAIT_FOR_APPLE_SESSION_INITIATE" 7 "APPLE_SESSION_INITIATE" 6 "WAIT_FOR_APPLE_SHAREABLE_CONFIGURATION_DATA" 5 "SEND_CONFIGURATION_DATA_TO_PHONE" 4 "WAIT_FOR_CONFIGURATION_DATA" 3 "REQUEST_CONFIGURATION_DATA" 2 "WAIT_FOR_CORE_CONFIG_DATA" 1 "APPLY_CORE_CONFIG_DATA" 0 "IDLE" ;
VAL_ 1817 VCSEC_NISessionStateRight1 21 "COUNT" 20 "SESSION_INITIATE" 19 "WAIT_FOR_SESSION_INITIATE" 18 "WAIT_FOR_SESSION_STATE_ACTIVE" 17 "UNRECOVERABLE_DEVICE_ERROR" 16 "ERROR_WAIT_FOR_RESET" 15 "WAIT_FOR_RETRY_AFTER_ERROR" 14 "WAIT_FOR_SESSION_DEINIT" 13 "DEINIT_SESSION" 12 "WAIT_FOR_SESSION_STOP" 11 "STOP_SESSION" 10 "RANGING" 9 "WAIT_FOR_RANGING_STARTED_CONFIRMATION" 8 "WAIT_FOR_APPLE_SESSION_INITIATE" 7 "APPLE_SESSION_INITIATE" 6 "WAIT_FOR_APPLE_SHAREABLE_CONFIGURATION_DATA" 5 "SEND_CONFIGURATION_DATA_TO_PHONE" 4 "WAIT_FOR_CONFIGURATION_DATA" 3 "REQUEST_CONFIGURATION_DATA" 2 "WAIT_FOR_CORE_CONFIG_DATA" 1 "APPLY_CORE_CONFIG_DATA" 0 "IDLE" ;
VAL_ 1817 VCSEC_NISessionStateRearLeft1 21 "COUNT" 20 "SESSION_INITIATE" 19 "WAIT_FOR_SESSION_INITIATE" 18 "WAIT_FOR_SESSION_STATE_ACTIVE" 17 "UNRECOVERABLE_DEVICE_ERROR" 16 "ERROR_WAIT_FOR_RESET" 15 "WAIT_FOR_RETRY_AFTER_ERROR" 14 "WAIT_FOR_SESSION_DEINIT" 13 "DEINIT_SESSION" 12 "WAIT_FOR_SESSION_STOP" 11 "STOP_SESSION" 10 "RANGING" 9 "WAIT_FOR_RANGING_STARTED_CONFIRMATION" 8 "WAIT_FOR_APPLE_SESSION_INITIATE" 7 "APPLE_SESSION_INITIATE" 6 "WAIT_FOR_APPLE_SHAREABLE_CONFIGURATION_DATA" 5 "SEND_CONFIGURATION_DATA_TO_PHONE" 4 "WAIT_FOR_CONFIGURATION_DATA" 3 "REQUEST_CONFIGURATION_DATA" 2 "WAIT_FOR_CORE_CONFIG_DATA" 1 "APPLY_CORE_CONFIG_DATA" 0 "IDLE" ;
VAL_ 1817 VCSEC_NISessionStateRearRight1 21 "COUNT" 20 "SESSION_INITIATE" 19 "WAIT_FOR_SESSION_INITIATE" 18 "WAIT_FOR_SESSION_STATE_ACTIVE" 17 "UNRECOVERABLE_DEVICE_ERROR" 16 "ERROR_WAIT_FOR_RESET" 15 "WAIT_FOR_RETRY_AFTER_ERROR" 14 "WAIT_FOR_SESSION_DEINIT" 13 "DEINIT_SESSION" 12 "WAIT_FOR_SESSION_STOP" 11 "STOP_SESSION" 10 "RANGING" 9 "WAIT_FOR_RANGING_STARTED_CONFIRMATION" 8 "WAIT_FOR_APPLE_SESSION_INITIATE" 7 "APPLE_SESSION_INITIATE" 6 "WAIT_FOR_APPLE_SHAREABLE_CONFIGURATION_DATA" 5 "SEND_CONFIGURATION_DATA_TO_PHONE" 4 "WAIT_FOR_CONFIGURATION_DATA" 3 "REQUEST_CONFIGURATION_DATA" 2 "WAIT_FOR_CORE_CONFIG_DATA" 1 "APPLY_CORE_CONFIG_DATA" 0 "IDLE" ;
VAL_ 1817 VCSEC_NISessionStateRear1 21 "COUNT" 20 "SESSION_INITIATE" 19 "WAIT_FOR_SESSION_INITIATE" 18 "WAIT_FOR_SESSION_STATE_ACTIVE" 17 "UNRECOVERABLE_DEVICE_ERROR" 16 "ERROR_WAIT_FOR_RESET" 15 "WAIT_FOR_RETRY_AFTER_ERROR" 14 "WAIT_FOR_SESSION_DEINIT" 13 "DEINIT_SESSION" 12 "WAIT_FOR_SESSION_STOP" 11 "STOP_SESSION" 10 "RANGING" 9 "WAIT_FOR_RANGING_STARTED_CONFIRMATION" 8 "WAIT_FOR_APPLE_SESSION_INITIATE" 7 "APPLE_SESSION_INITIATE" 6 "WAIT_FOR_APPLE_SHAREABLE_CONFIGURATION_DATA" 5 "SEND_CONFIGURATION_DATA_TO_PHONE" 4 "WAIT_FOR_CONFIGURATION_DATA" 3 "REQUEST_CONFIGURATION_DATA" 2 "WAIT_FOR_CORE_CONFIG_DATA" 1 "APPLY_CORE_CONFIG_DATA" 0 "IDLE" ;
VAL_ 1817 VCSEC_NISessionStateCenter2 21 "COUNT" 20 "SESSION_INITIATE" 19 "WAIT_FOR_SESSION_INITIATE" 18 "WAIT_FOR_SESSION_STATE_ACTIVE" 17 "UNRECOVERABLE_DEVICE_ERROR" 16 "ERROR_WAIT_FOR_RESET" 15 "WAIT_FOR_RETRY_AFTER_ERROR" 14 "WAIT_FOR_SESSION_DEINIT" 13 "DEINIT_SESSION" 12 "WAIT_FOR_SESSION_STOP" 11 "STOP_SESSION" 10 "RANGING" 9 "WAIT_FOR_RANGING_STARTED_CONFIRMATION" 8 "WAIT_FOR_APPLE_SESSION_INITIATE" 7 "APPLE_SESSION_INITIATE" 6 "WAIT_FOR_APPLE_SHAREABLE_CONFIGURATION_DATA" 5 "SEND_CONFIGURATION_DATA_TO_PHONE" 4 "WAIT_FOR_CONFIGURATION_DATA" 3 "REQUEST_CONFIGURATION_DATA" 2 "WAIT_FOR_CORE_CONFIG_DATA" 1 "APPLY_CORE_CONFIG_DATA" 0 "IDLE" ;
VAL_ 1817 VCSEC_NISessionStateLeft2 21 "COUNT" 20 "SESSION_INITIATE" 19 "WAIT_FOR_SESSION_INITIATE" 18 "WAIT_FOR_SESSION_STATE_ACTIVE" 17 "UNRECOVERABLE_DEVICE_ERROR" 16 "ERROR_WAIT_FOR_RESET" 15 "WAIT_FOR_RETRY_AFTER_ERROR" 14 "WAIT_FOR_SESSION_DEINIT" 13 "DEINIT_SESSION" 12 "WAIT_FOR_SESSION_STOP" 11 "STOP_SESSION" 10 "RANGING" 9 "WAIT_FOR_RANGING_STARTED_CONFIRMATION" 8 "WAIT_FOR_APPLE_SESSION_INITIATE" 7 "APPLE_SESSION_INITIATE" 6 "WAIT_FOR_APPLE_SHAREABLE_CONFIGURATION_DATA" 5 "SEND_CONFIGURATION_DATA_TO_PHONE" 4 "WAIT_FOR_CONFIGURATION_DATA" 3 "REQUEST_CONFIGURATION_DATA" 2 "WAIT_FOR_CORE_CONFIG_DATA" 1 "APPLY_CORE_CONFIG_DATA" 0 "IDLE" ;
VAL_ 1817 VCSEC_NISessionStateRight2 21 "COUNT" 20 "SESSION_INITIATE" 19 "WAIT_FOR_SESSION_INITIATE" 18 "WAIT_FOR_SESSION_STATE_ACTIVE" 17 "UNRECOVERABLE_DEVICE_ERROR" 16 "ERROR_WAIT_FOR_RESET" 15 "WAIT_FOR_RETRY_AFTER_ERROR" 14 "WAIT_FOR_SESSION_DEINIT" 13 "DEINIT_SESSION" 12 "WAIT_FOR_SESSION_STOP" 11 "STOP_SESSION" 10 "RANGING" 9 "WAIT_FOR_RANGING_STARTED_CONFIRMATION" 8 "WAIT_FOR_APPLE_SESSION_INITIATE" 7 "APPLE_SESSION_INITIATE" 6 "WAIT_FOR_APPLE_SHAREABLE_CONFIGURATION_DATA" 5 "SEND_CONFIGURATION_DATA_TO_PHONE" 4 "WAIT_FOR_CONFIGURATION_DATA" 3 "REQUEST_CONFIGURATION_DATA" 2 "WAIT_FOR_CORE_CONFIG_DATA" 1 "APPLY_CORE_CONFIG_DATA" 0 "IDLE" ;
VAL_ 1817 VCSEC_NISessionStateRearLeft2 21 "COUNT" 20 "SESSION_INITIATE" 19 "WAIT_FOR_SESSION_INITIATE" 18 "WAIT_FOR_SESSION_STATE_ACTIVE" 17 "UNRECOVERABLE_DEVICE_ERROR" 16 "ERROR_WAIT_FOR_RESET" 15 "WAIT_FOR_RETRY_AFTER_ERROR" 14 "WAIT_FOR_SESSION_DEINIT" 13 "DEINIT_SESSION" 12 "WAIT_FOR_SESSION_STOP" 11 "STOP_SESSION" 10 "RANGING" 9 "WAIT_FOR_RANGING_STARTED_CONFIRMATION" 8 "WAIT_FOR_APPLE_SESSION_INITIATE" 7 "APPLE_SESSION_INITIATE" 6 "WAIT_FOR_APPLE_SHAREABLE_CONFIGURATION_DATA" 5 "SEND_CONFIGURATION_DATA_TO_PHONE" 4 "WAIT_FOR_CONFIGURATION_DATA" 3 "REQUEST_CONFIGURATION_DATA" 2 "WAIT_FOR_CORE_CONFIG_DATA" 1 "APPLY_CORE_CONFIG_DATA" 0 "IDLE" ;
VAL_ 1817 VCSEC_NISessionStateRearRight2 21 "COUNT" 20 "SESSION_INITIATE" 19 "WAIT_FOR_SESSION_INITIATE" 18 "WAIT_FOR_SESSION_STATE_ACTIVE" 17 "UNRECOVERABLE_DEVICE_ERROR" 16 "ERROR_WAIT_FOR_RESET" 15 "WAIT_FOR_RETRY_AFTER_ERROR" 14 "WAIT_FOR_SESSION_DEINIT" 13 "DEINIT_SESSION" 12 "WAIT_FOR_SESSION_STOP" 11 "STOP_SESSION" 10 "RANGING" 9 "WAIT_FOR_RANGING_STARTED_CONFIRMATION" 8 "WAIT_FOR_APPLE_SESSION_INITIATE" 7 "APPLE_SESSION_INITIATE" 6 "WAIT_FOR_APPLE_SHAREABLE_CONFIGURATION_DATA" 5 "SEND_CONFIGURATION_DATA_TO_PHONE" 4 "WAIT_FOR_CONFIGURATION_DATA" 3 "REQUEST_CONFIGURATION_DATA" 2 "WAIT_FOR_CORE_CONFIG_DATA" 1 "APPLY_CORE_CONFIG_DATA" 0 "IDLE" ;
VAL_ 1817 VCSEC_NISessionStateRear2 21 "COUNT" 20 "SESSION_INITIATE" 19 "WAIT_FOR_SESSION_INITIATE" 18 "WAIT_FOR_SESSION_STATE_ACTIVE" 17 "UNRECOVERABLE_DEVICE_ERROR" 16 "ERROR_WAIT_FOR_RESET" 15 "WAIT_FOR_RETRY_AFTER_ERROR" 14 "WAIT_FOR_SESSION_DEINIT" 13 "DEINIT_SESSION" 12 "WAIT_FOR_SESSION_STOP" 11 "STOP_SESSION" 10 "RANGING" 9 "WAIT_FOR_RANGING_STARTED_CONFIRMATION" 8 "WAIT_FOR_APPLE_SESSION_INITIATE" 7 "APPLE_SESSION_INITIATE" 6 "WAIT_FOR_APPLE_SHAREABLE_CONFIGURATION_DATA" 5 "SEND_CONFIGURATION_DATA_TO_PHONE" 4 "WAIT_FOR_CONFIGURATION_DATA" 3 "REQUEST_CONFIGURATION_DATA" 2 "WAIT_FOR_CORE_CONFIG_DATA" 1 "APPLY_CORE_CONFIG_DATA" 0 "IDLE" ;
VAL_ 1817 VCSEC_NISessionStateLeft3 21 "COUNT" 20 "SESSION_INITIATE" 19 "WAIT_FOR_SESSION_INITIATE" 18 "WAIT_FOR_SESSION_STATE_ACTIVE" 17 "UNRECOVERABLE_DEVICE_ERROR" 16 "ERROR_WAIT_FOR_RESET" 15 "WAIT_FOR_RETRY_AFTER_ERROR" 14 "WAIT_FOR_SESSION_DEINIT" 13 "DEINIT_SESSION" 12 "WAIT_FOR_SESSION_STOP" 11 "STOP_SESSION" 10 "RANGING" 9 "WAIT_FOR_RANGING_STARTED_CONFIRMATION" 8 "WAIT_FOR_APPLE_SESSION_INITIATE" 7 "APPLE_SESSION_INITIATE" 6 "WAIT_FOR_APPLE_SHAREABLE_CONFIGURATION_DATA" 5 "SEND_CONFIGURATION_DATA_TO_PHONE" 4 "WAIT_FOR_CONFIGURATION_DATA" 3 "REQUEST_CONFIGURATION_DATA" 2 "WAIT_FOR_CORE_CONFIG_DATA" 1 "APPLY_CORE_CONFIG_DATA" 0 "IDLE" ;
VAL_ 1817 VCSEC_NISessionStateRight3 21 "COUNT" 20 "SESSION_INITIATE" 19 "WAIT_FOR_SESSION_INITIATE" 18 "WAIT_FOR_SESSION_STATE_ACTIVE" 17 "UNRECOVERABLE_DEVICE_ERROR" 16 "ERROR_WAIT_FOR_RESET" 15 "WAIT_FOR_RETRY_AFTER_ERROR" 14 "WAIT_FOR_SESSION_DEINIT" 13 "DEINIT_SESSION" 12 "WAIT_FOR_SESSION_STOP" 11 "STOP_SESSION" 10 "RANGING" 9 "WAIT_FOR_RANGING_STARTED_CONFIRMATION" 8 "WAIT_FOR_APPLE_SESSION_INITIATE" 7 "APPLE_SESSION_INITIATE" 6 "WAIT_FOR_APPLE_SHAREABLE_CONFIGURATION_DATA" 5 "SEND_CONFIGURATION_DATA_TO_PHONE" 4 "WAIT_FOR_CONFIGURATION_DATA" 3 "REQUEST_CONFIGURATION_DATA" 2 "WAIT_FOR_CORE_CONFIG_DATA" 1 "APPLY_CORE_CONFIG_DATA" 0 "IDLE" ;
VAL_ 1817 VCSEC_NISessionStateRearRight3 21 "COUNT" 20 "SESSION_INITIATE" 19 "WAIT_FOR_SESSION_INITIATE" 18 "WAIT_FOR_SESSION_STATE_ACTIVE" 17 "UNRECOVERABLE_DEVICE_ERROR" 16 "ERROR_WAIT_FOR_RESET" 15 "WAIT_FOR_RETRY_AFTER_ERROR" 14 "WAIT_FOR_SESSION_DEINIT" 13 "DEINIT_SESSION" 12 "WAIT_FOR_SESSION_STOP" 11 "STOP_SESSION" 10 "RANGING" 9 "WAIT_FOR_RANGING_STARTED_CONFIRMATION" 8 "WAIT_FOR_APPLE_SESSION_INITIATE" 7 "APPLE_SESSION_INITIATE" 6 "WAIT_FOR_APPLE_SHAREABLE_CONFIGURATION_DATA" 5 "SEND_CONFIGURATION_DATA_TO_PHONE" 4 "WAIT_FOR_CONFIGURATION_DATA" 3 "REQUEST_CONFIGURATION_DATA" 2 "WAIT_FOR_CORE_CONFIG_DATA" 1 "APPLY_CORE_CONFIG_DATA" 0 "IDLE" ;
VAL_ 1817 VCSEC_NISessionStateRearLeft3 21 "COUNT" 20 "SESSION_INITIATE" 19 "WAIT_FOR_SESSION_INITIATE" 18 "WAIT_FOR_SESSION_STATE_ACTIVE" 17 "UNRECOVERABLE_DEVICE_ERROR" 16 "ERROR_WAIT_FOR_RESET" 15 "WAIT_FOR_RETRY_AFTER_ERROR" 14 "WAIT_FOR_SESSION_DEINIT" 13 "DEINIT_SESSION" 12 "WAIT_FOR_SESSION_STOP" 11 "STOP_SESSION" 10 "RANGING" 9 "WAIT_FOR_RANGING_STARTED_CONFIRMATION" 8 "WAIT_FOR_APPLE_SESSION_INITIATE" 7 "APPLE_SESSION_INITIATE" 6 "WAIT_FOR_APPLE_SHAREABLE_CONFIGURATION_DATA" 5 "SEND_CONFIGURATION_DATA_TO_PHONE" 4 "WAIT_FOR_CONFIGURATION_DATA" 3 "REQUEST_CONFIGURATION_DATA" 2 "WAIT_FOR_CORE_CONFIG_DATA" 1 "APPLY_CORE_CONFIG_DATA" 0 "IDLE" ;
VAL_ 1817 VCSEC_NISessionStateCenter3 21 "COUNT" 20 "SESSION_INITIATE" 19 "WAIT_FOR_SESSION_INITIATE" 18 "WAIT_FOR_SESSION_STATE_ACTIVE" 17 "UNRECOVERABLE_DEVICE_ERROR" 16 "ERROR_WAIT_FOR_RESET" 15 "WAIT_FOR_RETRY_AFTER_ERROR" 14 "WAIT_FOR_SESSION_DEINIT" 13 "DEINIT_SESSION" 12 "WAIT_FOR_SESSION_STOP" 11 "STOP_SESSION" 10 "RANGING" 9 "WAIT_FOR_RANGING_STARTED_CONFIRMATION" 8 "WAIT_FOR_APPLE_SESSION_INITIATE" 7 "APPLE_SESSION_INITIATE" 6 "WAIT_FOR_APPLE_SHAREABLE_CONFIGURATION_DATA" 5 "SEND_CONFIGURATION_DATA_TO_PHONE" 4 "WAIT_FOR_CONFIGURATION_DATA" 3 "REQUEST_CONFIGURATION_DATA" 2 "WAIT_FOR_CORE_CONFIG_DATA" 1 "APPLY_CORE_CONFIG_DATA" 0 "IDLE" ;
VAL_ 793 VCSEC_infoIndex 255 "END" 41 "SUBCOMPONENT14" 40 "SUBCOMPONENT13" 39 "SUBCOMPONENT12" 38 "SUBCOMPONENT11" 37 "SUBCOMPONENT10" 36 "SUBCOMPONENT9" 35 "SUBCOMPONENT8" 34 "SUBCOMPONENT7" 33 "SUBCOMPONENT6" 32 "SUBCOMPONENT5" 31 "SUBCOMPONENT4" 24 "SUBCOMPONENT3" 23 "SUBCOMPONENT2" 20 "UDS_PROTOCOL_BOOTCRC" 19 "VERSION_DEPRECATED" 18 "BOOTLOADER_GITHASH" 17 "APP_GITHASH" 16 "SUBCOMPONENT1" 15 "BOOTLOADER_CRC" 14 "BOOTLOADER_SVN" 13 "APP_CRC" 11 "PCBAID_ASSYID_USAGEID" 10 "BUILD_HWID_COMPONENTID" 9 "DEPRECATED_9" 8 "DEPRECATED_8" 7 "DEPRECATED_7" 6 "DEPRECATED_6" 5 "DEPRECATED_5" 4 "DEPRECATED_4" 3 "DEPRECATED_3" 2 "DEPRECATED_2" 1 "DEPRECATED_1" 0 "DEPRECATED_0" ;
VAL_ 793 VCSEC_infoBuildType 4 "INFO_MFG_BUILD" 3 "INFO_TRACEABLE_CI_BUILD" 2 "INFO_LOCAL_BUILD" 1 "INFO_PLATFORM_BUILD" 0 "INFO_UNKNOWN_BUILD" ;
VAL_ 793 VCSEC_infoAssemblyId 255 "ASSEMBLY_SNA" 1 "ASSEMBLY1" ;
VAL_ 505 VCSEC_chargePortRequest 3 "REQUEST_SNA" 2 "REQUEST_CLOSE" 1 "REQUEST_OPEN" 0 "REQUEST_NONE" ;
VAL_ 505 VCSEC_frontLeftClosureRequest 6 "POWERED_CLOSURE_REQUEST_CLOSE" 5 "POWERED_CLOSURE_REQUEST_OPEN_REDUCED" 4 "POWERED_CLOSURE_REQUEST_QUICK_OPEN" 3 "POWERED_CLOSURE_REQUEST_OPEN" 2 "POWERED_CLOSURE_REQUEST_STOP" 1 "POWERED_CLOSURE_REQUEST_MOVE" 0 "POWERED_CLOSURE_REQUEST_NONE" ;
VAL_ 505 VCSEC_frontRightClosureRequest 6 "POWERED_CLOSURE_REQUEST_CLOSE" 5 "POWERED_CLOSURE_REQUEST_OPEN_REDUCED" 4 "POWERED_CLOSURE_REQUEST_QUICK_OPEN" 3 "POWERED_CLOSURE_REQUEST_OPEN" 2 "POWERED_CLOSURE_REQUEST_STOP" 1 "POWERED_CLOSURE_REQUEST_MOVE" 0 "POWERED_CLOSURE_REQUEST_NONE" ;
VAL_ 505 VCSEC_rearLeftClosureRequest 6 "POWERED_CLOSURE_REQUEST_CLOSE" 5 "POWERED_CLOSURE_REQUEST_OPEN_REDUCED" 4 "POWERED_CLOSURE_REQUEST_QUICK_OPEN" 3 "POWERED_CLOSURE_REQUEST_OPEN" 2 "POWERED_CLOSURE_REQUEST_STOP" 1 "POWERED_CLOSURE_REQUEST_MOVE" 0 "POWERED_CLOSURE_REQUEST_NONE" ;
VAL_ 505 VCSEC_rearRightClosureRequest 6 "POWERED_CLOSURE_REQUEST_CLOSE" 5 "POWERED_CLOSURE_REQUEST_OPEN_REDUCED" 4 "POWERED_CLOSURE_REQUEST_QUICK_OPEN" 3 "POWERED_CLOSURE_REQUEST_OPEN" 2 "POWERED_CLOSURE_REQUEST_STOP" 1 "POWERED_CLOSURE_REQUEST_MOVE" 0 "POWERED_CLOSURE_REQUEST_NONE" ;
VAL_ 505 VCSEC_rearTrunkClosureRequest 6 "POWERED_CLOSURE_REQUEST_CLOSE" 5 "POWERED_CLOSURE_REQUEST_OPEN_REDUCED" 4 "POWERED_CLOSURE_REQUEST_QUICK_OPEN" 3 "POWERED_CLOSURE_REQUEST_OPEN" 2 "POWERED_CLOSURE_REQUEST_STOP" 1 "POWERED_CLOSURE_REQUEST_MOVE" 0 "POWERED_CLOSURE_REQUEST_NONE" ;
VAL_ 505 VCSEC_frontLeftRequestReason 7 "POWERED_CLOSURE_REQUEST_TAP_TO_OPEN" 6 "POWERED_CLOSURE_REQUEST_REASON_UI_REQUEST" 5 "POWERED_CLOSURE_REQUEST_UI_STOP_ALL" 4 "POWERED_CLOSURE_REQUEST_KEYFOB_UNLOCK_OPEN" 3 "POWERED_CLOSURE_REQUEST_REASON_AUTO_PRESENT" 2 "POWERED_CLOSURE_REQUEST_REASON_CLOSE_ALL" 1 "POWERED_CLOSURE_REQUEST_REASON_RKE" 0 "POWERED_CLOSURE_REQUEST_REASON_NONE" ;
VAL_ 505 VCSEC_frontRightRequestReason 7 "POWERED_CLOSURE_REQUEST_TAP_TO_OPEN" 6 "POWERED_CLOSURE_REQUEST_REASON_UI_REQUEST" 5 "POWERED_CLOSURE_REQUEST_UI_STOP_ALL" 4 "POWERED_CLOSURE_REQUEST_KEYFOB_UNLOCK_OPEN" 3 "POWERED_CLOSURE_REQUEST_REASON_AUTO_PRESENT" 2 "POWERED_CLOSURE_REQUEST_REASON_CLOSE_ALL" 1 "POWERED_CLOSURE_REQUEST_REASON_RKE" 0 "POWERED_CLOSURE_REQUEST_REASON_NONE" ;
VAL_ 505 VCSEC_rearLeftRequestReason 7 "POWERED_CLOSURE_REQUEST_TAP_TO_OPEN" 6 "POWERED_CLOSURE_REQUEST_REASON_UI_REQUEST" 5 "POWERED_CLOSURE_REQUEST_UI_STOP_ALL" 4 "POWERED_CLOSURE_REQUEST_KEYFOB_UNLOCK_OPEN" 3 "POWERED_CLOSURE_REQUEST_REASON_AUTO_PRESENT" 2 "POWERED_CLOSURE_REQUEST_REASON_CLOSE_ALL" 1 "POWERED_CLOSURE_REQUEST_REASON_RKE" 0 "POWERED_CLOSURE_REQUEST_REASON_NONE" ;
VAL_ 505 VCSEC_rearRightRequestReason 7 "POWERED_CLOSURE_REQUEST_TAP_TO_OPEN" 6 "POWERED_CLOSURE_REQUEST_REASON_UI_REQUEST" 5 "POWERED_CLOSURE_REQUEST_UI_STOP_ALL" 4 "POWERED_CLOSURE_REQUEST_KEYFOB_UNLOCK_OPEN" 3 "POWERED_CLOSURE_REQUEST_REASON_AUTO_PRESENT" 2 "POWERED_CLOSURE_REQUEST_REASON_CLOSE_ALL" 1 "POWERED_CLOSURE_REQUEST_REASON_RKE" 0 "POWERED_CLOSURE_REQUEST_REASON_NONE" ;
VAL_ 505 VCSEC_rearTrunkRequestReason 7 "POWERED_CLOSURE_REQUEST_TAP_TO_OPEN" 6 "POWERED_CLOSURE_REQUEST_REASON_UI_REQUEST" 5 "POWERED_CLOSURE_REQUEST_UI_STOP_ALL" 4 "POWERED_CLOSURE_REQUEST_KEYFOB_UNLOCK_OPEN" 3 "POWERED_CLOSURE_REQUEST_REASON_AUTO_PRESENT" 2 "POWERED_CLOSURE_REQUEST_REASON_CLOSE_ALL" 1 "POWERED_CLOSURE_REQUEST_REASON_RKE" 0 "POWERED_CLOSURE_REQUEST_REASON_NONE" ;
VAL_ 505 VCSEC_driveAttemptedWithoutAuth 10 "SHOW_B_PILLAR_NFC_CARD_TAP" 9 "SHOW_CENTER_NFC_CARD_TAP" 8 "SHOW_BRING_PHONE_CLOSER_BPILLAR_VARIANT" 7 "SHOW_BRING_PHONE_CLOSER_CENTER_VARIANT" 6 "SHOW_APP_DOWNLOAD_AND_PHONEKEY_PAIR_BPILLAR_VARIANT" 5 "SHOW_APP_DOWNLOAD_AND_PHONEKEY_PAIR_CENTER_VARIANT" 4 "SHOW_DEVICE_DISCONNECTED_GENERIC_BPILLAR_VARIANT" 3 "SHOW_DEVICE_DISCONNECTED_GENERIC_CENTER_VARIANT" 2 "SHOW_DEVICE_DISCONNECTED_IOS_BPILLAR_VARIANT" 1 "SHOW_DEVICE_DISCONNECTED_IOS_CENTER_VARIANT" 0 "NO_NFC_POPUP_DESIRED" ;
VAL_ 505 VCSEC_closeAllStatus 2 "CLOSEALL_STATE_CANCELABLE" 1 "CLOSEALL_STATE_AVAILABLE" 0 "CLOSEALL_STATE_NOT_AVAILABLE" ;
VAL_ 505 VCSEC_snapshotRequested 15 "EXTERNAL_THERMALS_HIGH" 14 "AUTO_FRUNK_FALSE_BEEP" 13 "AUTO_FRUNK" 12 "AUTHENTICATION_REJECTION_DEVICE_STATIONARY" 11 "AUTO_TRUNK" 10 "RSSI_NN_ALGO_FALSE_POSITIVE" 9 "RSSI_THRESHOLD_ALGO_FALSE_POSITIVE" 8 "RAW_RSSI_ECU_LOG_HANDLE_PULL" 7 "AUTO_TRUNK_FALSE_BEEP" 6 "UNASSIGNED_6" 5 "UNASSIGNED_5" 4 "AUTO_PRESENT_DOOR_CLOSE_WITHOUT_PEDESTRIAN_DETECTED" 3 "AUTO_PRESENT_DOOR_CLOSE_TIMEOUT" 2 "AUTHED_WITHOUT_HANDLE_PULL" 1 "HANDLE_PULL_WITHOUT_AUTH" 0 "NONE" ;
VAL_ 505 VCSEC_chargeportRequestReason 4 "VCSEC_CHARGEPORT_REQUEST_REASON_LONG_PULL_DOOR_HANDLE" 3 "VCSEC_CHARGEPORT_REQUEST_REASON_BLE_CHARGE_HANDLE" 2 "VCSEC_CHARGEPORT_REQUEST_REASON_UHF" 1 "VCSEC_CHARGEPORT_REQUEST_REASON_RKE" 0 "VCSEC_CHARGEPORT_REQUEST_REASON_NONE" ;
VAL_ 505 VCSEC_frontTrunkClosureRequest 6 "POWERED_CLOSURE_REQUEST_CLOSE" 5 "POWERED_CLOSURE_REQUEST_OPEN_REDUCED" 4 "POWERED_CLOSURE_REQUEST_QUICK_OPEN" 3 "POWERED_CLOSURE_REQUEST_OPEN" 2 "POWERED_CLOSURE_REQUEST_STOP" 1 "POWERED_CLOSURE_REQUEST_MOVE" 0 "POWERED_CLOSURE_REQUEST_NONE" ;
VAL_ 505 VCSEC_frontTrunkRequestReason 7 "POWERED_CLOSURE_REQUEST_TAP_TO_OPEN" 6 "POWERED_CLOSURE_REQUEST_REASON_UI_REQUEST" 5 "POWERED_CLOSURE_REQUEST_UI_STOP_ALL" 4 "POWERED_CLOSURE_REQUEST_KEYFOB_UNLOCK_OPEN" 3 "POWERED_CLOSURE_REQUEST_REASON_AUTO_PRESENT" 2 "POWERED_CLOSURE_REQUEST_REASON_CLOSE_ALL" 1 "POWERED_CLOSURE_REQUEST_REASON_RKE" 0 "POWERED_CLOSURE_REQUEST_REASON_NONE" ;
VAL_ 281 VCSEC_activeImmobilizerAuthLevel 3 "IMMOBILIZER_AUTH_LEVEL_MANUAL_RECOVERY" 2 "IMMOBILIZER_AUTH_LEVEL_AUTONOMY" 1 "IMMOBILIZER_AUTH_LEVEL_USER_DRIVE" 0 "IMMOBILIZER_AUTH_LEVEL_NONE" ;
VAL_ 281 VCSEC_smartTrunkLightRequest 3 "VCSEC_LIGHT_REQUEST_TYPE_DIM" 2 "VCSEC_LIGHT_REQUEST_TYPE_BLINK" 1 "VCSEC_LIGHT_REQUEST_TYPE_ON" 0 "VCSEC_LIGHT_REQUEST_TYPE_NONE" ;
VAL_ 281 VCSEC_smartTrunkSoundRequest 2 "VCSEC_SOUND_REQUEST_TYPE_NEAR" 1 "VCSEC_SOUND_REQUEST_TYPE_VICINITY" 0 "VCSEC_SOUND_REQUEST_TYPE_NONE" ;
VAL_ 281 VCSEC_chargeHandleRequestModel 8 "VCSEC_CHARGE_HANDLE_MODEL_SC_CCS2" 7 "VCSEC_CHARGE_HANDLE_MODEL_SC_NACS" 6 "VCSEC_CHARGE_HANDLE_MODEL_WC3_TYPE2" 5 "VCSEC_CHARGE_HANDLE_MODEL_UMC3_TYPE_2" 4 "VCSEC_CHARGE_HANDLE_MODEL_UMC3_GB" 3 "VCSEC_CHARGE_HANDLE_MODEL_UMC3_NACS" 2 "VCSEC_CHARGE_HANDLE_MODEL_WC3_NACS" 0 "VCSEC_CHARGE_HANDLE_MODEL_UNKNOWN" ;
VAL_ 281 VCSEC_mobileToAPRequest 4 "VCSEC_MOBILE_TO_AP_REQUEST_MAX" 2 "VCSEC_MOBILE_TO_AP_REQUEST_DISENGAGE_AUTONOMY" 1 "VCSEC_MOBILE_TO_AP_REQUEST_EMERGENCY_PULL_OVER" 0 "VCSEC_MOBILE_TO_AP_REQUEST_NONE" ;
VAL_ 1850 VC_LVBMS_brickMeasurementsMultip 2 "Mux2" 1 "Mux1" 0 "Mux0" ;
VAL_ 1850 VC_LVBMS_brickVoltage1 8191 "SNA" ;
VAL_ 1850 VC_LVBMS_brickVoltage2 8191 "SNA" ;
VAL_ 1850 VC_LVBMS_brickVoltage3 8191 "SNA" ;
VAL_ 1850 VC_LVBMS_brickVoltage4 8191 "SNA" ;
VAL_ 1850 VC_LVBMS_brickBalancingAh1 16777215 "SNA" ;
VAL_ 1850 VC_LVBMS_brickBalancingAh2 16777215 "SNA" ;
VAL_ 1850 VC_LVBMS_brickBalancingState1 1 "LVBMS_BALANCING_STATE_ACTIVE" 0 "LVBMS_BALANCING_STATE_INACTIVE" ;
VAL_ 1850 VC_LVBMS_brickBalancingState2 1 "LVBMS_BALANCING_STATE_ACTIVE" 0 "LVBMS_BALANCING_STATE_INACTIVE" ;
VAL_ 1850 VC_LVBMS_brickBalancingAh3 16777215 "SNA" ;
VAL_ 1850 VC_LVBMS_brickBalancingAh4 16777215 "SNA" ;
VAL_ 1850 VC_LVBMS_brickBalancingState3 1 "LVBMS_BALANCING_STATE_ACTIVE" 0 "LVBMS_BALANCING_STATE_INACTIVE" ;
VAL_ 1850 VC_LVBMS_brickBalancingState4 1 "LVBMS_BALANCING_STATE_ACTIVE" 0 "LVBMS_BALANCING_STATE_INACTIVE" ;
VAL_ 1655 VC_lvbmsStatusHighIndex 5 "INVALID" 4 "CELL_VITALS_2_AND_STATE_AND_COMMANDS" 3 "TARGETS" 2 "PCS_INTERFACE" 1 "CELL_VITALS_1" 0 "PACK_VITALS_1" ;
VAL_ 1655 VC_LVBMS_packCurrent 4194303 "SNA" ;
VAL_ 1655 VC_LVBMS_packVoltage 65535 "SNA" ;
VAL_ 1655 VC_LVBMS_packTemperature 511 "SNA" ;
VAL_ 1655 VC_LVBMS_MOSTemperature 4095 "SNA" ;
VAL_ 1655 VC_LVBMS_sumCellVoltage 65535 "SNA" 65534 "INVALID" ;
VAL_ 1655 VC_LVBMS_maxBrickVoltage 8191 "SNA" ;
VAL_ 1655 VC_LVBMS_maxBrickVoltageIndex 255 "SNA" ;
VAL_ 1655 VC_LVBMS_voltageTarget 65535 "SNA" ;
VAL_ 1655 VC_LVBMS_currentTarget 262143 "SNA" ;
VAL_ 1655 VC_LVBMS_maxAllowedChargeCurrent 8191 "SNA" ;
VAL_ 1655 VC_LVBMS_maxAllowedDischargeCurr 8191 "SNA" ;
VAL_ 1655 VC_LVBMS_ECPAState 3 "LVBMS_ECPA_STATE_SNA" 2 "LVBMS_ECPA_STATE_INVALID" 1 "LVBMS_ECPA_STATE_CLOSED" 0 "LVBMS_ECPA_STATE_OPEN" ;
VAL_ 1655 VC_LVBMS_MOSState 3 "LVBMS_MOS_STATE_SNA" 2 "LVBMS_MOS_STATE_INVALID" 1 "LVBMS_MOS_STATE_CLOSED" 0 "LVBMS_MOS_STATE_OPEN" ;
VAL_ 1655 VC_LVBMS_VehicleState 3 "LVBMS_VEHICLE_STATE_OFF" 2 "LVBMS_VEHICLE_STATE_CONDITIONING" 1 "LVBMS_VEHICLE_STATE_ACCESSORY" 0 "LVBMS_VEHICLE_STATE_DRIVE" ;
VAL_ 1655 VC_LVBMS_LINWakeDisabled 1 "LVBMS_LIN_WAKE_DISABLED" 0 "LVBMS_LIN_WAKE_ENABLED" ;
VAL_ 1655 VC_LVBMS_chargeType 4 "LVBMS_CHARGE_SNA" 3 "LVBMS_CHARGE_COMPLETE" 2 "LVBMS_CHARGE_CONSTANT_VOLTAGE" 1 "LVBMS_CHARGE_CONSTANT_CURRENT" 0 "LVBMS_CHARGE_UNDEFINED" ;
VAL_ 1655 VC_LVBMS_avgBrickVoltage 8191 "SNA" ;
VAL_ 1655 VC_LVBMS_minBrickVoltage 8191 "SNA" ;
VAL_ 1655 VC_LVBMS_minBrickVoltageIndex 255 "SNA" ;
VAL_ 1816 VC_lvbmsStatusLowIndex 5 "INVALID" 4 "PACK_VITALS_2" 3 "THROUGHPUT_3" 2 "THROUGHPUT_2" 1 "THROUGHPUT_1" 0 "STATE_AND_FAULTS" ;
VAL_ 1816 VC_LVBMS_SOC 1023 "SNA" ;
VAL_ 1816 VC_LVBMS_SOE 127 "SNA" ;
VAL_ 1816 VC_LVBMS_SOH 127 "SNA" ;
VAL_ 1816 VC_LVBMS_AvgSleepCurrent 65535 "SNA" ;
VAL_ 1816 VC_LVBMS_TimeSlept 16777215 "SNA" ;
VAL_ 1816 VC_LVBMS_SOP 255 "SNA" ;
VAL_ 1816 VC_LVBMS_AhCharged 4294967295 "SNA" ;
VAL_ 1816 VC_LVBMS_MinSleepCurrent 65535 "SNA" ;
VAL_ 1816 VC_LVBMS_AhDischarged 4294967295 "SNA" ;
VAL_ 1816 VC_LVBMS_MaxSleepCurrent 65535 "SNA" ;
VAL_ 1816 VC_LVBMS_sumCellVoltageFiltered 65535 "SNA" 65534 "INVALID" ;
VAL_ 1816 VC_LVBMS_maxCellSOC 1023 "SNA" ;
VAL_ 1816 VC_LVBMS_minCellSOC 1023 "SNA" ;
VAL_ 1816 VC_LVBMS_staticSOCCorrection 1 "LVBMS_CORRECTION_STATE_ACTIVE" 0 "LVBMS_CORRECTION_STATE_INACTIVE" ;
VAL_ 1816 VC_LVBMS_dynamicSOCCorrection 1 "LVBMS_CORRECTION_STATE_ACTIVE" 0 "LVBMS_CORRECTION_STATE_INACTIVE" ;
VAL_ 1816 VC_LVBMS_usableEnergyAvailable 4095 "SNA" ;
VAL_ 1816 VC_LVBMS_brakeTelltale 2 "DI_BRAKE_TELLTALE_OFF" 1 "DI_BRAKE_TELLTALE_YELLOW" 0 "DI_BRAKE_TELLTALE_RED" ;
VAL_ 1089 VC_pcsInterfaceMuxIndex 1 "1" 0 "0" ;
VAL_ 1089 VC_pcsResistanceFiltered 65535 "SNA" ;
VAL_ 1091 VC_pcsManagementMuxIndex 0 "INDEX_0" ;
VAL_ 1091 VC_dcdcLVVoltageTargetMax 1023 "UNRESTRICTED" ;
VAL_ 1091 VC_dcdcLVVoltageTargetMin 0 "UNRESTRICTED" ;
VAL_ 1091 VC_dcdcLVInputPowerLimit 255 "UNRESTRICTED" ;
